VERSION ""

NS_ :

BS_:

BU_: APIM_CISM DSP WCM HUD_ADV ACM GWM _delete APIM IPC GENERIC TSTR

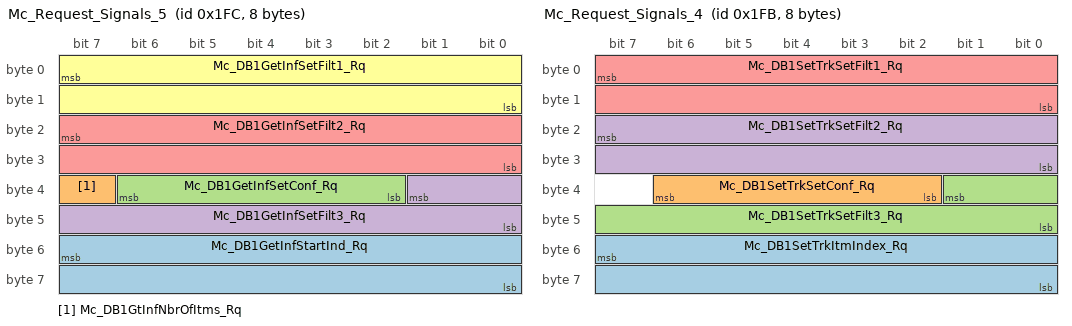
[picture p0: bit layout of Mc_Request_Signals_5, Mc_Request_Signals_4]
BO_ 508 Mc_Request_Signals_5: 8 IPC
 SG_ Mc_DB1GetInfStartInd_Rq : 55|16@0+ (1,0) [0|65535] "unitless"  ACM
 SG_ Mc_DB1GtInfNbrOfItms_Rq : 39|1@0+ (1,0) [0|1] "SED"  ACM
 SG_ Mc_DB1GetInfSetConf_Rq : 38|5@0+ (1,0) [0|31] "SED"  ACM
 SG_ Mc_DB1GetInfSetFilt3_Rq : 33|10@0+ (1,0) [0|1023] "unitless"  ACM
 SG_ Mc_DB1GetInfSetFilt2_Rq : 23|16@0+ (1,0) [0|65535] "unitless"  ACM
 SG_ Mc_DB1GetInfSetFilt1_Rq : 7|16@0+ (1,0) [0|65535] "unitless"  ACM

BO_ 507 Mc_Request_Signals_4: 8 IPC
 SG_ Mc_DB1SetTrkItmIndex_Rq : 55|16@0+ (1,0) [0|65535] "unitless"  ACM
 SG_ Mc_DB1SetTrkSetConf_Rq : 38|5@0+ (1,0) [0|31] "SED"  ACM
 SG_ Mc_DB1SetTrkSetFilt3_Rq : 33|10@0+ (1,0) [0|1023] "unitless"  ACM
 SG_ Mc_DB1SetTrkSetFilt2_Rq : 23|16@0+ (1,0) [0|65535] "unitless"  ACM
 SG_ Mc_DB1SetTrkSetFilt1_Rq : 7|16@0+ (1,0) [0|65535] "unitless"  ACM

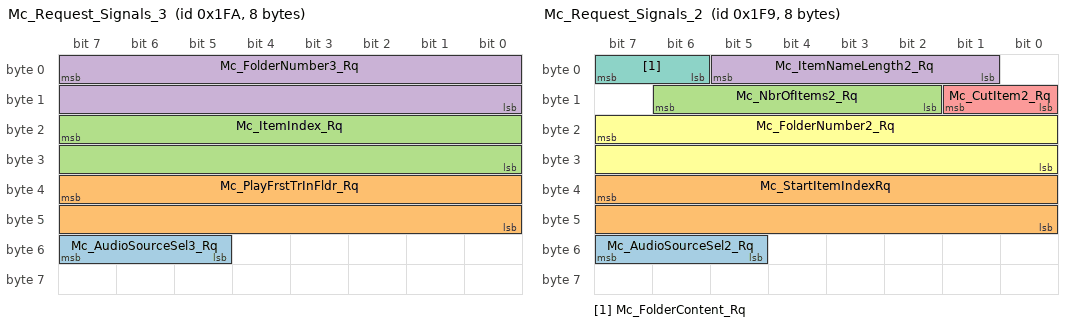
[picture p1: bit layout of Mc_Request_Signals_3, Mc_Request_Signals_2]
BO_ 506 Mc_Request_Signals_3: 8 IPC
 SG_ Mc_AudioSourceSel3_Rq : 55|3@0+ (1,0) [0|7] "SED"  ACM
 SG_ Mc_PlayFrstTrInFldr_Rq : 39|16@0+ (1,0) [0|65535] "unitless"  ACM
 SG_ Mc_ItemIndex_Rq : 23|16@0+ (1,0) [0|65535] "unitless"  ACM
 SG_ Mc_FolderNumber3_Rq : 7|16@0+ (1,0) [0|65535] "unitless"  ACM

BO_ 505 Mc_Request_Signals_2: 8 IPC
 SG_ Mc_AudioSourceSel2_Rq : 55|3@0+ (1,0) [0|7] "SED"  ACM
 SG_ Mc_StartItemIndexRq : 39|16@0+ (1,0) [0|65535] "unitless"  ACM
 SG_ Mc_NbrOfItems2_Rq : 14|5@0+ (1,0) [0|20] "SED"  ACM
 SG_ Mc_ItemNameLength2_Rq : 5|5@0+ (1,0) [0|20] "SED"  ACM
 SG_ Mc_CutItem2_Rq : 9|2@0+ (1,0) [0|3] "SED"  ACM
 SG_ Mc_FolderNumber2_Rq : 23|16@0+ (1,0) [0|65535] "unitless"  ACM
 SG_ Mc_FolderContent_Rq : 7|2@0+ (1,0) [0|3] "SED"  ACM

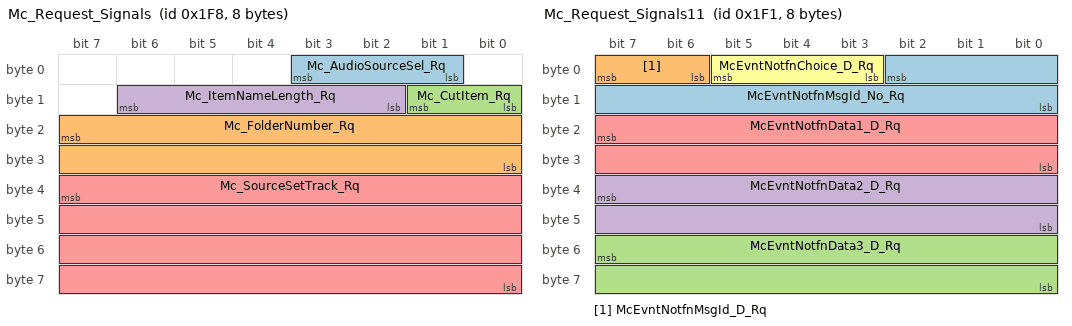
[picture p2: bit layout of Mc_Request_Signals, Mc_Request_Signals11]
BO_ 504 Mc_Request_Signals: 8 IPC
 SG_ Mc_AudioSourceSel_Rq : 3|3@0+ (1,0) [0|7] "SED"  ACM
 SG_ Mc_FolderNumber_Rq : 23|16@0+ (1,0) [0|65535] "unitless"  ACM
 SG_ Mc_CutItem_Rq : 9|2@0+ (1,0) [0|3] "SED"  ACM
 SG_ Mc_ItemNameLength_Rq : 14|5@0+ (1,0) [0|20] "SED"  ACM
 SG_ Mc_SourceSetTrack_Rq : 39|32@0+ (1,0) [0|4294967295] "unitless"  ACM

BO_ 140 CruiseCtrl_StrgData2: 8 IPC
 SG_ DcacPwResetBttn_D_Stat : 36|2@0+ (1,0) [0|3] "SED"  GWM
 SG_ CcAslButtnIndxIncPress2 : 18|1@0+ (1,0) [0|1] "SED"  GWM
 SG_ SteWhlSwtchMde_D_Stat : 23|2@0+ (1,0) [0|3] "SED"  GWM
 SG_ CcAslButtnOffCnclPress2 : 17|1@0+ (1,0) [0|1] "SED"  GWM
 SG_ CcAslButtnIndxDecPress2 : 19|1@0+ (1,0) [0|1] "SED"  GWM
 SG_ CcAslButtnCnclResPress2 : 21|1@0+ (1,0) [0|1] "SED"  GWM
 SG_ CcAslButtnResIncPress3 : 29|1@0+ (1,0) [0|1] "SED"  GWM
 SG_ CcButtnOnPress3 : 37|1@0+ (1,0) [0|1] "SED"  GWM
 SG_ CcButtnOnOffPress3 : 38|1@0+ (1,0) [0|1] "SED"  GWM
 SG_ CcButtnOnOffCnclPress3 : 39|1@0+ (1,0) [0|1] "SED"  GWM
 SG_ CcButtnOffPress3 : 24|1@0+ (1,0) [0|1] "SED"  GWM
 SG_ CcAsllButtnResPress3 : 25|1@0+ (1,0) [0|1] "SED"  GWM
 SG_ CcAslButtnSetPress3 : 26|1@0+ (1,0) [0|1] "SED"  GWM
 SG_ CcAslButtnSetIncPress3 : 27|1@0+ (1,0) [0|1] "SED"  GWM
 SG_ CcAslButtnSetDecPress3 : 28|1@0+ (1,0) [0|1] "SED"  GWM
 SG_ CcAslButtnResDecPress3 : 30|1@0+ (1,0) [0|1] "SED"  GWM
 SG_ CcAslButtnOnPress3 : 31|1@0+ (1,0) [0|1] "SED"  GWM
 SG_ CcAslButtnOnOffCncl3 : 16|1@0+ (1,0) [0|1] "SED"  GWM
 SG_ CcAslButtnDeny_B_Actl3 : 20|1@0+ (1,0) [0|1] "SED"  GWM
 SG_ CcAslButtnCnclPress3 : 8|1@0+ (1,0) [0|1] "SED"  GWM
 SG_ AslButtnOnOffPress3 : 9|1@0+ (1,0) [0|1] "SED"  GWM
 SG_ AslButtnOnOffCnclPress2 : 10|1@0+ (1,0) [0|1] "SED"  GWM

BO_ 813 TimerDisplay_Data2: 8 IPC
 SG_ TimerTripCurnt_T_Dsply : 7|26@0+ (1,0) [0|67108863] "second"  APIM

BO_ 712 NAV_MC_WORD_Rx: 8 IPC
 SG_ NAV_MC_WORD_Rx : 7|64@0+ (1,0) [0|1.84467440737096E+019] "unitless"  APIM_CISM,APIM

BO_ 711 MyKeySrvr_MyKeyClient_Word: 8 IPC
 SG_ MyKeySrvr_MyKeyClient_Word : 7|64@0+ (1,0) [0|1.84467440737096E+019] "unitless" Vector__XXX
 SG_ MyKeySrvr_Clnt_Word_Tx : 7|64@0+ (1,0) [0|1.84467440737096E+019] "unitless"  APIM

BO_ 703 CONMP_MC_WORD_Rx: 8 IPC
 SG_ CONMP_MC_WORD_Rx : 7|64@0+ (1,0) [0|1.84467440737096E+019] "unitless"  APIM_CISM,APIM

BO_ 702 PHONE_MC_WORD_Rx: 8 IPC
 SG_ PHONE_MC_WORD_Rx : 7|64@0+ (1,0) [0|1.84467440737096E+019] "unitless"  APIM_CISM,APIM

BO_ 676 MC_RDISP_WORD_Tx: 8 IPC
 SG_ MC_RDISP_WORD_Tx : 7|64@0+ (1,0) [0|1.84467440737096E+019] "unitless"  APIM_CISM,APIM

BO_ 647 HEC_DispDimm: 8 IPC
 SG_ HEC_BTIncomingCall_Rq : 23|2@0+ (1,0) [0|3] "SED"  APIM_CISM,APIM
 SG_ HEC_BTEndTelService_Rq : 3|2@0+ (1,0) [0|3] "SED"  APIM_CISM,APIM

BO_ 497 Mc_Request_Signals11: 8 IPC
 SG_ McEvntNotfnMsgId_No_Rq : 2|11@0+ (1,0) [0|2047] "unitless"  APIM
 SG_ McEvntNotfnMsgId_D_Rq : 7|2@0+ (1,0) [0|3] "SED"  APIM
 SG_ McEvntNotfnData3_D_Rq : 55|16@0+ (1,0) [0|65535] "unitless"  APIM
 SG_ McEvntNotfnData2_D_Rq : 39|16@0+ (1,0) [0|65535] "unitless"  APIM
 SG_ McEvntNotfnData1_D_Rq : 23|16@0+ (1,0) [0|65535] "unitless"  APIM
 SG_ McEvntNotfnChoice_D_Rq : 5|3@0+ (1,0) [0|7] "SED"  APIM

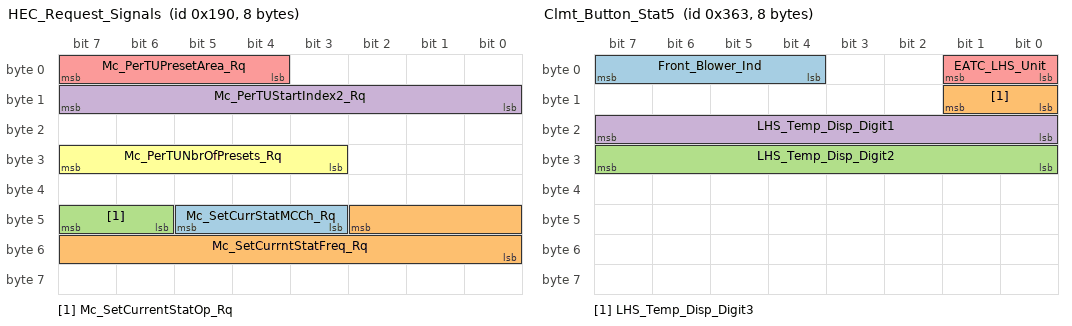
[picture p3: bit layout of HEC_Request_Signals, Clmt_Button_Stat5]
BO_ 400 HEC_Request_Signals: 8 IPC
 SG_ Mc_SetCurrStatMCCh_Rq : 45|3@0+ (1,0) [0|7] "SED"  ACM,GWM
 SG_ Mc_SetCurrntStatFreq_Rq : 42|11@0+ (1,0) [0|1557] "unitless"  ACM,GWM
 SG_ Mc_SetCurrentStatOp_Rq : 47|2@0+ (1,0) [0|3] "SED"  ACM,GWM
 SG_ Mc_PerTUStartIndex2_Rq : 15|8@0+ (1,0) [0|255] "unitless"  ACM,GWM,APIM
 SG_ Mc_PerTUPresetArea_Rq : 7|4@0+ (1,0) [0|15] "SED"  ACM,GWM,APIM
 SG_ Mc_PerTUNbrOfPresets_Rq : 31|5@0+ (1,0) [0|31] "SED"  ACM,GWM,APIM

BO_ 598 CONMP_RSE_WORD_Tx: 8 APIM
 SG_ CONMP_RSE_WORD_Tx : 7|64@0+ (1,0) [0|1.84467440737096E+019] "unitless" Vector__XXX

BO_ 867 Clmt_Button_Stat5: 8 IPC
 SG_ Front_Blower_Ind : 7|4@0+ (1,0) [0|15] "SED"  GWM,HUD_ADV
 SG_ LHS_Temp_Disp_Digit3 : 9|2@0+ (1,0) [0|3] "SED"  GWM,HUD_ADV
 SG_ LHS_Temp_Disp_Digit2 : 31|8@0+ (1,0) [0|255] "ASCII"  GWM,HUD_ADV
 SG_ LHS_Temp_Disp_Digit1 : 23|8@0+ (1,0) [0|255] "ASCII"  GWM,HUD_ADV
 SG_ EATC_LHS_Unit : 1|2@0+ (1,0) [0|3] "SED"  GWM,HUD_ADV

BO_ 831 Pass_Mirror_Sw_StatM: 8 GWM
 SG_ RearDriverWindowPos : 23|3@0+ (1,0) [0|7] "SED"  WCM
 SG_ DriverWindowPosition : 3|3@0+ (1,0) [0|7] "SED"  WCM

BO_ 862 Climate_Control_Data_2: 8 GWM
 SG_ HvacBlwrFront_D_Stat : 55|5@0+ (1,0) [0|31] "SED"  WCM
 SG_ CabnAmb_Te_Actl : 39|8@0+ (0.5,-57) [-57|70] "degreesC"  WCM

BO_ 828 Pass_Window_Stat: 8 GWM
 SG_ RearPassWindowPos : 4|3@0+ (1,0) [0|7] "SED"  WCM
 SG_ PassWindowPosition : 7|3@0+ (1,0) [0|7] "SED"  WCM

BO_ 645 ECG_Data5_HS3: 8 GWM
 SG_ VehImpactCode_No2_Actl : 7|16@0+ (1,0) [0|65535] "unitless"  APIM

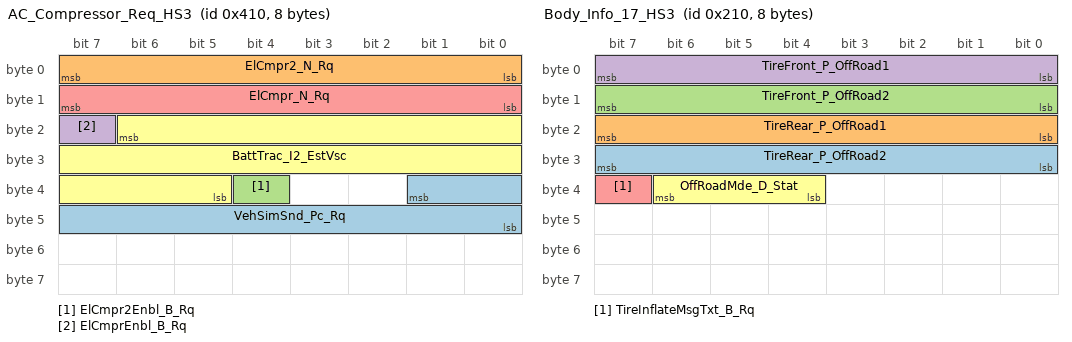
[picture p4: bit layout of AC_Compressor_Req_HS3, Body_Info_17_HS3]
BO_ 1040 AC_Compressor_Req_HS3: 8 GWM
 SG_ VehSimSnd_Pc_Rq : 33|10@0+ (0.2,-102.2) [-102.2|102.4] "percent"  ACM
 SG_ ElCmpr2_N_Rq : 7|8@0+ (50,0) [0|12750] "RPM" Vector__XXX
 SG_ ElCmpr2Enbl_B_Rq : 36|1@0+ (1,0) [0|1] "SED" Vector__XXX
 SG_ ElCmprEnbl_B_Rq : 23|1@0+ (1,0) [0|1] "SED" Vector__XXX
 SG_ ElCmpr_N_Rq : 15|8@0+ (50,0) [0|12750] "RPM" Vector__XXX
 SG_ BattTrac_I2_EstVsc : 22|18@0+ (0.05,-6553.52) [-6553.52|6553.53] "ampere" Vector__XXX

BO_ 528 Body_Info_17_HS3: 8 GWM
 SG_ TireRear_P_OffRoad2 : 31|8@0+ (1,0) [0|255] "pounds/inch^2"  IPC
 SG_ TireRear_P_OffRoad1 : 23|8@0+ (1,0) [0|255] "pounds/inch^2"  IPC
 SG_ TireFront_P_OffRoad2 : 15|8@0+ (1,0) [0|255] "pounds/inch^2"  IPC
 SG_ TireFront_P_OffRoad1 : 7|8@0+ (1,0) [0|255] "pounds/inch^2"  IPC
 SG_ TireInflateMsgTxt_B_Rq : 39|1@0+ (1,0) [0|1] "SED"  IPC
 SG_ OffRoadMde_D_Stat : 38|3@0+ (1,0) [0|7] "SED"  IPC

BO_ 1221 HEV_Data_Monitor_22_HS3: 8 GWM
 SG_ BattTracUMxArry_No_Actl : 52|5@0+ (1,0) [0|30] "unitless"  GENERIC
 SG_ BattTracCellUMx_No_Actl : 63|8@0+ (1,0) [0|253] "Unitless"  GENERIC
 SG_ BattChrgUMx_B_Falt : 53|1@0+ (1,0) [0|1] "SED"  GENERIC
 SG_ BattTracCellUMn_No_Actl : 15|8@0+ (1,0) [0|253] "Unitless"  GENERIC
 SG_ BattTracCellCnt_No_Actl : 7|8@0+ (1,0) [0|253] "Unitless"  GENERIC
 SG_ BattChrgIsltn_B_Falt : 47|1@0+ (1,0) [0|1] "SED"  GENERIC
 SG_ BattTracCellDiff_B_Falt : 43|1@0+ (1,0) [0|1] "SED"  GENERIC
 SG_ BattChrgSocMx_B_Falt : 44|1@0+ (1,0) [0|1] "SED"  APIM
 SG_ BattChrgSocMn_B_Falt : 45|1@0+ (1,0) [0|1] "SED"  APIM
 SG_ BattChrgSocErrtc_B_Falt : 46|1@0+ (1,0) [0|1] "SED"  GENERIC
 SG_ BattTracUMx_B_Falt : 54|1@0+ (1,0) [0|1] "SED"  GENERIC
 SG_ BattTracUMn_B_Falt : 55|1@0+ (1,0) [0|1] "SED"  GENERIC
 SG_ BattTracTeMx_No_Actl : 39|8@0+ (1,0) [0|253] "Unitless"  GENERIC
 SG_ BattTracTeMx_B_Falt : 40|1@0+ (1,0) [0|1] "SED"  GENERIC
 SG_ BattTracTeMn_No_Actl : 31|8@0+ (1,0) [0|253] "Unitless"  GENERIC
 SG_ BattTracTeDelta_B_Falt : 41|1@0+ (1,0) [0|1] "SED"  GENERIC
 SG_ BattTracTeCnt_No_Actl : 23|8@0+ (1,0) [0|253] "Unitless"  GENERIC
 SG_ BattTracSoftware_B_Falt : 42|1@0+ (1,0) [0|1] "SED"  GENERIC

BO_ 595 APIM_Send_Signals_7: 8 APIM
 SG_ DrvIdMde_D_Rq : 7|3@0+ (1,0) [0|7] "SED"  GWM
 SG_ DrvIdDelete_No_Rq : 15|32@0+ (1,0) [0|4294967295] "Unitless"  GWM

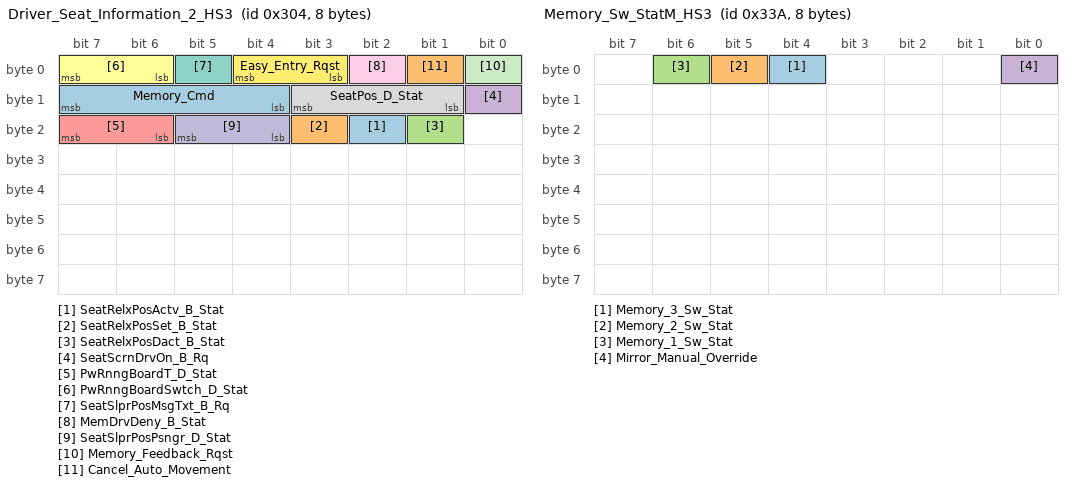
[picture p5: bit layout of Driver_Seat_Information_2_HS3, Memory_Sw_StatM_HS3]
BO_ 772 Driver_Seat_Information_2_HS3: 8 GWM
 SG_ SeatRelxPosActv_B_Stat : 18|1@0+ (1,0) [0|1] "SED"  APIM_CISM
 SG_ SeatRelxPosSet_B_Stat : 19|1@0+ (1,0) [0|1] "SED"  APIM_CISM
 SG_ SeatRelxPosDact_B_Stat : 17|1@0+ (1,0) [0|1] "SED"  APIM_CISM
 SG_ SeatScrnDrvOn_B_Rq : 8|1@0+ (1,0) [0|1] "SED"  GENERIC
 SG_ PwRnngBoardT_D_Stat : 23|2@0+ (1,0) [0|3] "SED"  GENERIC
 SG_ PwRnngBoardSwtch_D_Stat : 7|2@0+ (1,0) [0|3] "SED"  GENERIC
 SG_ SeatSlprPosMsgTxt_B_Rq : 5|1@0+ (1,0) [0|1] "SED"  GENERIC
 SG_ SeatPos_D_Stat : 11|3@0+ (1,0) [0|7] "SED"  GENERIC
 SG_ MemDrvDeny_B_Stat : 2|1@0+ (1,0) [0|1] "SED"  GENERIC
 SG_ SeatSlprPosPsngr_D_Stat : 21|2@0+ (1,0) [0|3] "SED"  GENERIC
 SG_ Memory_Feedback_Rqst : 0|1@0+ (1,0) [0|1] "SED"  GENERIC
 SG_ Easy_Entry_Rqst : 4|2@0+ (1,0) [0|3] "SED"  GENERIC
 SG_ Memory_Cmd : 15|4@0+ (1,0) [0|15] "SED"  HUD_ADV,GENERIC
 SG_ Cancel_Auto_Movement : 1|1@0+ (1,0) [0|1] "SED"  APIM_CISM,GENERIC

BO_ 826 Memory_Sw_StatM_HS3: 8 GWM
 SG_ Memory_3_Sw_Stat : 4|1@0+ (1,0) [0|1] "SED"  GENERIC
 SG_ Memory_2_Sw_Stat : 5|1@0+ (1,0) [0|1] "SED"  GENERIC
 SG_ Memory_1_Sw_Stat : 6|1@0+ (1,0) [0|1] "SED"  GENERIC
 SG_ Mirror_Manual_Override : 0|1@0+ (1,0) [0|1] "SED"  APIM_CISM,GENERIC

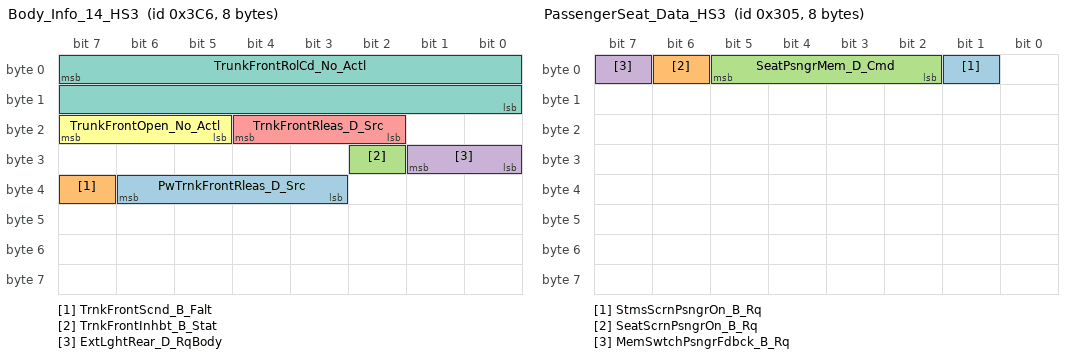
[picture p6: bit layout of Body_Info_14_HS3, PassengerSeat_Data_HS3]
BO_ 966 Body_Info_14_HS3: 8 GWM
 SG_ PwTrnkFrontRleas_D_Src : 38|4@0+ (1,0) [0|15] "SED"  GENERIC
 SG_ TrnkFrontScnd_B_Falt : 39|1@0+ (1,0) [0|1] "SED"  IPC
 SG_ TrnkFrontInhbt_B_Stat : 26|1@0+ (1,0) [0|1] "SED"  GENERIC
 SG_ ExtLghtRear_D_RqBody : 25|2@0- (1,0) [0|3] "SED"  GENERIC
 SG_ TrnkFrontRleas_D_Src : 20|3@0+ (1,0) [0|7] "SED"  GENERIC
 SG_ TrunkFrontOpen_No_Actl : 23|3@0+ (1,0) [0|7] "unitless"  GENERIC
 SG_ TrunkFrontRolCd_No_Actl : 7|16@0+ (1,0) [0|65535] "unitless"  GENERIC

BO_ 773 PassengerSeat_Data_HS3: 8 GWM
 SG_ StmsScrnPsngrOn_B_Rq : 1|1@0+ (1,0) [0|1] "SED"  APIM
 SG_ SeatScrnPsngrOn_B_Rq : 6|1@0+ (1,0) [0|1] "SED"  GENERIC
 SG_ SeatPsngrMem_D_Cmd : 5|4@0+ (1,0) [0|15] "SED"  GENERIC
 SG_ MemSwtchPsngrFdbck_B_Rq : 7|1@0+ (1,0) [0|1] "SED"  GENERIC

BO_ 303 Body_Info_16_HS3: 8 GWM
 SG_ CanMsg12F_No_Crc : 7|8@0+ (1,0) [0|255] "Unitless"  GENERIC
 SG_ CanMsg12F_No_Cnt : 11|4@0+ (1,0) [0|15] "Unitless"  GENERIC
 SG_ DrStatHood_D2_Actl : 23|3@0+ (1,0) [0|7] "SED"  IPC

BO_ 2612009176 PARSEDPushFcGWM_ECGtoHUD: 8 GWM
 SG_ PARSEDPushFcGWM_ECGtoHUD : 7|29@0+ (1,0) [0|536870911] "unitless"  HUD_ADV

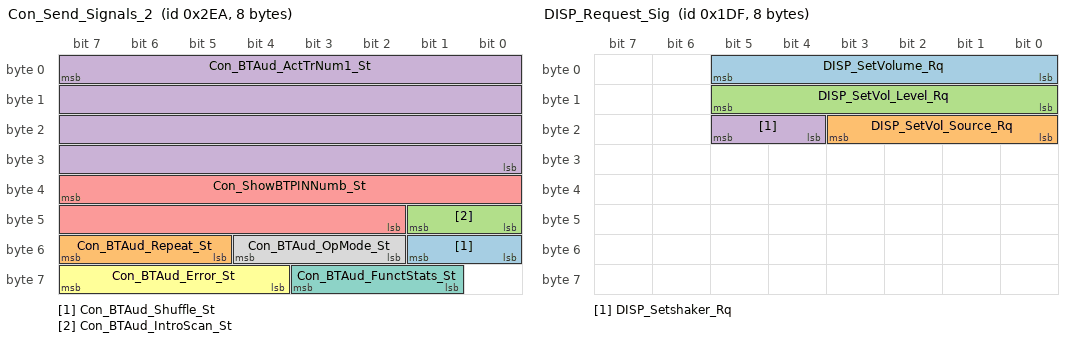
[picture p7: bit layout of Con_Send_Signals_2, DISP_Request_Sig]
BO_ 746 Con_Send_Signals_2: 8 ACM
 SG_ Con_BTAud_Shuffle_St : 49|2@0+ (1,0) [0|3] "SED"  IPC
 SG_ Con_BTAud_Repeat_St : 55|3@0+ (1,0) [0|7] "SED"  IPC
 SG_ Con_BTAud_IntroScan_St : 41|2@0+ (1,0) [0|3] "SED"  IPC
 SG_ Con_BTAud_ActTrNum1_St : 7|32@0+ (1,0) [0|4294967295] ""  IPC
 SG_ Con_ShowBTPINNumb_St : 39|14@0+ (1,0) [0|16383] ""  IPC
 SG_ Con_BTAud_Error_St : 63|4@0+ (1,0) [0|15] "SED" Vector__XXX
 SG_ Con_BTAud_FunctStats_St : 59|3@0+ (1,0) [0|7] "SED"  IPC
 SG_ Con_BTAud_OpMode_St : 52|3@0+ (1,0) [0|7] "SED"  IPC

BO_ 479 DISP_Request_Sig: 8 APIM
 SG_ DISP_SetVolume_Rq : 5|6@0+ (1,-30) [-30|33] "steps"  ACM,DSP,GWM
 SG_ DISP_SetVol_Source_Rq : 19|4@0+ (1,0) [0|15] "SED"  IPC,ACM,DSP
 SG_ DISP_SetVol_Level_Rq : 13|6@0+ (1,0) [0|63] "unitless"  ACM,DSP
 SG_ DISP_Setshaker_Rq : 21|2@0+ (1,0) [0|3] "SED"  ACM,DSP

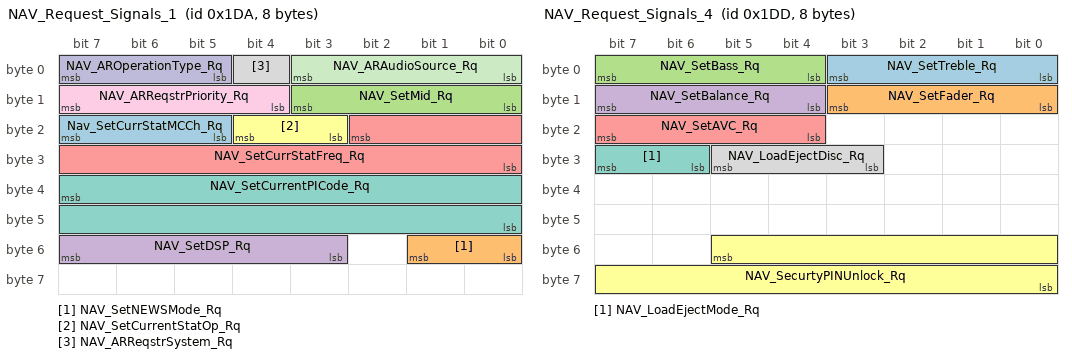
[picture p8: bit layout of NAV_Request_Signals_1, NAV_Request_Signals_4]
BO_ 474 NAV_Request_Signals_1: 8 APIM
 SG_ Nav_SetCurrStatMCCh_Rq : 23|3@0+ (1,0) [0|7] "SED"  ACM
 SG_ NAV_SetNEWSMode_Rq : 49|2@0+ (1,0) [0|3] "SED"  ACM
 SG_ NAV_SetMid_Rq : 11|4@0+ (1,-7) [-7|8] "SED"  DSP,ACM
 SG_ NAV_SetDSP_Rq : 55|5@0+ (1,0) [0|31] "SED"  ACM
 SG_ NAV_SetCurrStatFreq_Rq : 18|11@0+ (1,0) [0|1557] "unitless"  ACM
 SG_ NAV_SetCurrentStatOp_Rq : 20|2@0+ (1,0) [0|3] "SED"  ACM
 SG_ NAV_SetCurrentPICode_Rq : 39|16@0+ (1,0) [0|65535] "unitless"  ACM
 SG_ NAV_ARReqstrSystem_Rq : 4|1@0+ (1,0) [0|1] "SED"  DSP,ACM
 SG_ NAV_ARReqstrPriority_Rq : 15|4@0+ (1,0) [0|15] "SED"  DSP,ACM
 SG_ NAV_AROperationType_Rq : 7|3@0+ (1,0) [0|7] "SED"  DSP,ACM
 SG_ NAV_ARAudioSource_Rq : 3|4@0+ (1,0) [0|15] "SED"  DSP,ACM

BO_ 477 NAV_Request_Signals_4: 8 APIM
 SG_ NAV_SetTreble_Rq : 3|4@0+ (1,-7) [-7|8] "SED"  ACM,DSP
 SG_ NAV_SetFader_Rq : 11|4@0+ (1,-7) [-7|8] "SED"  ACM,DSP
 SG_ NAV_SetBass_Rq : 7|4@0+ (1,-7) [-7|8] "SED"  ACM,DSP
 SG_ NAV_SetBalance_Rq : 15|4@0+ (1,-7) [-7|8] "SED"  ACM,DSP
 SG_ NAV_SetAVC_Rq : 23|4@0+ (1,0) [0|15] "SED"  ACM,DSP
 SG_ NAV_SecurtyPINUnlock_Rq : 53|14@0+ (1,0) [0|16383] "unitless"  ACM
 SG_ NAV_LoadEjectMode_Rq : 31|2@0+ (1,0) [0|3] "SED"  ACM
 SG_ NAV_LoadEjectDisc_Rq : 29|3@0+ (1,0) [0|7] "SED"  ACM

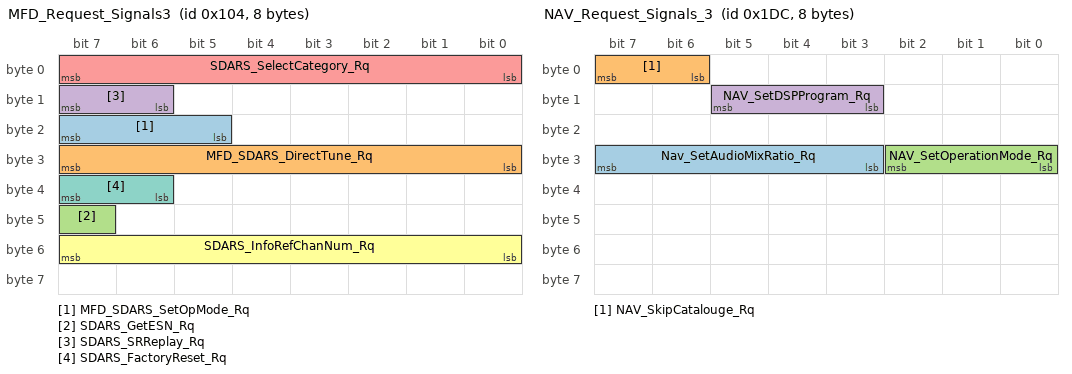
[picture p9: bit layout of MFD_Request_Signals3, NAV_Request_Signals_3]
BO_ 260 MFD_Request_Signals3: 8 APIM
 SG_ MFD_SDARS_SetOpMode_Rq : 23|3@0+ (1,0) [0|7] "SED"  ACM
 SG_ MFD_SDARS_DirectTune_Rq : 31|8@0+ (1,0) [0|255] "unitless"  ACM
 SG_ SDARS_GetESN_Rq : 47|1@0+ (1,0) [0|1] "SED"  ACM
 SG_ SDARS_SRReplay_Rq : 15|2@0+ (1,0) [0|3] "SED"  ACM
 SG_ SDARS_SelectCategory_Rq : 7|8@0+ (1,0) [0|255] "unitless"  ACM
 SG_ SDARS_InfoRefChanNum_Rq : 55|8@0+ (1,0) [0|255] "unitless"  ACM
 SG_ SDARS_FactoryReset_Rq : 39|2@0+ (1,0) [0|3] "SED"  DSP,ACM

BO_ 476 NAV_Request_Signals_3: 8 APIM
 SG_ Nav_SetAudioMixRatio_Rq : 31|5@0+ (1,0) [0|20] "decibel"  ACM
 SG_ NAV_SkipCatalouge_Rq : 7|2@0+ (1,0) [0|3] "SED"  ACM
 SG_ NAV_SetOperationMode_Rq : 26|3@0+ (1,0) [0|7] "SED"  ACM
 SG_ NAV_SetDSPProgram_Rq : 13|3@0+ (1,0) [0|7] "SED"  ACM

BO_ 490 HMI_Request_Signals_2: 8 APIM
 SG_ HMI_SetCompression_Rq : 9|2@0+ (1,0) [0|3] "SED"  ACM
 SG_ HMI_SkipTrack_Rq : 35|2@0+ (1,0) [0|3] "SED"  ACM

BO_ 1923 TesterPhysicalReqDSP: 8 TSTR
 SG_ TesterPhysicalReqDSP : 7|64@0+ (1,0) [0|1.84467E+019] "unitless"  DSP

BO_ 1931 TesterPhysicalResDSP: 8 DSP
 SG_ TesterPhysicalResDSP : 7|64@0+ (1,0) [0|1.84467E+019] "unitless"  TSTR

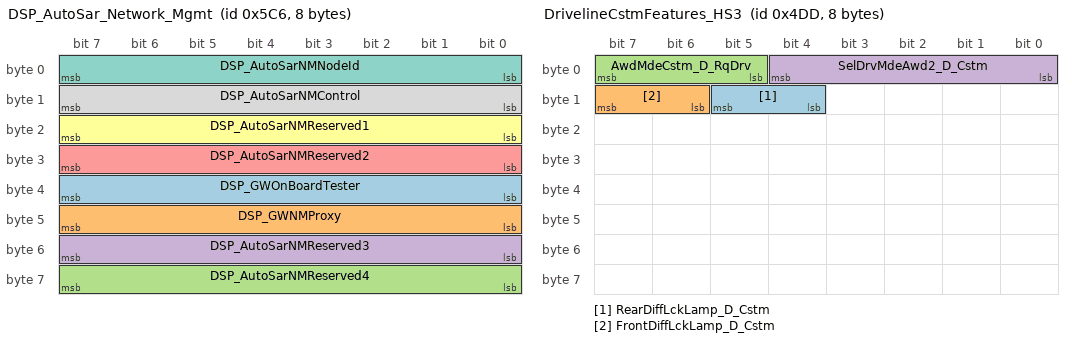
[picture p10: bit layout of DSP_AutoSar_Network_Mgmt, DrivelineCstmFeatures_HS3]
BO_ 1478 DSP_AutoSar_Network_Mgmt: 8 DSP
 SG_ DSP_GWOnBoardTester : 39|8@0+ (1,0) [0|255] "unitless"  IPC,HUD_ADV
 SG_ DSP_GWNMProxy : 47|8@0+ (1,0) [0|255] "unitless"  IPC,HUD_ADV
 SG_ DSP_AutoSarNMReserved4 : 63|8@0+ (1,0) [0|255] "unitless"  IPC,HUD_ADV
 SG_ DSP_AutoSarNMReserved3 : 55|8@0+ (1,0) [0|255] "unitless"  IPC,HUD_ADV
 SG_ DSP_AutoSarNMReserved2 : 31|8@0+ (1,0) [0|255] "unitless"  IPC,HUD_ADV
 SG_ DSP_AutoSarNMReserved1 : 23|8@0+ (1,0) [0|255] "unitless"  IPC,HUD_ADV
 SG_ DSP_AutoSarNMNodeId : 7|8@0+ (1,0) [0|255] "unitless"  IPC,HUD_ADV
 SG_ DSP_AutoSarNMControl : 15|8@0+ (1,0) [0|255] "unitless"  IPC,HUD_ADV

BO_ 1245 DrivelineCstmFeatures_HS3: 8 GWM
 SG_ RearDiffLckLamp_D_Cstm : 13|2@0+ (1,0) [0|3] "SED"  IPC
 SG_ FrontDiffLckLamp_D_Cstm : 15|2@0+ (1,0) [0|3] "SED"  IPC
 SG_ AwdMdeCstm_D_RqDrv : 7|3@0+ (1,0) [0|7] "SED"  IPC
 SG_ SelDrvMdeAwd2_D_Cstm : 4|5@0+ (1,0) [0|31] "SED"  GENERIC

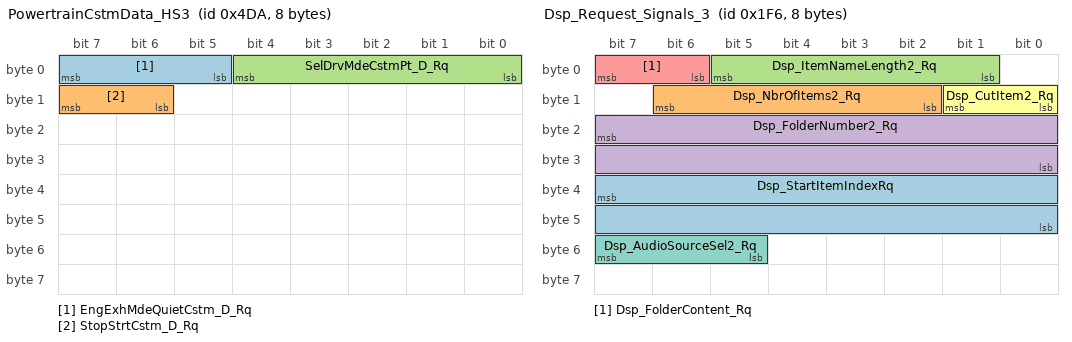
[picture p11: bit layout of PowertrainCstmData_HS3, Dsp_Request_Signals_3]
BO_ 1242 PowertrainCstmData_HS3: 8 GWM
 SG_ EngExhMdeQuietCstm_D_Rq : 7|3@0+ (1,0) [0|7] "SED"  IPC
 SG_ StopStrtCstm_D_Rq : 15|2@0+ (1,0) [0|3] "SED"  IPC
 SG_ SelDrvMdeCstmPt_D_Rq : 4|5@0+ (1,0) [0|31] "SED"  GENERIC

BO_ 502 Dsp_Request_Signals_3: 8 APIM
 SG_ Dsp_StartItemIndexRq : 39|16@0+ (1,0) [0|65535] "unitless"  ACM
 SG_ Dsp_NbrOfItems2_Rq : 14|5@0+ (1,0) [0|20] "SED"  ACM
 SG_ Dsp_ItemNameLength2_Rq : 5|5@0+ (1,0) [0|20] "SED"  ACM
 SG_ Dsp_FolderNumber2_Rq : 23|16@0+ (1,0) [0|65535] "unitless"  ACM
 SG_ Dsp_FolderContent_Rq : 7|2@0+ (1,0) [0|3] "SED"  ACM
 SG_ Dsp_CutItem2_Rq : 9|2@0+ (1,0) [0|3] "SED"  ACM
 SG_ Dsp_AudioSourceSel2_Rq : 55|3@0+ (1,0) [0|7] "SED"  ACM

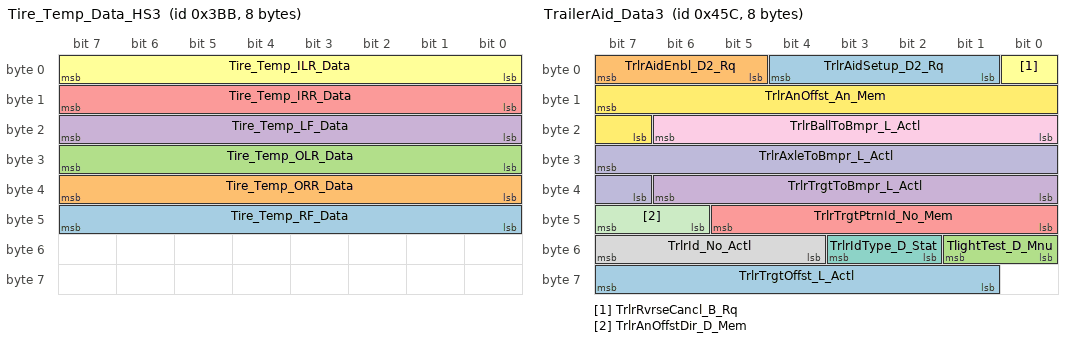
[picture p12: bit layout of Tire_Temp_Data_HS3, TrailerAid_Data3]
BO_ 955 Tire_Temp_Data_HS3: 8 GWM
 SG_ Tire_Temp_RF_Data : 47|8@0+ (1,-60) [-60|193] "degC"  IPC,APIM
 SG_ Tire_Temp_ORR_Data : 39|8@0+ (1,-60) [-60|193] "degC"  IPC,APIM
 SG_ Tire_Temp_OLR_Data : 31|8@0+ (1,-60) [-60|193] "degC"  IPC,APIM
 SG_ Tire_Temp_LF_Data : 23|8@0+ (1,-60) [-60|193] "degC"  IPC,APIM
 SG_ Tire_Temp_IRR_Data : 15|8@0+ (1,-60) [-60|193] "degC"  IPC,APIM
 SG_ Tire_Temp_ILR_Data : 7|8@0+ (1,-60) [-60|193] "degC"  IPC,APIM

BO_ 1116 TrailerAid_Data3: 8 APIM
 SG_ TrlrAidSetup_D2_Rq : 4|4@0+ (1,0) [0|15] "SED"  GWM
 SG_ TrlrAidEnbl_D2_Rq : 7|3@0+ (1,0) [0|7] "SED"  GWM
 SG_ TlightTest_D_Mnu : 49|2@0+ (1,0) [0|3] "SED"  GWM
 SG_ TrlrTrgtToBmpr_L_Actl : 38|7@0+ (0.0127,0) [0|1.6129] "meter"  GWM
 SG_ TrlrTrgtPtrnId_No_Mem : 45|6@0+ (1,0) [0|63] "unitless"  GWM
 SG_ TrlrRvrseCancl_B_Rq : 0|1@0+ (1,0) [0|1] "SED"  GWM
 SG_ TrlrIdType_D_Stat : 51|2@0+ (1,0) [0|3] "SED"  GWM
 SG_ TrlrId_No_Actl : 55|4@0+ (1,0) [0|15] "unitless"  GWM
 SG_ TrlrBallToBmpr_L_Actl : 22|7@0+ (0.0127,0) [0|1.6129] "meter"  GWM
 SG_ TrlrAxleToBmpr_L_Actl : 31|9@0+ (0.0254,0) [0|12.9794] "meter"  GWM
 SG_ TrlrAnOffstDir_D_Mem : 47|2@0+ (1,0) [0|3] "SED"  GWM
 SG_ TrlrAnOffst_An_Mem : 15|9@0+ (0.1,0) [0|51.1] "degrees"  GWM
 SG_ TrlrTrgtOffst_L_Actl : 63|7@0+ (0.0127,0) [0|1.6129] "meter"  GWM

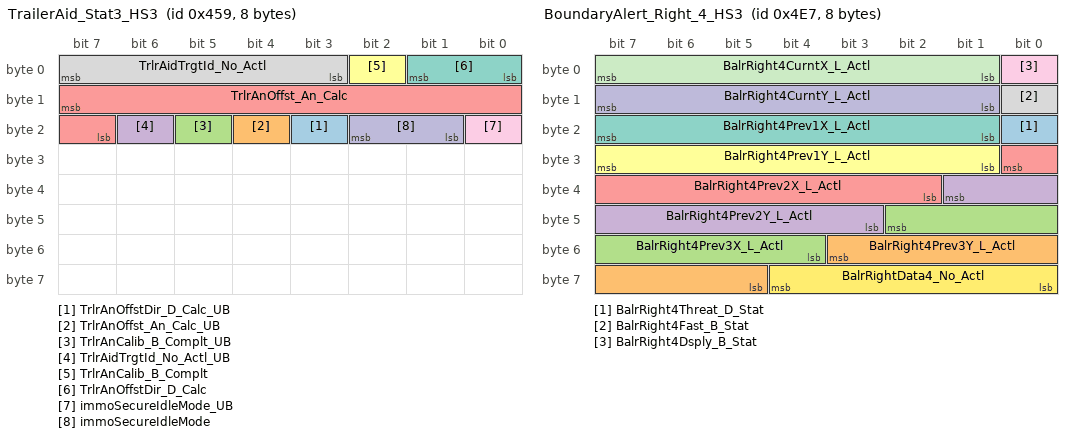
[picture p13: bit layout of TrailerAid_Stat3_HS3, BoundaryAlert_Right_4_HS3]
BO_ 1113 TrailerAid_Stat3_HS3: 8 GWM
 SG_ TrlrAnOffstDir_D_Calc_UB : 19|1@0+ (1,0) [0|1] "SED"  IPC,APIM
 SG_ TrlrAnOffst_An_Calc_UB : 20|1@0+ (1,0) [0|1] "SED"  IPC,APIM
 SG_ TrlrAnCalib_B_Complt_UB : 21|1@0+ (1,0) [0|1] "SED"  IPC,APIM
 SG_ TrlrAidTrgtId_No_Actl_UB : 22|1@0+ (1,0) [0|1] "SED"  IPC,APIM
 SG_ TrlrAnOffst_An_Calc : 15|9@0+ (0.1,0) [0|51.1] "degrees"  IPC,APIM
 SG_ TrlrAnCalib_B_Complt : 2|1@0+ (1,0) [0|1] "SED"  IPC,APIM
 SG_ TrlrAnOffstDir_D_Calc : 1|2@0+ (1,0) [0|3] "SED"  IPC,APIM
 SG_ TrlrAidTrgtId_No_Actl : 7|5@0+ (1,0) [0|31] "unitless"  IPC,APIM
 SG_ immoSecureIdleMode_UB : 16|1@0+ (1,0) [0|1] "SED"  APIM_CISM,IPC,APIM
 SG_ immoSecureIdleMode : 18|2@0+ (1,0) [0|3] "SED"  APIM_CISM,IPC,APIM

BO_ 1255 BoundaryAlert_Right_4_HS3: 8 GWM
 SG_ BalrRight4Threat_D_Stat : 16|1@0+ (1,0) [0|1] "SED"  IPC
 SG_ BalrRight4Prev3Y_L_Actl : 51|7@0+ (0.5,-32) [-32|31.5] "meter"  IPC
 SG_ BalrRight4Prev3X_L_Actl : 42|7@0+ (0.5,-32) [-32|31.5] "meter"  IPC
 SG_ BalrRight4Prev2Y_L_Actl : 33|7@0+ (0.5,-32) [-32|31.5] "meter"  IPC
 SG_ BalrRight4Prev2X_L_Actl : 24|7@0+ (0.5,-32) [-32|31.5] "meter"  IPC
 SG_ BalrRight4Prev1Y_L_Actl : 31|7@0+ (0.5,-32) [-32|31.5] "meter"  IPC
 SG_ BalrRight4Prev1X_L_Actl : 23|7@0+ (0.5,-32) [-32|31.5] "meter"  IPC
 SG_ BalrRight4Fast_B_Stat : 8|1@0+ (1,0) [0|1] "SED"  IPC
 SG_ BalrRight4Dsply_B_Stat : 0|1@0+ (1,0) [0|1] "SED"  IPC
 SG_ BalrRight4CurntY_L_Actl : 15|7@0+ (0.5,-32) [-32|31.5] "meter"  IPC
 SG_ BalrRight4CurntX_L_Actl : 7|7@0+ (0.5,-32) [-32|31.5] "meter"  IPC
 SG_ BalrRightData4_No_Actl : 60|5@0+ (1,0) [0|31] "unitless"  IPC

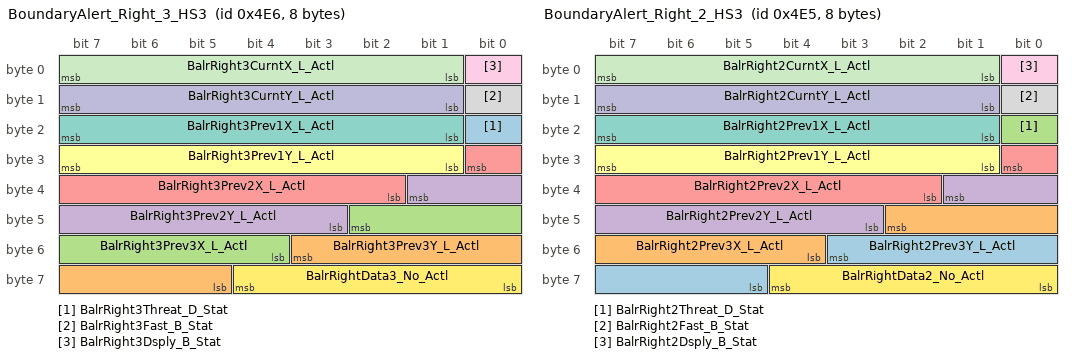
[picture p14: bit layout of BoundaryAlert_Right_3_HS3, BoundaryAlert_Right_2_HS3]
BO_ 1254 BoundaryAlert_Right_3_HS3: 8 GWM
 SG_ BalrRight3Threat_D_Stat : 16|1@0+ (1,0) [0|1] "SED"  IPC
 SG_ BalrRight3Prev3Y_L_Actl : 51|7@0+ (0.5,-32) [-32|31.5] "meter"  IPC
 SG_ BalrRight3Prev3X_L_Actl : 42|7@0+ (0.5,-32) [-32|31.5] "meter"  IPC
 SG_ BalrRight3Prev2Y_L_Actl : 33|7@0+ (0.5,-32) [-32|31.5] "meter"  IPC
 SG_ BalrRight3Prev2X_L_Actl : 24|7@0+ (0.5,-32) [-32|31.5] "meter"  IPC
 SG_ BalrRight3Prev1Y_L_Actl : 31|7@0+ (0.5,-32) [-32|31.5] "meter"  IPC
 SG_ BalrRight3Prev1X_L_Actl : 23|7@0+ (0.5,-32) [-32|31.5] "meter"  IPC
 SG_ BalrRight3Fast_B_Stat : 8|1@0+ (1,0) [0|1] "SED"  IPC
 SG_ BalrRight3Dsply_B_Stat : 0|1@0+ (1,0) [0|1] "SED"  IPC
 SG_ BalrRight3CurntY_L_Actl : 15|7@0+ (0.5,-32) [-32|31.5] "meter"  IPC
 SG_ BalrRight3CurntX_L_Actl : 7|7@0+ (0.5,-32) [-32|31.5] "meter"  IPC
 SG_ BalrRightData3_No_Actl : 60|5@0+ (1,0) [0|31] "unitless"  IPC

BO_ 1253 BoundaryAlert_Right_2_HS3: 8 GWM
 SG_ BalrRight2Prev3Y_L_Actl : 51|7@0+ (0.5,-32) [-32|31.5] "meter"  IPC
 SG_ BalrRight2Prev3X_L_Actl : 42|7@0+ (0.5,-32) [-32|31.5] "meter"  IPC
 SG_ BalrRight2Threat_D_Stat : 16|1@0+ (1,0) [0|1] "SED"  IPC
 SG_ BalrRight2Prev2Y_L_Actl : 33|7@0+ (0.5,-32) [-32|31.5] "meter"  IPC
 SG_ BalrRight2Prev2X_L_Actl : 24|7@0+ (0.5,-32) [-32|31.5] "meter"  IPC
 SG_ BalrRight2Prev1Y_L_Actl : 31|7@0+ (0.5,-32) [-32|31.5] "meter"  IPC
 SG_ BalrRight2Prev1X_L_Actl : 23|7@0+ (0.5,-32) [-32|31.5] "meter"  IPC
 SG_ BalrRight2Fast_B_Stat : 8|1@0+ (1,0) [0|1] "SED"  IPC
 SG_ BalrRight2Dsply_B_Stat : 0|1@0+ (1,0) [0|1] "SED"  IPC
 SG_ BalrRight2CurntY_L_Actl : 15|7@0+ (0.5,-32) [-32|31.5] "meter"  IPC
 SG_ BalrRight2CurntX_L_Actl : 7|7@0+ (0.5,-32) [-32|31.5] "meter"  IPC
 SG_ BalrRightData2_No_Actl : 60|5@0+ (1,0) [0|31] "unitless"  IPC

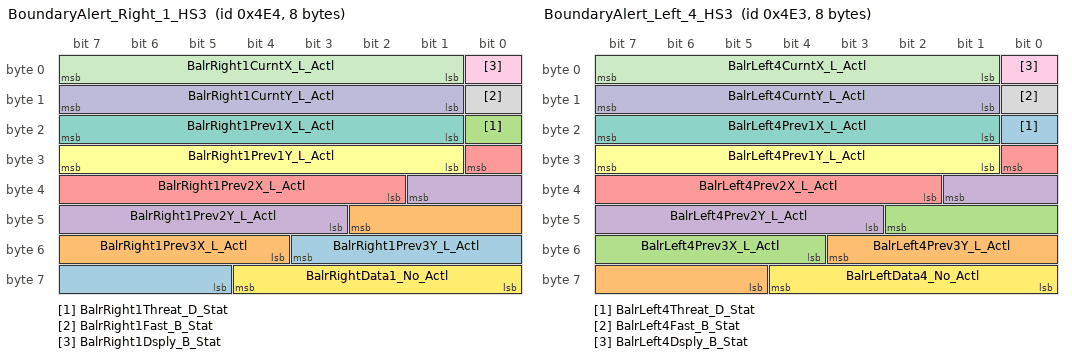
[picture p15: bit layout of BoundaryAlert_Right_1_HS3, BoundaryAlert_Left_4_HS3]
BO_ 1252 BoundaryAlert_Right_1_HS3: 8 GWM
 SG_ BalrRight1Prev3Y_L_Actl : 51|7@0+ (0.5,-32) [-32|31.5] "meter"  IPC
 SG_ BalrRight1Prev3X_L_Actl : 42|7@0+ (0.5,-32) [-32|31.5] "meter"  IPC
 SG_ BalrRight1Threat_D_Stat : 16|1@0+ (1,0) [0|1] "SED"  IPC
 SG_ BalrRight1Prev2Y_L_Actl : 33|7@0+ (0.5,-32) [-32|31.5] "meter"  IPC
 SG_ BalrRight1Prev2X_L_Actl : 24|7@0+ (0.5,-32) [-32|31.5] "meter"  IPC
 SG_ BalrRight1Prev1Y_L_Actl : 31|7@0+ (0.5,-32) [-32|31.5] "meter"  IPC
 SG_ BalrRight1Prev1X_L_Actl : 23|7@0+ (0.5,-32) [-32|31.5] "meter"  IPC
 SG_ BalrRight1Fast_B_Stat : 8|1@0+ (1,0) [0|1] "SED"  IPC
 SG_ BalrRight1Dsply_B_Stat : 0|1@0+ (1,0) [0|1] "SED"  IPC
 SG_ BalrRight1CurntY_L_Actl : 15|7@0+ (0.5,-32) [-32|31.5] "meter"  IPC
 SG_ BalrRight1CurntX_L_Actl : 7|7@0+ (0.5,-32) [-32|31.5] "meter"  IPC
 SG_ BalrRightData1_No_Actl : 60|5@0+ (1,0) [0|31] "unitless"  IPC

BO_ 1251 BoundaryAlert_Left_4_HS3: 8 GWM
 SG_ BalrLeft4Threat_D_Stat : 16|1@0+ (1,0) [0|1] "SED"  IPC
 SG_ BalrLeft4Prev3Y_L_Actl : 51|7@0+ (0.5,-32) [-32|31.5] "meter"  IPC
 SG_ BalrLeft4Prev3X_L_Actl : 42|7@0+ (0.5,-32) [-32|31.5] "meter"  IPC
 SG_ BalrLeft4Prev2Y_L_Actl : 33|7@0+ (0.5,-32) [-32|31.5] "meter"  IPC
 SG_ BalrLeft4Prev2X_L_Actl : 24|7@0+ (0.5,-32) [-32|31.5] "meter"  IPC
 SG_ BalrLeft4Prev1Y_L_Actl : 31|7@0+ (0.5,-32) [-32|31.5] "meter"  IPC
 SG_ BalrLeft4Prev1X_L_Actl : 23|7@0+ (0.5,-32) [-32|31.5] "meter"  IPC
 SG_ BalrLeft4Fast_B_Stat : 8|1@0+ (1,0) [0|1] "SED"  IPC
 SG_ BalrLeft4Dsply_B_Stat : 0|1@0+ (1,0) [0|1] "SED"  IPC
 SG_ BalrLeft4CurntY_L_Actl : 15|7@0+ (0.5,-32) [-32|31.5] "meter"  IPC
 SG_ BalrLeft4CurntX_L_Actl : 7|7@0+ (0.5,-32) [-32|31.5] "meter"  IPC
 SG_ BalrLeftData4_No_Actl : 60|5@0+ (1,0) [0|31] "unitless"  IPC

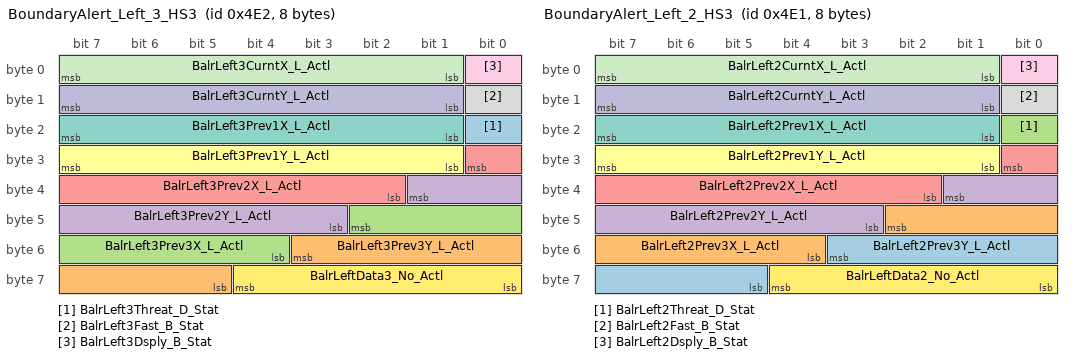
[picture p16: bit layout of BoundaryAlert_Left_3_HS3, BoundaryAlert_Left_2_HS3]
BO_ 1250 BoundaryAlert_Left_3_HS3: 8 GWM
 SG_ BalrLeft3Threat_D_Stat : 16|1@0+ (1,0) [0|1] "SED"  IPC
 SG_ BalrLeft3Prev3Y_L_Actl : 51|7@0+ (0.5,-32) [-32|31.5] "meter"  IPC
 SG_ BalrLeft3Prev3X_L_Actl : 42|7@0+ (0.5,-32) [-32|31.5] "meter"  IPC
 SG_ BalrLeft3Prev2Y_L_Actl : 33|7@0+ (0.5,-32) [-32|31.5] "meter"  IPC
 SG_ BalrLeft3Prev2X_L_Actl : 24|7@0+ (0.5,-32) [-32|31.5] "meter"  IPC
 SG_ BalrLeft3Prev1Y_L_Actl : 31|7@0+ (0.5,-32) [-32|31.5] "meter"  IPC
 SG_ BalrLeft3Prev1X_L_Actl : 23|7@0+ (0.5,-32) [-32|31.5] "meter"  IPC
 SG_ BalrLeft3Fast_B_Stat : 8|1@0+ (1,0) [0|1] "SED"  IPC
 SG_ BalrLeft3Dsply_B_Stat : 0|1@0+ (1,0) [0|1] "SED"  IPC
 SG_ BalrLeft3CurntY_L_Actl : 15|7@0+ (0.5,-32) [-32|31.5] "meter"  IPC
 SG_ BalrLeft3CurntX_L_Actl : 7|7@0+ (0.5,-32) [-32|31.5] "meter"  IPC
 SG_ BalrLeftData3_No_Actl : 60|5@0+ (1,0) [0|31] "unitless"  IPC

BO_ 1249 BoundaryAlert_Left_2_HS3: 8 GWM
 SG_ BalrLeft2Prev3Y_L_Actl : 51|7@0+ (0.5,-32) [-32|31.5] "meter"  IPC
 SG_ BalrLeft2Prev3X_L_Actl : 42|7@0+ (0.5,-32) [-32|31.5] "meter"  IPC
 SG_ BalrLeft2Threat_D_Stat : 16|1@0+ (1,0) [0|1] "SED"  IPC
 SG_ BalrLeft2Prev2Y_L_Actl : 33|7@0+ (0.5,-32) [-32|31.5] "meter"  IPC
 SG_ BalrLeft2Prev2X_L_Actl : 24|7@0+ (0.5,-32) [-32|31.5] "meter"  IPC
 SG_ BalrLeft2Prev1Y_L_Actl : 31|7@0+ (0.5,-32) [-32|31.5] "meter"  IPC
 SG_ BalrLeft2Prev1X_L_Actl : 23|7@0+ (0.5,-32) [-32|31.5] "meter"  IPC
 SG_ BalrLeft2Fast_B_Stat : 8|1@0+ (1,0) [0|1] "SED"  IPC
 SG_ BalrLeft2Dsply_B_Stat : 0|1@0+ (1,0) [0|1] "SED"  IPC
 SG_ BalrLeft2CurntY_L_Actl : 15|7@0+ (0.5,-32) [-32|31.5] "meter"  IPC
 SG_ BalrLeft2CurntX_L_Actl : 7|7@0+ (0.5,-32) [-32|31.5] "meter"  IPC
 SG_ BalrLeftData2_No_Actl : 60|5@0+ (1,0) [0|31] "unitless"  IPC

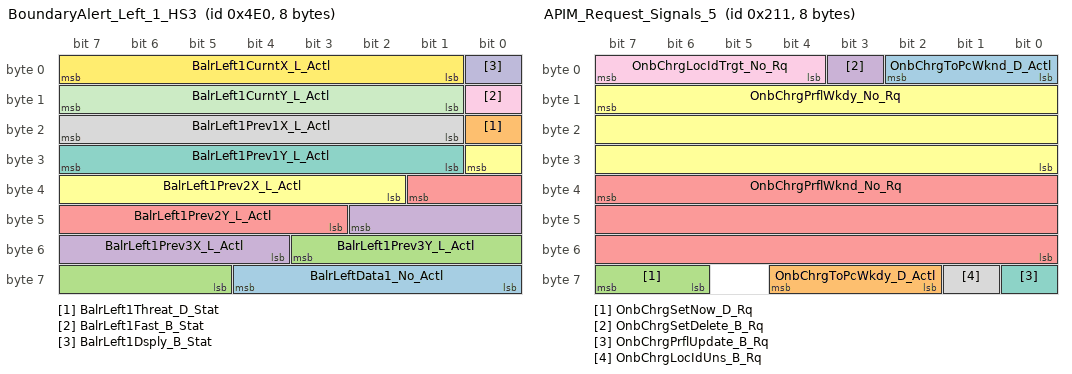
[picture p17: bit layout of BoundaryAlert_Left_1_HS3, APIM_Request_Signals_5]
BO_ 1248 BoundaryAlert_Left_1_HS3: 8 GWM
 SG_ BalrLeftData1_No_Actl : 60|5@0+ (1,0) [0|31] "unitless"  IPC
 SG_ BalrLeft1Threat_D_Stat : 16|1@0+ (1,0) [0|1] "SED"  IPC
 SG_ BalrLeft1Prev3Y_L_Actl : 51|7@0+ (0.5,-32) [-32|31.5] "meter"  IPC
 SG_ BalrLeft1Prev3X_L_Actl : 42|7@0+ (0.5,-32) [-32|31.5] "meter"  IPC
 SG_ BalrLeft1Prev2Y_L_Actl : 33|7@0+ (0.5,-32) [-32|31.5] "meter"  IPC
 SG_ BalrLeft1Prev2X_L_Actl : 24|7@0+ (0.5,-32) [-32|31.5] "meter"  IPC
 SG_ BalrLeft1Prev1Y_L_Actl : 31|7@0+ (0.5,-32) [-32|31.5] "meter"  IPC
 SG_ BalrLeft1Prev1X_L_Actl : 23|7@0+ (0.5,-32) [-32|31.5] "meter"  IPC
 SG_ BalrLeft1Fast_B_Stat : 8|1@0+ (1,0) [0|1] "SED"  IPC
 SG_ BalrLeft1Dsply_B_Stat : 0|1@0+ (1,0) [0|1] "SED"  IPC
 SG_ BalrLeft1CurntY_L_Actl : 15|7@0+ (0.5,-32) [-32|31.5] "meter"  IPC
 SG_ BalrLeft1CurntX_L_Actl : 7|7@0+ (0.5,-32) [-32|31.5] "meter"  IPC

BO_ 1256 GWM_Send_Signals_15_HS3: 8 GWM
 SG_ BalrMdeRight_D_Stat_UB : 21|1@0+ (1,0) [0|1] "SED"  IPC
 SG_ BalrMdeSelRight_B_Stat_UB : 17|1@0+ (1,0) [0|1] "SED"  IPC
 SG_ BalrRight_D_Stat_UB : 16|1@0+ (1,0) [0|1] "SED"  IPC
 SG_ BalrLckRight_B_Stat_UB : 14|1@0+ (1,0) [0|1] "SED"  IPC
 SG_ BalrChimeRight_D_Rq_UB : 2|1@0+ (1,0) [0|1] "SED"  IPC
 SG_ BalrSnsRight_D_Falt_UB : 24|1@0+ (1,0) [0|1] "SED"  IPC
 SG_ BalrWndwRight_B_Stat_UB : 36|1@0+ (1,0) [0|1] "SED"  IPC
 SG_ BalrLckRight_B_Stat : 15|1@0+ (1,0) [0|1] "SED"  IPC
 SG_ BalrWndwRight_B_Stat : 37|1@0+ (1,0) [0|1] "SED"  IPC
 SG_ BalrMdeSelRight_B_Stat : 18|1@0+ (1,0) [0|1] "SED"  IPC
 SG_ BalrSnsRight_D_Falt : 26|2@0+ (1,0) [0|3] "SED"  IPC
 SG_ BalrChimeRight_D_Rq : 4|2@0+ (1,0) [0|3] "SED"  IPC
 SG_ BalrMdeRight_D_Stat : 23|2@0+ (1,0) [0|3] "SED"  IPC
 SG_ BalrRight_D_Stat : 31|2@0+ (1,0) [0|3] "SED"  IPC
 SG_ BalrWndwLeft_B_Stat_UB : 38|1@0+ (1,0) [0|1] "SED"  IPC
 SG_ BalrSnsLeft_D_Falt_UB : 27|1@0+ (1,0) [0|1] "SED"  IPC
 SG_ BalrMdeSelLeft_B_Stat_UB : 19|1@0+ (1,0) [0|1] "SED"  IPC
 SG_ BalrMdeLeft_D_Stat_UB : 8|1@0+ (1,0) [0|1] "SED"  IPC
 SG_ BalrLeft_D_Stat_UB : 11|1@0+ (1,0) [0|1] "SED"  IPC
 SG_ BalrLckLeft_B_Stat_UB : 0|1@0+ (1,0) [0|1] "SED"  IPC
 SG_ BalrChimeLeft_D_Rq_UB : 5|1@0+ (1,0) [0|1] "SED"  IPC
 SG_ BalrLeft_D_Stat : 13|2@0+ (1,0) [0|3] "SED"  IPC
 SG_ BalrMdeSelLeft_B_Stat : 20|1@0+ (1,0) [0|1] "SED"  IPC
 SG_ BalrLckLeft_B_Stat : 1|1@0+ (1,0) [0|1] "SED"  IPC
 SG_ BalrWndwLeft_B_Stat : 39|1@0+ (1,0) [0|1] "SED"  IPC
 SG_ BalrMdeLeft_D_Stat : 10|2@0+ (1,0) [0|3] "SED"  IPC
 SG_ BalrSnsLeft_D_Falt : 29|2@0+ (1,0) [0|3] "SED"  IPC
 SG_ BalrChimeLeft_D_Rq : 7|2@0+ (1,0) [0|3] "SED"  IPC
 SG_ WakeAlarm2_D_Stat_UB : 33|1@0+ (1,0) [0|1] "SED"  IPC
 SG_ WakeAlarm2_D_Stat : 35|2@0+ (1,0) [0|3] "SED"  IPC

BO_ 529 APIM_Request_Signals_5: 8 APIM
 SG_ OnbChrgToPcWknd_D_Actl : 2|3@0+ (1,0) [0|7] "percent"  GWM
 SG_ OnbChrgToPcWkdy_D_Actl : 60|3@0+ (1,0) [0|7] "percent"  GWM
 SG_ OnbChrgSetNow_D_Rq : 63|2@0+ (1,0) [0|3] "SED"  GWM
 SG_ OnbChrgSetDelete_B_Rq : 3|1@0+ (1,0) [0|1] "SED"  GWM
 SG_ OnbChrgPrflWknd_No_Rq : 39|24@0+ (1,0) [0|16777215] "unitless"  GWM
 SG_ OnbChrgPrflWkdy_No_Rq : 15|24@0+ (1,0) [0|16777215] "unitless"  GWM
 SG_ OnbChrgPrflUpdate_B_Rq : 56|1@0+ (1,0) [0|1] "SED"  GWM
 SG_ OnbChrgLocIdUns_B_Rq : 57|1@0+ (1,0) [0|1] "SED"  GWM
 SG_ OnbChrgLocIdTrgt_No_Rq : 7|4@0+ (1,0) [0|15] "Unitless"  GWM

BO_ 642 GWM_Send_Signals_14_HS3: 8 GWM
 SG_ SldrrMsgTxt_D2_Rq_UB : 8|1@0+ (1,0) [0|1] "SED"  IPC
 SG_ SldrrMsgTxt_D2_Rq : 11|3@0+ (1,0) [0|7] "SED"  IPC
 SG_ SldrrChime_D_Rq_UB : 12|1@0+ (1,0) [0|1] "SED"  IPC
 SG_ SldrrChime_D_Rq : 15|3@0+ (1,0) [0|7] "SED"  IPC
 SG_ SldrlMsgTxt_D2_Rq_UB : 0|1@0+ (1,0) [0|1] "SED"  IPC
 SG_ SldrlMsgTxt_D2_Rq : 3|3@0+ (1,0) [0|7] "SED"  IPC
 SG_ SldrlChime_D_Rq_UB : 4|1@0+ (1,0) [0|1] "SED"  IPC
 SG_ SldrlChime_D_Rq : 7|3@0+ (1,0) [0|7] "SED"  IPC
 SG_ PaakMyKeySearch_D_Stat_UB : 27|1@0+ (1,0) [0|1] "SED"  APIM
 SG_ UreaLvlQlty_D_RqDsply_UB : 48|1@0+ (1,0) [0|1] "SED"  IPC
 SG_ DieslPrtcWarn_D_Rq_UB : 24|1@0+ (1,0) [0|1] "SED"  IPC
 SG_ UreaQltySysWarn_D_Rq_UB : 25|1@0+ (1,0) [0|1] "SED"  IPC
 SG_ UreaLvlTxtWarn_D_Rq_UB : 26|1@0+ (1,0) [0|1] "SED"  IPC
 SG_ UreaLvlQlty_D_RqDsply : 59|3@0+ (1,0) [0|7] "SED"  IPC
 SG_ UreaLvlTxtWarn_D_Rq : 63|4@0+ (1,0) [0|15] "SED"  IPC
 SG_ UreaQltySysWarn_D_Rq : 51|3@0+ (1,0) [0|7] "SED"  IPC
 SG_ DieslPrtcWarn_D_Rq : 55|4@0+ (1,0) [0|15] "SED"  IPC
 SG_ KeyMyKeyTot_No2_Cnt_UB : 40|1@0+ (1,0) [0|1] "SED"  APIM
 SG_ KeyAdmnTot_No2_Cnt_UB : 32|1@0+ (1,0) [0|1] "SED"  APIM
 SG_ KeyMyKeyTot_No2_Cnt : 47|7@0+ (1,0) [0|127] "unitless"  APIM
 SG_ KeyAdmnTot_No2_Cnt : 39|7@0+ (1,0) [0|127] "unitless"  APIM
 SG_ DcChrgSrvcRqd_B_Rq_UB : 31|1@0+ (1,0) [0|1] "SED"  IPC
 SG_ DcChrgSrvcRqd_B_Rq : 16|1@0+ (1,0) [0|1] "SED"  IPC
 SG_ PaakMyKeySearch_D_Stat : 30|3@0+ (1,0) [0|7] "SED"  APIM
 SG_ GrdAsstActv_B_Stat_UB : 17|1@0+ (1,0) [0|1] "SED"  IPC
 SG_ GrdAsstActv_B_Stat : 18|1@0+ (1,0) [0|1] "SED"  IPC
 SG_ TrlrAidTrlrId_No_Rq_UB : 19|1@0+ (1,0) [0|1] "SED"  IPC,APIM
 SG_ TrlrAidTrlrId_No_Rq : 23|4@0+ (1,0) [0|15] "unitless"  IPC,APIM

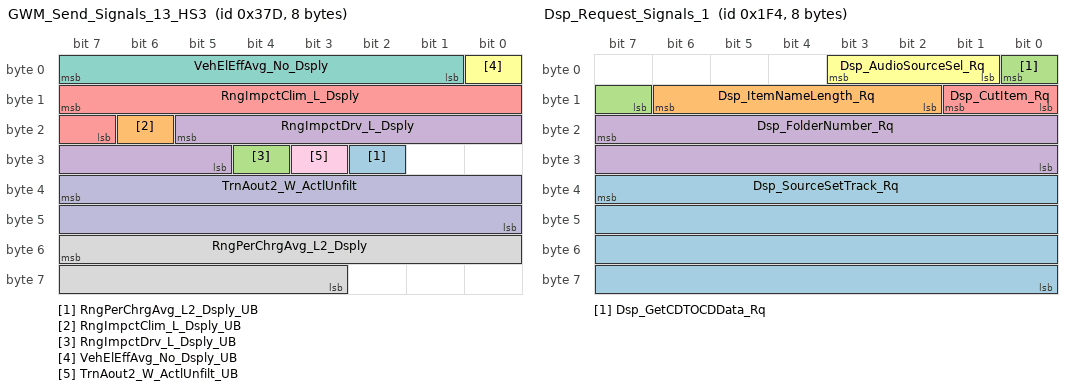
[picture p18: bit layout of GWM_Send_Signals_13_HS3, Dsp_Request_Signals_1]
BO_ 893 GWM_Send_Signals_13_HS3: 8 GWM
 SG_ RngPerChrgAvg_L2_Dsply_UB : 26|1@0+ (1,0) [0|1] "SED"  IPC,APIM
 SG_ RngImpctClim_L_Dsply_UB : 22|1@0+ (1,0) [0|1] "SED"  IPC
 SG_ RngImpctDrv_L_Dsply_UB : 28|1@0+ (1,0) [0|1] "SED"  IPC
 SG_ RngImpctDrv_L_Dsply : 21|9@0+ (1,-255) [-255|256] "km"  IPC
 SG_ RngImpctClim_L_Dsply : 15|9@0+ (1,-255) [-255|256] "km"  IPC
 SG_ VehElEffAvg_No_Dsply_UB : 0|1@0+ (1,0) [0|1] "SED"  IPC,APIM
 SG_ VehElEffAvg_No_Dsply : 7|7@0+ (10,-100) [-100|1150] "wattHr/km"  IPC,APIM
 SG_ RngPerChrgAvg_L2_Dsply : 55|13@0+ (0.1,0) [0|818.9] "km"  IPC,APIM
 SG_ TrnAout2_W_ActlUnfilt_UB : 27|1@0+ (1,0) [0|1] "SED"  ACM
 SG_ TrnAout2_W_ActlUnfilt : 39|16@0+ (0.1,-3276.5) [-3276.5|3276.8] "rad/s"  ACM

BO_ 500 Dsp_Request_Signals_1: 8 APIM
 SG_ Dsp_SourceSetTrack_Rq : 39|32@0+ (1,0) [0|4294967295] "unitless"  ACM
 SG_ Dsp_ItemNameLength_Rq : 14|5@0+ (1,0) [0|20] "SED"  ACM
 SG_ Dsp_GetCDTOCDData_Rq : 0|2@0+ (1,0) [0|3] "SED"  ACM
 SG_ Dsp_FolderNumber_Rq : 23|16@0+ (1,0) [0|65535] "unitless"  ACM
 SG_ Dsp_CutItem_Rq : 9|2@0+ (1,0) [0|3] "SED"  ACM
 SG_ Dsp_AudioSourceSel_Rq : 3|3@0+ (1,0) [0|7] "SED"  ACM

BO_ 503 Dsp_Request_Signals_4: 8 APIM
 SG_ Dsp_PlayFrstTrInFldr_Rq : 39|16@0+ (1,0) [0|65535] "unitless"  ACM
 SG_ Dsp_ItemIndex_Rq : 23|16@0+ (1,0) [0|65535] "unitless"  ACM
 SG_ Dsp_FolderNumber3_Rq : 7|16@0+ (1,0) [0|65535] "unitless"  ACM
 SG_ Dsp_AudioSourceSel3_Rq : 55|3@0+ (1,0) [0|7] "SED"  ACM

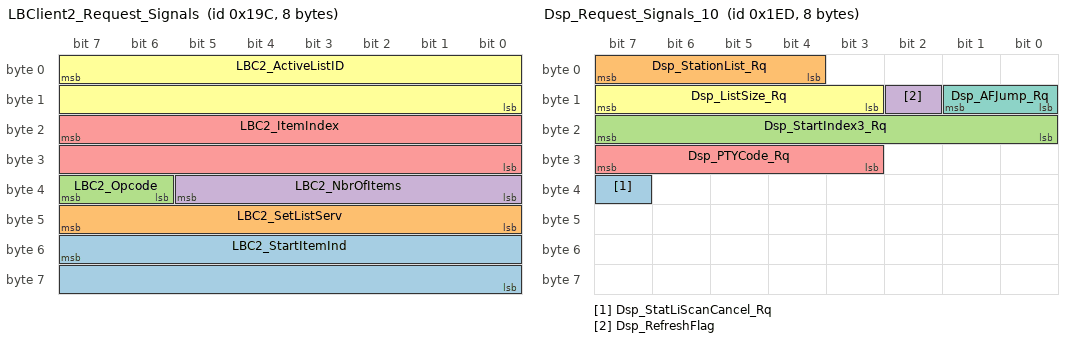
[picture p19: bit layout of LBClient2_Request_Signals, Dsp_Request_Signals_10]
BO_ 412 LBClient2_Request_Signals: 8 APIM
 SG_ LBC2_StartItemInd : 55|16@0+ (1,0) [0|65535] "unitless"  ACM
 SG_ LBC2_SetListServ : 47|8@0+ (1,0) [0|255] "unitless"  ACM
 SG_ LBC2_Opcode : 39|2@0+ (1,0) [0|3] "SED"  ACM
 SG_ LBC2_NbrOfItems : 37|6@0+ (1,0) [0|63] "unitless"  ACM
 SG_ LBC2_ItemIndex : 23|16@0+ (1,0) [0|65535] "unitless"  ACM
 SG_ LBC2_ActiveListID : 7|16@0+ (1,0) [0|65535] "unitless"  ACM

BO_ 493 Dsp_Request_Signals_10: 8 APIM
 SG_ Dsp_StatLiScanCancel_Rq : 39|1@0+ (1,0) [0|1] "SED"  ACM
 SG_ Dsp_StationList_Rq : 7|4@0+ (1,0) [0|15] "SED"  ACM
 SG_ Dsp_StartIndex3_Rq : 23|8@0+ (1,0) [0|255] "unitless"  ACM
 SG_ Dsp_RefreshFlag : 10|1@0+ (1,0) [0|1] "SED"  ACM
 SG_ Dsp_PTYCode_Rq : 31|5@0+ (1,0) [0|31] "SED"  ACM
 SG_ Dsp_ListSize_Rq : 15|5@0+ (1,0) [0|31] "SED"  ACM
 SG_ Dsp_AFJump_Rq : 9|2@0+ (1,0) [0|3] "SED"  ACM

BO_TX_BU_ 598 : APIM_CISM,APIM;
BO_TX_BU_ 595 : APIM_CISM,APIM;
BO_TX_BU_ 479 : APIM_CISM,APIM;
BO_TX_BU_ 474 : APIM_CISM,APIM;
BO_TX_BU_ 477 : APIM_CISM,APIM;
BO_TX_BU_ 260 : APIM_CISM,APIM;
CM_ SG_ 508 Mc_DB1GetInfStartInd_Rq "Object Media Player iPod.GetMDBInfo.MDBStartItemInd
";
CM_ SG_ 508 Mc_DB1GtInfNbrOfItms_Rq "Object Media Player iPod.GetMDBInfo.MDBNbrOfItems
";
CM_ SG_ 508 Mc_DB1GetInfSetConf_Rq "Object Media Player iPod.GetMDBInfo.MDBSetFilterConf
";
CM_ SG_ 508 Mc_DB1GetInfSetFilt3_Rq "Object Media Player iPod.GetMDBInfo.MDBSetFilter3
";
CM_ SG_ 508 Mc_DB1GetInfSetFilt2_Rq "Object Media Player iPod.GetMDBInfo.MDBSetFilter2
";
CM_ SG_ 508 Mc_DB1GetInfSetFilt1_Rq "Object Media Player iPod.GetMDBInfo.MDBSetFilter1 ";
CM_ SG_ 507 Mc_DB1SetTrkItmIndex_Rq "Object Media Player iPod.MDBSetTrack.MDBItemIndex
";
CM_ SG_ 507 Mc_DB1SetTrkSetConf_Rq "Object Media Player iPod.MDBSetTrack.MDBSetFilterConf";
CM_ SG_ 507 Mc_DB1SetTrkSetFilt3_Rq "Object Media Player iPod.MDBSetTrack.MDBSetFilter3";
CM_ SG_ 507 Mc_DB1SetTrkSetFilt2_Rq "Object Media Player iPod.MDBSetTrack.MDBSetFilter2";
CM_ SG_ 507 Mc_DB1SetTrkSetFilt1_Rq "Object Media Player iPod.MDBSetTrack.MDBSetFilter1";
CM_ SG_ 506 Mc_AudioSourceSel3_Rq "Object Media Player BTAudio.GetDetailedMPInfo.AudioSource
Object Media Player BTAudio.PlayFirstTrackInFolder.AudioSource
Object Media Player USB.GetDetailedMPInfo.AudioSource
Object Media Player USB.PlayFirstTrackInFolder.AudioSource";
CM_ SG_ 506 Mc_PlayFrstTrInFldr_Rq "Object Media Player BTAudio.PlayFirstTrackInFolder.FolderNumber
Object Media Player USB.PlayFirstTrackinFolder.FolderNumber

$FFFF: Inactive";
CM_ SG_ 506 Mc_ItemIndex_Rq "Object Media Player BTAudio.GetDetailedMPInfo.ItemIndex
Object Media Player USB.GetDetailedMPInfo.ItemIndex";
CM_ SG_ 506 Mc_FolderNumber3_Rq "Object Media Player BTAudio.GetDetailedMPInfo.FolderNumber
Object Media Player USB.GetDetailedMPInfo.FolderNumber";
CM_ SG_ 505 Mc_AudioSourceSel2_Rq "Object Media Player BTAudio.GetMPInfo.AudioSouce
Object Media Player USB.GetMPInfo.AudioSouce
Object Media Player SDCard.GetMPInfo.AudioSouce";
CM_ SG_ 505 Mc_StartItemIndexRq "Object Media Player BTAudio.GetMPInfo.StartingItemIndex
Object Media Player USB.GetMPInfo.StartingItemIndex
Object Media Player SDCard.GetMPInfo.StartingItemIndex

$FFFF: Inactive";
CM_ SG_ 505 Mc_NbrOfItems2_Rq "Object Media Player BTAudio.GetMPInfo.NbrOfItems
Object Media Player USB.GetMPInfo.NbrOfItems
Object Media Player SDCard.GetMPInfo.NbrOfItems";
CM_ SG_ 505 Mc_ItemNameLength2_Rq "Object Media Player BTAudio.GetMPInfo.ItemNameLength
Object Media Player USB.GetMPInfo.ItemNameLength
Object Media Player SDCard.GetMPInfo.ItemNameLength";
CM_ SG_ 505 Mc_CutItem2_Rq "Object Media Player BTAudio.GetMPInfo.CutItemName
Object Media Player USB.GetMPInfo.CutItemName
Object Media Player SDCard.GetMPInfo.CutItemName";
CM_ SG_ 505 Mc_FolderNumber2_Rq "Object Media Player BTAudio.GetMPInfo.FolderNumber 
Object Media Player USB.GetMPInfo.FolderNumber
Object Media Player SDCard.GetMPInfo.FolderNumber

$FFFF: Inactive";
CM_ SG_ 505 Mc_FolderContent_Rq "Object Media Player USB.GetMPInfo.FolderContent
Object Media Player SDCard.GetMPInfo.FolderContent

Note: Value table entries were truncated from:
$0: RequestContentFromParameterFolderNumber
$1: RequestContentFromParentFolderOfParameterFolderNumber";
CM_ SG_ 504 Mc_AudioSourceSel_Rq "Object Single CD.GetFolderName.AudioSource
Object Media Player
BTAudio.GetFolderName.AudioSource
BTAudio.SetTrack.AudioSource
USB.GetFolderName.AudioSource
USB.SetTrack.AudioSource
SDCard.GetFolderName.AudioSource
SDCard.SetTrack.AudioSource";
CM_ SG_ 504 Mc_FolderNumber_Rq "Object Media Player BTAudio.GetFolderName.FolderName
Object Media Player USB.GetFolderName.FolderName
Object Single CD.GetFolderName.FolderNumber
Object Media Player SDCard.FolderNumber

$FFFF: Inactive";
CM_ SG_ 504 Mc_CutItem_Rq "Object Media Player BTAudio.GetFolderName.CutItemName
Object Media Player USB.GetFolderName.CutItemName
Object Single CD.GetFolderName.CutItem
Object Media Player SDCard.CutItem";
CM_ SG_ 504 Mc_ItemNameLength_Rq "Object Media Player BTAudio.GetFolderName.ItemNameLength
Object Media Player USB.GetFolderName.ItemNameLength
Object Media Player SDCard.GetFolderName.ItemNameLength
Object Single CD.GetFolderName.ItemNameLength";
CM_ SG_ 504 Mc_SourceSetTrack_Rq "Object Media Player BTAudio.SetTrack
Object Media Player USB.SetTrack
Object Media Player SDCard.SetTrack

$0000: Inactive";
CM_ SG_ 712 NAV_MC_WORD_Rx "MM ISO 15765-2 Message Catalogue
Section MC - NAV
Section NavRepClient - NavRepServer";
CM_ SG_ 711 MyKeySrvr_Clnt_Word_Tx "TP-LOG-GTPC-201379-SID-7C";
CM_ SG_ 703 CONMP_MC_WORD_Rx "MM ISO 15765-2 Message Catalogue
Section CONMP - MC
Section MediaPlayerServer - MediaPlayerClient";
CM_ SG_ 702 PHONE_MC_WORD_Rx "MM ISO 15765-2 Message Catalogue
Section MC - PHONE";
CM_ SG_ 676 MC_RDISP_WORD_Tx "Communicates ConsHistGraph_St, which includes data to populate the consumption history display.";
CM_ SG_ 647 HEC_BTIncomingCall_Rq "Object Bluetooth Phone.BTIncomingCall";
CM_ SG_ 647 HEC_BTEndTelService_Rq "Object Bluetooth Phone.BTEndTelService";
CM_ SG_ 400 Mc_SetCurrStatMCCh_Rq "Object Tuner.SetCurrentStation.MCChannel";
CM_ SG_ 400 Mc_SetCurrntStatFreq_Rq "Object Tuner.SetCurrentStat.Request.Frequency

AM: Freq = 153+ Offset kHz.
Offset 0..1557

FM: Freq = 76+ Offset*0.05 MHz. Offset 0..640
Selected tuned band determine frequency (kHz or MHz).";
CM_ SG_ 400 Mc_SetCurrentStatOp_Rq "Object Tuner.SetCurrentStat.Request.Operation";
CM_ SG_ 400 Mc_PerTUStartIndex2_Rq "Object Personalization. DAB.GetTUPresetInfo.StartIndex2

$1-$FF: Preset 1 to 255";
CM_ SG_ 400 Mc_PerTUPresetArea_Rq "Object Personalization.DAB.GetTUPresetInfo.PresetArea

$5: Get AMAST (MW) Preset Data
$6: Get AM (LW) Preset Data";
CM_ SG_ 400 Mc_PerTUNbrOfPresets_Rq "Object Personalization. DAB.GetTUPresetInfo.NumberOfPresets

$1-$1E: Preset 1 to 30";
CM_ SG_ 598 CONMP_RSE_WORD_Tx "MM ISO 15765-2 Message Catalogue MediaPlayerServer – MediaPlayerClient3";
CM_ SG_ 867 LHS_Temp_Disp_Digit3 "Added for MY 08";
CM_ SG_ 867 LHS_Temp_Disp_Digit2 "Added for MY 08";
CM_ SG_ 867 LHS_Temp_Disp_Digit1 "Added for MY 08";
CM_ SG_ 867 EATC_LHS_Unit "Added for MY 08";
CM_ BO_ 828 "Set GenSigSendType = NoSigSendType (Cyclic) for the following signals, D.Card 3/31/08
Driver_Lock_Sw_Stat
";
CM_ SG_ 772 Memory_Feedback_Rqst "Updated to 1 bit for CGEA, Not backwards compatible";
CM_ SG_ 773 MemSwtchPsngrFdbck_B_Rq "Updated to 1 bit for CGEA, Not backwards compatible";
CM_ SG_ 746 Con_BTAud_Shuffle_St "Object MediaPlayer BTAudio.Shuffle";
CM_ SG_ 746 Con_BTAud_Repeat_St "Object Media Player BTAudio.Repeat";
CM_ SG_ 746 Con_BTAud_IntroScan_St "Object Media Player BTAudio.IntroScan";
CM_ SG_ 746 Con_BTAud_ActTrNum1_St "Object Media Player BTAudio.ActiveTrackNum1
";
CM_ SG_ 746 Con_ShowBTPINNumb_St "Object BT Device.ShowBTPINNumb

PIN value range (dec): 0000 - 9999

Inactive: $3FFD
Invalid: $3FFE";
CM_ SG_ 746 Con_BTAud_Error_St "Object Media Player BTAudio.BTAudioError";
CM_ SG_ 746 Con_BTAud_FunctStats_St "Object Media Player BTAudio.FunctionStatus";
CM_ SG_ 746 Con_BTAud_OpMode_St "Object Media Player BTAudio.OperationMode";
CM_ SG_ 479 DISP_SetVol_Source_Rq "Object.VolumeControl.MFD_SetVol_Source.Rq

SetVol_Source.Rq";
CM_ SG_ 479 DISP_SetVol_Level_Rq "Object.VolumeControl.MFD_SetVol_Level.Rq 

0x0 Inactive/NoChange
0x1 No Volume
0x2 Vol_Step1
0x3 Vol_Step2
0x4 Vol_Step3
Cont.
0x1F Vol_Step30

Object.VolumeControl.SetPointVolume

Object.VolumeControl.SetVol_Level.Rq";
CM_ SG_ 479 DISP_Setshaker_Rq "Object.AudioSettings.SetShaker.Rq
";
CM_ SG_ 474 Nav_SetCurrStatMCCh_Rq "Object Audio.SetDSPProgram
";
CM_ SG_ 474 NAV_SetNEWSMode_Rq "Object Tuner.SetNEWSMode";
CM_ SG_ 474 NAV_SetMid_Rq "Object Audio Settings.SetMid

Level -7..0..7
$F: Inactive

Method: SetMidRange.Rq";
CM_ SG_ 474 NAV_SetDSP_Rq "Object Audio.SetDSP

Object.AudioSettings.SetOccupancy_Mode.Rq";
CM_ SG_ 474 NAV_SetCurrStatFreq_Rq "Object Tuner.SetCurrentStat.Request.Frequency

AM: Freq = 153+ Offset kHz.
Offset 0..1557

FM: Freq = 76+ Offset*0.05 MHz. Offset 0..640
Selected tuned band determine frequency (kHz or MHz).";
CM_ SG_ 474 NAV_SetCurrentStatOp_Rq "Object Tuner.SetCurrentStat.Request.Operation";
CM_ SG_ 474 NAV_SetCurrentPICode_Rq "Object Tuner.SetCurrentStat.Request.PI Code

16 bit hex coded PI Code

";
CM_ SG_ 474 NAV_ARReqstrSystem_Rq "Object Audio Management AudioClient.AudioRequest.Requester System

AudioRequest.Rq : RequesterSystem";
CM_ SG_ 474 NAV_ARReqstrPriority_Rq "Object Audio Management AudioClient.AudioRequest.Requester Priority

AudioRequest.Rq : RequesterPriority";
CM_ SG_ 474 NAV_AROperationType_Rq "Object Audio Management Audio Client.AudioRequest.Operation Type

AudioRequest.Rq : OperationType";
CM_ SG_ 474 NAV_ARAudioSource_Rq "Object Audio Management Audio Client.AudioRequest.Requested Audio Source

$8 interpreted as APIM or Navigation

AudioRequest.Rq : RequestedAudioSource";
CM_ SG_ 477 NAV_SetTreble_Rq "Object Audio.SetTreble.Rq



Level -7..0..7
$F: Inactive";
CM_ SG_ 477 NAV_SetFader_Rq "Object Audio.SetFader

.Rq

Level -7..0..7

$F: Inactive";
CM_ SG_ 477 NAV_SetBass_Rq "Object Audio.SetBass.Rq



Level -7..0..7
$F: Inactive";
CM_ SG_ 477 NAV_SetBalance_Rq "Object Audio.SetBalance.Rq



Level -7..0..7
$F: Inactive";
CM_ SG_ 477 NAV_SetAVC_Rq "Object Audio.SetAVC
Object. Audio.SetSpeed_Comp_Vol.Rq

$F: Inactive";
CM_ SG_ 477 NAV_SecurtyPINUnlock_Rq "Object ACU System Master.SecurityPINUnlock
PIN: from 0000 - 9999
$3FFF: Inactive";
CM_ SG_ 477 NAV_LoadEjectMode_Rq "Object Single CD.LoadEject.Mode";
CM_ SG_ 477 NAV_LoadEjectDisc_Rq "Object Indash CD Changer.LoadEject(Disc Number)
Object Single CD.LoadEject(Action)
";
CM_ SG_ 260 SDARS_GetESN_Rq "Object Tuner.SDARS Tuner.GetESN";
CM_ SG_ 260 SDARS_SRReplay_Rq "Object Tuner.SDARS Tuner.SR-ReplayStatus";
CM_ SG_ 260 SDARS_SelectCategory_Rq "Object Tuner.SDARS Tuner.SetCategory
0x00: All
0x01: Category1
0x02: Category2
....
0xF9: Category249
0xFA: Reserved
....
0xFE: Reserved
0xFF: Invalid
";
CM_ SG_ 260 SDARS_InfoRefChanNum_Rq "Object Tuner.SDARS Tuner.InfoRefresh.Rq
$0: Channel_0
$1: Channel_1
$2: Channel_2
$FE: Channel_254
$FF: Inactive";
CM_ SG_ 260 SDARS_FactoryReset_Rq "Object Tuner.SDARS Tuner.FactoryReset

Object VehicleSettings.FactoryReset.Rq

Object StationManagement.FactoryReset.Rq

Enhanced Memory: FactoryReset_Rq";
CM_ SG_ 476 NAV_SkipCatalouge_Rq "Object Single CD.SkipFolder";
CM_ SG_ 476 NAV_SetOperationMode_Rq "Object Rear CD Changer.SetOperationMode
Object Indash CD Changer.SetOperationMode
Object Single CD.SetOperationMode";
CM_ SG_ 476 NAV_SetDSPProgram_Rq "Object Audio.SetDSPProgram
";
CM_ SG_ 502 Dsp_StartItemIndexRq "Object Media Player BT SDCard.GetMPInfo.StartItemIndex
USB.GetMPInfo.StartItemIndex
SingleCD.GetMPInfo.StartItemIndex

$FFFF: Inactive";
CM_ SG_ 502 Dsp_NbrOfItems2_Rq "Object Media Player 
BT Audio.GetMPInfo.NbrOfItems
SDCard.GetMPInfo.NbrOfItems
USB.GetMPInfo.NbrOfItems
SingleCD.GetMPInfo.NbrOfItems";
CM_ SG_ 502 Dsp_ItemNameLength2_Rq "Object Media Player 
BT Audio.GetMPInfo.ItemNameLength
SDCard.GetMPInfo.ItemNameLength
USB.GetMPInfo.ItemNameLength
SingleCD.GetMPInfo.ItemNameLength";
CM_ SG_ 502 Dsp_FolderNumber2_Rq "Object Media Player 
BT Audio.GetMPInfo.FolderNumber
USB.GetMPInfo.FolderNumber
SDCard.GetMPInfo.FolderNumber
SingleCD.GetMPInfo.FolderNumber

$FFFF: Inactive";
CM_ SG_ 502 Dsp_FolderContent_Rq "Object Media Player 
BT Audio.GetMPInfo.FolderContent
SDCard.GetMPInfo.FolderContent
USB.GetMPInfo.FolderContent
SingleCD.GetMPinfo.Foldercontent

Note: Value table entries were truncated from:
$0: ..FolderNumber
$1: ..OfParameterFolderNumber";
CM_ SG_ 502 Dsp_CutItem2_Rq "Object Media Player 
BT Audio.GetMPInfo.CutItemName
SDCard.GetMPInfo.CutItemName
USB.GetMPInfo.CutItemName
SingleCD.GetMPInfo.CutItemName

Note: value table entry for value $2 was truncated from:
OneQuarterFromTheBeginningThreeQuarterFromTheEnd";
CM_ SG_ 502 Dsp_AudioSourceSel2_Rq "Object Media Player 
BT Audio.GetMPInfo.AudioSource
SDCard.GetMPInfo.AudioSource
USB.GetMPInfo.AudioSource
SingleCD.GetMPInfo.AudioSource";
CM_ SG_ 500 Dsp_SourceSetTrack_Rq "Object Media Player BTAudio.SetTrack
Object Media Player USB.SetTrack
Object Single CD.SetTrack.AudioSource
";
CM_ SG_ 500 Dsp_ItemNameLength_Rq "Object Media Player BTAudio.GetFolderName.ItemNameLength
Object Media Player USB.GetFolderName.ItemNameLength
Object Single CD.GetFolderName.ItemNameLength";
CM_ SG_ 500 Dsp_GetCDTOCDData_Rq "GetCDTOCData";
CM_ SG_ 500 Dsp_FolderNumber_Rq "Object Media Player BTAudio.GetFolderName.FolderNumber
Object Media Player USB.GetFolderName.FolderNumber
Object Single CD.GetFolderName.FolderNumber";
CM_ SG_ 500 Dsp_CutItem_Rq "Object Media Player BTAudio.GetFolderName.CutItemName
Object Media Player USB.GetFolderName.CutItemName
Object Single CD.GetFolderName.CutItemName

Note: value table entry for value $2 was truncated from:
OneQuarterFromTheBeginningThreeQuarterFromTheEnd";
CM_ SG_ 500 Dsp_AudioSourceSel_Rq "Object Media Player 
{ BTAudio.GetFolderName, 
SDCard.GetFolderName,
USB.GetFolderName,
BTAudio.SetTrack,
SD Card.SetTrack}.AudioSource
USB.SetTrack.AudioSource
Object Single CD.GetFolderName.AudioSource
Object Single CD.SetTrack.AudioSource";
CM_ SG_ 503 Dsp_PlayFrstTrInFldr_Rq "Object Single CD.PlayFirstTrackInFolder
Object Media Player BTAudio.PlayFirstTrackInFolder.FolderNumber
Object Media Player USB.PlayFirstTrackInFolder.FolderNumber

$FFFF: Inactive";
CM_ SG_ 503 Dsp_ItemIndex_Rq "Object Media Player BTAudio.GetDetailedMPInfo.ItemIndex
Object Media Player USB.GetDetailedMPInfo.ItemIndex

$FFFF: Inactive";
CM_ SG_ 503 Dsp_FolderNumber3_Rq "Object Media Player BTAudio.GetDetailedMPInfo.FolderNumber
Object Media Player USB.GetDetailedMPInfo.FolderNumber

$FFFF: Inactive";
CM_ SG_ 503 Dsp_AudioSourceSel3_Rq "Objects Media Player  {BTAudio, USB}.GetDetailedMPInfo.AudioSource

Objects Media Player {Single CD, BTAudio, USB}.PlayFirstTrackInFolder.AudioSource";
CM_ SG_ 412 LBC2_StartItemInd "Object. ListBrowser.ItemInf.Rq.StartItemInd
0x0000:Inactive
0x0001:1
0xFFFE:65634
0xFFFF:Reserved";
CM_ SG_ 412 LBC2_SetListServ "Object. ListBrowser.ItemInf.Rq.SetListServ
0x00:Inactive
0x01:ServerID_1
0xFF:ALL";
CM_ SG_ 412 LBC2_Opcode "Object. ListBrowser.ItemInf.Rq.Opcode";
CM_ SG_ 412 LBC2_NbrOfItems "Object. ListBrowser.ItemInf.Rq.NbrOfItems
0x00:Inactive
0x01:1Item
0x3F:63Items";
CM_ SG_ 412 LBC2_ItemIndex "Object. ListBrowser.ItemInf.Rq.ItemIndex
0x0000:BrowseActiveListID
0x0001:EntryIndex_1
0xFFFF:ParentOfActiveListID";
CM_ SG_ 412 LBC2_ActiveListID "Object. ListBrowser.ItemInf.Rq.ActiveListID
0x0000:Root
0xFFFF:Reserved";
CM_ SG_ 493 Dsp_StatLiScanCancel_Rq "Object Tuner.StationListScan";
CM_ SG_ 493 Dsp_StationList_Rq "Object Tuner.GetStationList(StationList)
(Parameter1)";
CM_ SG_ 493 Dsp_StartIndex3_Rq "Object TunerGetStationList(StartingIndex)
(Parameter3)";
CM_ SG_ 493 Dsp_RefreshFlag "Object Tuner.GetStationList(StationList)
(Parameter5)";
CM_ SG_ 493 Dsp_PTYCode_Rq "Object Tuner.GetStationList(PTYCode)
(Parramater4)

$0: Invalid
$1: PTY 1 (News)
..
$1F: PTY 31 (Alarm)";
CM_ SG_ 493 Dsp_ListSize_Rq "Object Tuner.GetStationList(ListSize)
(Parameter2)";
CM_ SG_ 493 Dsp_AFJump_Rq "Object Tuner.AFJump.Rq";
BA_DEF_ BO_  "FrameRouting" STRING ;
BA_DEF_ BO_  "FrameGatewayNetwork" STRING ;
BA_DEF_ BO_  "NetworkInitialization" ENUM  "No","Yes";
BA_DEF_ BO_  "FrameGatewayId" HEX 0 1407;
BA_DEF_ BO_  "EventRateOfChange" INT 10 10000;
BA_DEF_ BO_  "GenMsgStartDelayTime" INT 0 10000;
BA_DEF_ BO_  "GenMsgNrOfRepetition" INT 0 100;
BA_DEF_ BO_  "GenMsgDelayTime" INT 0 1000;
BA_DEF_ BO_  "GenMsgCycleTime" INT 0 100000;
BA_DEF_ BO_  "GenMsgSendType" ENUM  "FixedPeriodic","Event","EnabledPeriodic","NotUsed","NotUsed","EventPeriodic","NotUsed","NotUsed","NoMsgSendType";
BA_DEF_ SG_  "U_CD764_MY2022_Tx" ENUM  "No","Yes";
BA_DEF_ SG_  "U_U55X_MY2022_Tx" ENUM  "No","Yes";
BA_DEF_ SG_  "U_CD542_MY2021_Tx" ENUM  "No","Yes";
BA_DEF_ SG_  "ECGUsedTxSignal" ENUM  "No","Yes";
BA_DEF_ SG_  "U_T6_MCA_MY2020_Tx" ENUM  "No","Yes";
BA_DEF_ SG_  "U_P702_MY2021_Tx" ENUM  "No","Yes";
BA_DEF_ SG_  "U_CX727_MY2021_Tx" ENUM  "No","Yes";
BA_DEF_ SG_  "U_CD764_MY2022_Rx" ENUM  "No","Yes";
BA_DEF_ SG_  "U_FNV2_IVI_Rx" ENUM  "No","Yes";
BA_DEF_ SG_  "U_U55X_MY2022_Rx" ENUM  "No","Yes";
BA_DEF_ SG_  "U_CD542_MY2021_Rx" ENUM  "No","Yes";
BA_DEF_ SG_  "ECGUsedRxSignal" ENUM  "No","Yes";
BA_DEF_ SG_  "U_T6_MCA_MY2020_Rx" ENUM  "No","Yes";
BA_DEF_ SG_  "U_P702_MY2021_Rx" ENUM  "No","Yes";
BA_DEF_ SG_  "U_CX727_MY2021_Rx" ENUM  "No","Yes";
BA_DEF_ SG_  "GenSigStartValue" HEX 0 268435455;
BA_DEF_ SG_  "MetaData" ENUM  "No","Yes";
BA_DEF_ SG_  "ContentDependant" ENUM  "No","Yes";
BA_DEF_ SG_  "GenSigStartValueInteger" INT 0 1000000000;
BA_DEF_ SG_  "UsedOnPgmDBC" ENUM  "No","Yes";
BA_DEF_ SG_  "WakeupSignal" ENUM  "No","Yes";
BA_DEF_ SG_  "GenSigInactiveValue" INT 0 100000;
BA_DEF_ SG_  "GenSigSendType" ENUM  "Cyclic","OnWrite","vector_leerstring","OnChange","vector_leerstring","IfActive","vector_leerstring","NoSigSendType";
BA_DEF_ BO_  "OvtpPushApplication" ENUM  "FALSE","TRUE";
BA_DEF_ BO_  "SCP_FreshnessValueLength" INT 0 512;
BA_DEF_ BO_  "SCP_FreshnessValueTxLength" INT 0 512;
BA_DEF_ BO_  "SCP_AuthInfoTxLength" INT 0 512;
BA_DEF_ BO_  "GenMsgRoutingTimeoutTime" INT 0 5000;
BA_DEF_ BO_  "MessageGateway" ENUM  "No","Yes";
BA_DEF_ BO_  "NmAsrMessage" ENUM  "No","Yes";
BA_DEF_ BO_  "DiagState" ENUM  "No","Yes";
BA_DEF_ BO_  "TpTxIndex" INT 0 536870911;
BA_DEF_ BO_  "DiagRequest" ENUM  "No","Yes";
BA_DEF_ BO_  "DiagResponse" ENUM  "No","Yes";
BA_DEF_ BO_  "GenMsgILSupport" ENUM  "No","Yes";
BA_DEF_DEF_  "FrameRouting" "";
BA_DEF_DEF_  "FrameGatewayNetwork" "NONE";
BA_DEF_DEF_  "NetworkInitialization" "Yes";
BA_DEF_DEF_  "FrameGatewayId" 0;
BA_DEF_DEF_  "EventRateOfChange" 10000;
BA_DEF_DEF_  "GenMsgStartDelayTime" 0;
BA_DEF_DEF_  "GenMsgNrOfRepetition" 1;
BA_DEF_DEF_  "GenMsgDelayTime" 20;
BA_DEF_DEF_  "GenMsgCycleTime" 0;
BA_DEF_DEF_  "GenMsgSendType" "NoMsgSendType";
BA_DEF_DEF_  "U_CD764_MY2022_Tx" "No";
BA_DEF_DEF_  "U_U55X_MY2022_Tx" "No";
BA_DEF_DEF_  "U_CD542_MY2021_Tx" "No";
BA_DEF_DEF_  "ECGUsedTxSignal" "No";
BA_DEF_DEF_  "U_T6_MCA_MY2020_Tx" "No";
BA_DEF_DEF_  "U_P702_MY2021_Tx" "No";
BA_DEF_DEF_  "U_CX727_MY2021_Tx" "No";
BA_DEF_DEF_  "U_CD764_MY2022_Rx" "No";
BA_DEF_DEF_  "U_FNV2_IVI_Rx" "No";
BA_DEF_DEF_  "U_U55X_MY2022_Rx" "No";
BA_DEF_DEF_  "U_CD542_MY2021_Rx" "No";
BA_DEF_DEF_  "ECGUsedRxSignal" "No";
BA_DEF_DEF_  "U_T6_MCA_MY2020_Rx" "No";
BA_DEF_DEF_  "U_P702_MY2021_Rx" "No";
BA_DEF_DEF_  "U_CX727_MY2021_Rx" "No";
BA_DEF_DEF_  "GenSigStartValue" 0;
BA_DEF_DEF_  "MetaData" "No";
BA_DEF_DEF_  "ContentDependant" "No";
BA_DEF_DEF_  "GenSigStartValueInteger" 0;
BA_DEF_DEF_  "UsedOnPgmDBC" "Yes";
BA_DEF_DEF_  "WakeupSignal" "No";
BA_DEF_DEF_  "GenSigInactiveValue" 0;
BA_DEF_DEF_  "GenSigSendType" "NoSigSendType";
BA_DEF_DEF_  "OvtpPushApplication" "FALSE";
BA_DEF_DEF_  "SCP_FreshnessValueLength" 64;
BA_DEF_DEF_  "SCP_FreshnessValueTxLength" 11;
BA_DEF_DEF_  "SCP_AuthInfoTxLength" 53;
BA_DEF_DEF_  "GenMsgRoutingTimeoutTime" 0;
BA_DEF_DEF_  "MessageGateway" "No";
BA_DEF_DEF_  "NmAsrMessage" "No";
BA_DEF_DEF_  "DiagState" "No";
BA_DEF_DEF_  "TpTxIndex" 0;
BA_DEF_DEF_  "DiagRequest" "No";
BA_DEF_DEF_  "DiagResponse" "No";
BA_DEF_DEF_  "GenMsgILSupport" "Yes";
BA_ "NetworkInitialization" BO_ 508 0;
BA_ "GenMsgSendType" BO_ 508 1;
BA_ "NetworkInitialization" BO_ 507 0;
BA_ "GenMsgSendType" BO_ 507 1;
BA_ "NetworkInitialization" BO_ 506 0;
BA_ "GenMsgSendType" BO_ 506 1;
BA_ "NetworkInitialization" BO_ 505 0;
BA_ "GenMsgSendType" BO_ 505 1;
BA_ "NetworkInitialization" BO_ 504 0;
BA_ "GenMsgSendType" BO_ 504 1;
BA_ "GenMsgCycleTime" BO_ 140 1000;
BA_ "GenMsgSendType" BO_ 140 5;
BA_ "GenMsgCycleTime" BO_ 813 1000;
BA_ "GenMsgSendType" BO_ 813 5;
BA_ "NetworkInitialization" BO_ 712 0;
BA_ "TpTxIndex" BO_ 712 31;
BA_ "NetworkInitialization" BO_ 711 0;
BA_ "TpTxIndex" BO_ 711 24;
BA_ "NetworkInitialization" BO_ 703 0;
BA_ "TpTxIndex" BO_ 703 18;
BA_ "NetworkInitialization" BO_ 702 0;
BA_ "TpTxIndex" BO_ 702 17;
BA_ "NetworkInitialization" BO_ 676 0;
BA_ "TpTxIndex" BO_ 676 29;
BA_ "GenMsgCycleTime" BO_ 647 200;
BA_ "GenMsgSendType" BO_ 647 5;
BA_ "GenMsgCycleTime" BO_ 497 1000;
BA_ "GenMsgSendType" BO_ 497 5;
BA_ "NetworkInitialization" BO_ 400 0;
BA_ "GenMsgSendType" BO_ 400 1;
BA_ "TpTxIndex" BO_ 598 47;
BA_ "NetworkInitialization" BO_ 867 0;
BA_ "GenMsgSendType" BO_ 867 1;
BA_ "FrameGatewayId" BO_ 831 831;
BA_ "FrameGatewayNetwork" BO_ 831 "MS1_CAN";
BA_ "FrameGatewayId" BO_ 862 862;
BA_ "FrameGatewayNetwork" BO_ 862 "MS1_CAN";
BA_ "FrameGatewayId" BO_ 828 828;
BA_ "FrameGatewayNetwork" BO_ 828 "MS1_CAN";
BA_ "GenMsgSendType" BO_ 645 0;
BA_ "GenMsgCycleTime" BO_ 645 100;
BA_ "FrameGatewayId" BO_ 528 528;
BA_ "FrameGatewayNetwork" BO_ 528 "HS1_CAN";
BA_ "FrameRouting" BO_ 528 "HS1_CAN,0x210;";
BA_ "FrameGatewayId" BO_ 1221 1189;
BA_ "FrameGatewayNetwork" BO_ 1221 "HS5_CAN";
BA_ "FrameRouting" BO_ 1221 "HS5_CAN,0x4A5;";
BA_ "GenMsgSendType" BO_ 595 5;
BA_ "GenMsgCycleTime" BO_ 595 500;
BA_ "FrameGatewayId" BO_ 772 772;
BA_ "FrameGatewayNetwork" BO_ 772 "MS1_CAN";
BA_ "FrameRouting" BO_ 772 "MS1_CAN,0x304;";
BA_ "FrameGatewayId" BO_ 826 826;
BA_ "FrameGatewayNetwork" BO_ 826 "MS1_CAN";
BA_ "FrameRouting" BO_ 826 "MS1_CAN,0x33A;";
BA_ "FrameGatewayId" BO_ 966 966;
BA_ "FrameGatewayNetwork" BO_ 966 "HS1_CAN";
BA_ "FrameRouting" BO_ 966 "HS1_CAN,0x3C6;";
BA_ "FrameGatewayId" BO_ 773 773;
BA_ "FrameGatewayNetwork" BO_ 773 "MS1_CAN";
BA_ "FrameRouting" BO_ 773 "MS1_CAN,0x305;";
BA_ "FrameGatewayId" BO_ 303 303;
BA_ "FrameGatewayNetwork" BO_ 303 "HS1_CAN";
BA_ "FrameRouting" BO_ 303 "HS1_CAN,0x12F";
BA_ "TpTxIndex" BO_ 2612009176 464525528;
BA_ "OvtpPushApplication" BO_ 2612009176 1;
BA_ "GenMsgSendType" BO_ 2612009176 1;
BA_ "GenMsgDelayTime" BO_ 2612009176 0;
BA_ "GenMsgSendType" BO_ 746 5;
BA_ "GenMsgCycleTime" BO_ 746 1000;
BA_ "GenMsgSendType" BO_ 479 1;
BA_ "GenMsgSendType" BO_ 474 1;
BA_ "GenMsgSendType" BO_ 477 1;
BA_ "GenMsgSendType" BO_ 260 1;
BA_ "GenMsgSendType" BO_ 476 1;
BA_ "GenMsgSendType" BO_ 490 1;
BA_ "GenMsgILSupport" BO_ 1923 0;
BA_ "DiagRequest" BO_ 1923 1;
BA_ "GenMsgSendType" BO_ 1923 1;
BA_ "GenMsgDelayTime" BO_ 1923 0;
BA_ "NetworkInitialization" BO_ 1923 0;
BA_ "GenMsgILSupport" BO_ 1931 0;
BA_ "DiagResponse" BO_ 1931 1;
BA_ "GenMsgSendType" BO_ 1931 1;
BA_ "GenMsgDelayTime" BO_ 1931 0;
BA_ "NetworkInitialization" BO_ 1931 0;
BA_ "GenMsgILSupport" BO_ 1478 0;
BA_ "NmAsrMessage" BO_ 1478 1;
BA_ "GenMsgSendType" BO_ 1478 0;
BA_ "GenMsgCycleTime" BO_ 1478 1000;
BA_ "NetworkInitialization" BO_ 1478 0;
BA_ "GenMsgSendType" BO_ 1245 5;
BA_ "GenMsgCycleTime" BO_ 1245 1000;
BA_ "GenMsgSendType" BO_ 1242 5;
BA_ "GenMsgCycleTime" BO_ 1242 1000;
BA_ "GenMsgSendType" BO_ 502 1;
BA_ "FrameGatewayId" BO_ 955 955;
BA_ "FrameGatewayNetwork" BO_ 955 "HS1_CAN";
BA_ "FrameRouting" BO_ 955 "HS1_CAN,0x3BB;";
BA_ "GenMsgSendType" BO_ 1116 5;
BA_ "GenMsgCycleTime" BO_ 1116 1000;
BA_ "GenMsgSendType" BO_ 1113 0;
BA_ "GenMsgCycleTime" BO_ 1113 50;
BA_ "FrameRouting" BO_ 1255 "FD1_CAN,0x4E7;";
BA_ "FrameRouting" BO_ 1254 "FD1_CAN,0x4E6;";
BA_ "FrameRouting" BO_ 1253 "FD1_CAN,0x4E5;";
BA_ "FrameRouting" BO_ 1252 "FD1_CAN,0x4E4;";
BA_ "FrameRouting" BO_ 1251 "FD1_CAN,0x4E3;";
BA_ "FrameRouting" BO_ 1250 "FD1_CAN,0x4E2;";
BA_ "FrameRouting" BO_ 1249 "FD1_CAN,0x4E1;";
BA_ "FrameRouting" BO_ 1248 "FD1_CAN,0x4E0;";
BA_ "GenMsgSendType" BO_ 1256 5;
BA_ "GenMsgCycleTime" BO_ 1256 1000;
BA_ "GenMsgSendType" BO_ 529 5;
BA_ "GenMsgCycleTime" BO_ 529 1000;
BA_ "GenMsgSendType" BO_ 642 5;
BA_ "GenMsgCycleTime" BO_ 642 1000;
BA_ "GenMsgSendType" BO_ 893 0;
BA_ "GenMsgCycleTime" BO_ 893 1000;
BA_ "GenMsgSendType" BO_ 500 1;
BA_ "GenMsgSendType" BO_ 503 1;
BA_ "GenMsgSendType" BO_ 412 1;
BA_ "GenMsgSendType" BO_ 493 1;
BA_ "U_U55X_MY2022_Tx" SG_ 508 Mc_DB1GetInfStartInd_Rq 1;
BA_ "U_T6_MCA_MY2020_Tx" SG_ 508 Mc_DB1GetInfStartInd_Rq 1;
BA_ "U_CD764_MY2022_Rx" SG_ 508 Mc_DB1GetInfStartInd_Rq 1;
BA_ "U_U55X_MY2022_Rx" SG_ 508 Mc_DB1GetInfStartInd_Rq 1;
BA_ "U_T6_MCA_MY2020_Rx" SG_ 508 Mc_DB1GetInfStartInd_Rq 1;
BA_ "GenSigSendType" SG_ 508 Mc_DB1GetInfStartInd_Rq 1;
BA_ "U_U55X_MY2022_Tx" SG_ 508 Mc_DB1GtInfNbrOfItms_Rq 1;
BA_ "U_T6_MCA_MY2020_Tx" SG_ 508 Mc_DB1GtInfNbrOfItms_Rq 1;
BA_ "U_CD764_MY2022_Rx" SG_ 508 Mc_DB1GtInfNbrOfItms_Rq 1;
BA_ "U_U55X_MY2022_Rx" SG_ 508 Mc_DB1GtInfNbrOfItms_Rq 1;
BA_ "U_T6_MCA_MY2020_Rx" SG_ 508 Mc_DB1GtInfNbrOfItms_Rq 1;
BA_ "U_U55X_MY2022_Tx" SG_ 508 Mc_DB1GetInfSetConf_Rq 1;
BA_ "U_T6_MCA_MY2020_Tx" SG_ 508 Mc_DB1GetInfSetConf_Rq 1;
BA_ "U_CD764_MY2022_Rx" SG_ 508 Mc_DB1GetInfSetConf_Rq 1;
BA_ "U_U55X_MY2022_Rx" SG_ 508 Mc_DB1GetInfSetConf_Rq 1;
BA_ "U_T6_MCA_MY2020_Rx" SG_ 508 Mc_DB1GetInfSetConf_Rq 1;
BA_ "U_U55X_MY2022_Tx" SG_ 508 Mc_DB1GetInfSetFilt3_Rq 1;
BA_ "U_T6_MCA_MY2020_Tx" SG_ 508 Mc_DB1GetInfSetFilt3_Rq 1;
BA_ "U_CD764_MY2022_Rx" SG_ 508 Mc_DB1GetInfSetFilt3_Rq 1;
BA_ "U_U55X_MY2022_Rx" SG_ 508 Mc_DB1GetInfSetFilt3_Rq 1;
BA_ "U_T6_MCA_MY2020_Rx" SG_ 508 Mc_DB1GetInfSetFilt3_Rq 1;
BA_ "U_U55X_MY2022_Tx" SG_ 508 Mc_DB1GetInfSetFilt2_Rq 1;
BA_ "U_T6_MCA_MY2020_Tx" SG_ 508 Mc_DB1GetInfSetFilt2_Rq 1;
BA_ "U_CD764_MY2022_Rx" SG_ 508 Mc_DB1GetInfSetFilt2_Rq 1;
BA_ "U_U55X_MY2022_Rx" SG_ 508 Mc_DB1GetInfSetFilt2_Rq 1;
BA_ "U_T6_MCA_MY2020_Rx" SG_ 508 Mc_DB1GetInfSetFilt2_Rq 1;
BA_ "U_U55X_MY2022_Tx" SG_ 508 Mc_DB1GetInfSetFilt1_Rq 1;
BA_ "U_T6_MCA_MY2020_Tx" SG_ 508 Mc_DB1GetInfSetFilt1_Rq 1;
BA_ "U_CD764_MY2022_Rx" SG_ 508 Mc_DB1GetInfSetFilt1_Rq 1;
BA_ "U_U55X_MY2022_Rx" SG_ 508 Mc_DB1GetInfSetFilt1_Rq 1;
BA_ "U_T6_MCA_MY2020_Rx" SG_ 508 Mc_DB1GetInfSetFilt1_Rq 1;
BA_ "U_U55X_MY2022_Tx" SG_ 507 Mc_DB1SetTrkItmIndex_Rq 1;
BA_ "U_T6_MCA_MY2020_Tx" SG_ 507 Mc_DB1SetTrkItmIndex_Rq 1;
BA_ "U_CD764_MY2022_Rx" SG_ 507 Mc_DB1SetTrkItmIndex_Rq 1;
BA_ "U_U55X_MY2022_Rx" SG_ 507 Mc_DB1SetTrkItmIndex_Rq 1;
BA_ "U_T6_MCA_MY2020_Rx" SG_ 507 Mc_DB1SetTrkItmIndex_Rq 1;
BA_ "GenSigSendType" SG_ 507 Mc_DB1SetTrkItmIndex_Rq 1;
BA_ "U_U55X_MY2022_Tx" SG_ 507 Mc_DB1SetTrkSetConf_Rq 1;
BA_ "U_T6_MCA_MY2020_Tx" SG_ 507 Mc_DB1SetTrkSetConf_Rq 1;
BA_ "U_CD764_MY2022_Rx" SG_ 507 Mc_DB1SetTrkSetConf_Rq 1;
BA_ "U_U55X_MY2022_Rx" SG_ 507 Mc_DB1SetTrkSetConf_Rq 1;
BA_ "U_T6_MCA_MY2020_Rx" SG_ 507 Mc_DB1SetTrkSetConf_Rq 1;
BA_ "U_U55X_MY2022_Tx" SG_ 507 Mc_DB1SetTrkSetFilt3_Rq 1;
BA_ "U_T6_MCA_MY2020_Tx" SG_ 507 Mc_DB1SetTrkSetFilt3_Rq 1;
BA_ "U_CD764_MY2022_Rx" SG_ 507 Mc_DB1SetTrkSetFilt3_Rq 1;
BA_ "U_U55X_MY2022_Rx" SG_ 507 Mc_DB1SetTrkSetFilt3_Rq 1;
BA_ "U_T6_MCA_MY2020_Rx" SG_ 507 Mc_DB1SetTrkSetFilt3_Rq 1;
BA_ "U_U55X_MY2022_Tx" SG_ 507 Mc_DB1SetTrkSetFilt2_Rq 1;
BA_ "U_T6_MCA_MY2020_Tx" SG_ 507 Mc_DB1SetTrkSetFilt2_Rq 1;
BA_ "U_CD764_MY2022_Rx" SG_ 507 Mc_DB1SetTrkSetFilt2_Rq 1;
BA_ "U_U55X_MY2022_Rx" SG_ 507 Mc_DB1SetTrkSetFilt2_Rq 1;
BA_ "U_T6_MCA_MY2020_Rx" SG_ 507 Mc_DB1SetTrkSetFilt2_Rq 1;
BA_ "U_U55X_MY2022_Tx" SG_ 507 Mc_DB1SetTrkSetFilt1_Rq 1;
BA_ "U_T6_MCA_MY2020_Tx" SG_ 507 Mc_DB1SetTrkSetFilt1_Rq 1;
BA_ "U_CD764_MY2022_Rx" SG_ 507 Mc_DB1SetTrkSetFilt1_Rq 1;
BA_ "U_U55X_MY2022_Rx" SG_ 507 Mc_DB1SetTrkSetFilt1_Rq 1;
BA_ "U_T6_MCA_MY2020_Rx" SG_ 507 Mc_DB1SetTrkSetFilt1_Rq 1;
BA_ "U_U55X_MY2022_Tx" SG_ 506 Mc_AudioSourceSel3_Rq 1;
BA_ "U_T6_MCA_MY2020_Tx" SG_ 506 Mc_AudioSourceSel3_Rq 1;
BA_ "U_CD764_MY2022_Rx" SG_ 506 Mc_AudioSourceSel3_Rq 1;
BA_ "U_U55X_MY2022_Rx" SG_ 506 Mc_AudioSourceSel3_Rq 1;
BA_ "U_T6_MCA_MY2020_Rx" SG_ 506 Mc_AudioSourceSel3_Rq 1;
BA_ "GenSigSendType" SG_ 506 Mc_AudioSourceSel3_Rq 3;
BA_ "U_U55X_MY2022_Tx" SG_ 506 Mc_PlayFrstTrInFldr_Rq 1;
BA_ "U_T6_MCA_MY2020_Tx" SG_ 506 Mc_PlayFrstTrInFldr_Rq 1;
BA_ "U_CD764_MY2022_Rx" SG_ 506 Mc_PlayFrstTrInFldr_Rq 1;
BA_ "U_U55X_MY2022_Rx" SG_ 506 Mc_PlayFrstTrInFldr_Rq 1;
BA_ "U_T6_MCA_MY2020_Rx" SG_ 506 Mc_PlayFrstTrInFldr_Rq 1;
BA_ "U_U55X_MY2022_Tx" SG_ 506 Mc_ItemIndex_Rq 1;
BA_ "U_T6_MCA_MY2020_Tx" SG_ 506 Mc_ItemIndex_Rq 1;
BA_ "U_CD764_MY2022_Rx" SG_ 506 Mc_ItemIndex_Rq 1;
BA_ "U_U55X_MY2022_Rx" SG_ 506 Mc_ItemIndex_Rq 1;
BA_ "U_T6_MCA_MY2020_Rx" SG_ 506 Mc_ItemIndex_Rq 1;
BA_ "U_U55X_MY2022_Tx" SG_ 506 Mc_FolderNumber3_Rq 1;
BA_ "U_T6_MCA_MY2020_Tx" SG_ 506 Mc_FolderNumber3_Rq 1;
BA_ "U_CD764_MY2022_Rx" SG_ 506 Mc_FolderNumber3_Rq 1;
BA_ "U_U55X_MY2022_Rx" SG_ 506 Mc_FolderNumber3_Rq 1;
BA_ "U_T6_MCA_MY2020_Rx" SG_ 506 Mc_FolderNumber3_Rq 1;
BA_ "U_CD764_MY2022_Tx" SG_ 505 Mc_AudioSourceSel2_Rq 1;
BA_ "U_U55X_MY2022_Tx" SG_ 505 Mc_AudioSourceSel2_Rq 1;
BA_ "U_T6_MCA_MY2020_Tx" SG_ 505 Mc_AudioSourceSel2_Rq 1;
BA_ "U_CD764_MY2022_Rx" SG_ 505 Mc_AudioSourceSel2_Rq 1;
BA_ "U_U55X_MY2022_Rx" SG_ 505 Mc_AudioSourceSel2_Rq 1;
BA_ "U_T6_MCA_MY2020_Rx" SG_ 505 Mc_AudioSourceSel2_Rq 1;
BA_ "GenSigSendType" SG_ 505 Mc_AudioSourceSel2_Rq 3;
BA_ "U_CD764_MY2022_Tx" SG_ 505 Mc_StartItemIndexRq 1;
BA_ "U_U55X_MY2022_Tx" SG_ 505 Mc_StartItemIndexRq 1;
BA_ "U_T6_MCA_MY2020_Tx" SG_ 505 Mc_StartItemIndexRq 1;
BA_ "U_CD764_MY2022_Rx" SG_ 505 Mc_StartItemIndexRq 1;
BA_ "U_U55X_MY2022_Rx" SG_ 505 Mc_StartItemIndexRq 1;
BA_ "U_T6_MCA_MY2020_Rx" SG_ 505 Mc_StartItemIndexRq 1;
BA_ "U_CD764_MY2022_Tx" SG_ 505 Mc_NbrOfItems2_Rq 1;
BA_ "U_U55X_MY2022_Tx" SG_ 505 Mc_NbrOfItems2_Rq 1;
BA_ "U_T6_MCA_MY2020_Tx" SG_ 505 Mc_NbrOfItems2_Rq 1;
BA_ "U_CD764_MY2022_Rx" SG_ 505 Mc_NbrOfItems2_Rq 1;
BA_ "U_U55X_MY2022_Rx" SG_ 505 Mc_NbrOfItems2_Rq 1;
BA_ "U_T6_MCA_MY2020_Rx" SG_ 505 Mc_NbrOfItems2_Rq 1;
BA_ "U_CD764_MY2022_Tx" SG_ 505 Mc_ItemNameLength2_Rq 1;
BA_ "U_U55X_MY2022_Tx" SG_ 505 Mc_ItemNameLength2_Rq 1;
BA_ "U_T6_MCA_MY2020_Tx" SG_ 505 Mc_ItemNameLength2_Rq 1;
BA_ "U_CD764_MY2022_Rx" SG_ 505 Mc_ItemNameLength2_Rq 1;
BA_ "U_U55X_MY2022_Rx" SG_ 505 Mc_ItemNameLength2_Rq 1;
BA_ "U_T6_MCA_MY2020_Rx" SG_ 505 Mc_ItemNameLength2_Rq 1;
BA_ "U_CD764_MY2022_Tx" SG_ 505 Mc_CutItem2_Rq 1;
BA_ "U_U55X_MY2022_Tx" SG_ 505 Mc_CutItem2_Rq 1;
BA_ "U_T6_MCA_MY2020_Tx" SG_ 505 Mc_CutItem2_Rq 1;
BA_ "U_CD764_MY2022_Rx" SG_ 505 Mc_CutItem2_Rq 1;
BA_ "U_U55X_MY2022_Rx" SG_ 505 Mc_CutItem2_Rq 1;
BA_ "U_T6_MCA_MY2020_Rx" SG_ 505 Mc_CutItem2_Rq 1;
BA_ "U_CD764_MY2022_Tx" SG_ 505 Mc_FolderNumber2_Rq 1;
BA_ "U_U55X_MY2022_Tx" SG_ 505 Mc_FolderNumber2_Rq 1;
BA_ "U_T6_MCA_MY2020_Tx" SG_ 505 Mc_FolderNumber2_Rq 1;
BA_ "U_CD764_MY2022_Rx" SG_ 505 Mc_FolderNumber2_Rq 1;
BA_ "U_U55X_MY2022_Rx" SG_ 505 Mc_FolderNumber2_Rq 1;
BA_ "U_T6_MCA_MY2020_Rx" SG_ 505 Mc_FolderNumber2_Rq 1;
BA_ "U_CD764_MY2022_Tx" SG_ 505 Mc_FolderContent_Rq 1;
BA_ "U_U55X_MY2022_Tx" SG_ 505 Mc_FolderContent_Rq 1;
BA_ "U_T6_MCA_MY2020_Tx" SG_ 505 Mc_FolderContent_Rq 1;
BA_ "U_CD764_MY2022_Rx" SG_ 505 Mc_FolderContent_Rq 1;
BA_ "U_U55X_MY2022_Rx" SG_ 505 Mc_FolderContent_Rq 1;
BA_ "U_T6_MCA_MY2020_Rx" SG_ 505 Mc_FolderContent_Rq 1;
BA_ "U_U55X_MY2022_Tx" SG_ 504 Mc_AudioSourceSel_Rq 1;
BA_ "U_T6_MCA_MY2020_Tx" SG_ 504 Mc_AudioSourceSel_Rq 1;
BA_ "U_CD764_MY2022_Rx" SG_ 504 Mc_AudioSourceSel_Rq 1;
BA_ "U_U55X_MY2022_Rx" SG_ 504 Mc_AudioSourceSel_Rq 1;
BA_ "U_T6_MCA_MY2020_Rx" SG_ 504 Mc_AudioSourceSel_Rq 1;
BA_ "GenSigSendType" SG_ 504 Mc_AudioSourceSel_Rq 3;
BA_ "U_U55X_MY2022_Tx" SG_ 504 Mc_FolderNumber_Rq 1;
BA_ "U_T6_MCA_MY2020_Tx" SG_ 504 Mc_FolderNumber_Rq 1;
BA_ "U_CD764_MY2022_Rx" SG_ 504 Mc_FolderNumber_Rq 1;
BA_ "U_U55X_MY2022_Rx" SG_ 504 Mc_FolderNumber_Rq 1;
BA_ "U_T6_MCA_MY2020_Rx" SG_ 504 Mc_FolderNumber_Rq 1;
BA_ "U_U55X_MY2022_Tx" SG_ 504 Mc_CutItem_Rq 1;
BA_ "U_T6_MCA_MY2020_Tx" SG_ 504 Mc_CutItem_Rq 1;
BA_ "U_CD764_MY2022_Rx" SG_ 504 Mc_CutItem_Rq 1;
BA_ "U_U55X_MY2022_Rx" SG_ 504 Mc_CutItem_Rq 1;
BA_ "U_T6_MCA_MY2020_Rx" SG_ 504 Mc_CutItem_Rq 1;
BA_ "U_U55X_MY2022_Tx" SG_ 504 Mc_ItemNameLength_Rq 1;
BA_ "U_T6_MCA_MY2020_Tx" SG_ 504 Mc_ItemNameLength_Rq 1;
BA_ "U_CD764_MY2022_Rx" SG_ 504 Mc_ItemNameLength_Rq 1;
BA_ "U_U55X_MY2022_Rx" SG_ 504 Mc_ItemNameLength_Rq 1;
BA_ "U_T6_MCA_MY2020_Rx" SG_ 504 Mc_ItemNameLength_Rq 1;
BA_ "U_U55X_MY2022_Tx" SG_ 504 Mc_SourceSetTrack_Rq 1;
BA_ "U_T6_MCA_MY2020_Tx" SG_ 504 Mc_SourceSetTrack_Rq 1;
BA_ "U_U55X_MY2022_Rx" SG_ 504 Mc_SourceSetTrack_Rq 1;
BA_ "U_T6_MCA_MY2020_Rx" SG_ 504 Mc_SourceSetTrack_Rq 1;
BA_ "GenSigSendType" SG_ 140 DcacPwResetBttn_D_Stat 3;
BA_ "U_U55X_MY2022_Tx" SG_ 140 CcAslButtnIndxIncPress2 1;
BA_ "U_T6_MCA_MY2020_Tx" SG_ 140 CcAslButtnIndxIncPress2 1;
BA_ "GenSigSendType" SG_ 140 CcAslButtnIndxIncPress2 3;
BA_ "U_U55X_MY2022_Tx" SG_ 140 SteWhlSwtchMde_D_Stat 1;
BA_ "U_CD542_MY2021_Tx" SG_ 140 SteWhlSwtchMde_D_Stat 1;
BA_ "U_T6_MCA_MY2020_Tx" SG_ 140 SteWhlSwtchMde_D_Stat 1;
BA_ "GenSigSendType" SG_ 140 SteWhlSwtchMde_D_Stat 3;
BA_ "U_U55X_MY2022_Tx" SG_ 140 CcAslButtnOffCnclPress2 1;
BA_ "U_T6_MCA_MY2020_Tx" SG_ 140 CcAslButtnOffCnclPress2 1;
BA_ "GenSigSendType" SG_ 140 CcAslButtnOffCnclPress2 3;
BA_ "U_U55X_MY2022_Tx" SG_ 140 CcAslButtnIndxDecPress2 1;
BA_ "U_T6_MCA_MY2020_Tx" SG_ 140 CcAslButtnIndxDecPress2 1;
BA_ "GenSigSendType" SG_ 140 CcAslButtnIndxDecPress2 3;
BA_ "U_U55X_MY2022_Tx" SG_ 140 CcAslButtnCnclResPress2 1;
BA_ "U_T6_MCA_MY2020_Tx" SG_ 140 CcAslButtnCnclResPress2 1;
BA_ "GenSigSendType" SG_ 140 CcAslButtnCnclResPress2 3;
BA_ "U_U55X_MY2022_Tx" SG_ 140 CcAslButtnResIncPress3 1;
BA_ "U_T6_MCA_MY2020_Tx" SG_ 140 CcAslButtnResIncPress3 1;
BA_ "GenSigSendType" SG_ 140 CcAslButtnResIncPress3 3;
BA_ "U_U55X_MY2022_Tx" SG_ 140 CcButtnOnPress3 1;
BA_ "U_T6_MCA_MY2020_Tx" SG_ 140 CcButtnOnPress3 1;
BA_ "GenSigSendType" SG_ 140 CcButtnOnPress3 3;
BA_ "U_U55X_MY2022_Tx" SG_ 140 CcButtnOnOffPress3 1;
BA_ "U_T6_MCA_MY2020_Tx" SG_ 140 CcButtnOnOffPress3 1;
BA_ "GenSigSendType" SG_ 140 CcButtnOnOffPress3 3;
BA_ "U_U55X_MY2022_Tx" SG_ 140 CcButtnOnOffCnclPress3 1;
BA_ "U_T6_MCA_MY2020_Tx" SG_ 140 CcButtnOnOffCnclPress3 1;
BA_ "GenSigSendType" SG_ 140 CcButtnOnOffCnclPress3 3;
BA_ "U_U55X_MY2022_Tx" SG_ 140 CcButtnOffPress3 1;
BA_ "U_T6_MCA_MY2020_Tx" SG_ 140 CcButtnOffPress3 1;
BA_ "GenSigSendType" SG_ 140 CcButtnOffPress3 3;
BA_ "U_U55X_MY2022_Tx" SG_ 140 CcAsllButtnResPress3 1;
BA_ "U_T6_MCA_MY2020_Tx" SG_ 140 CcAsllButtnResPress3 1;
BA_ "GenSigSendType" SG_ 140 CcAsllButtnResPress3 3;
BA_ "U_U55X_MY2022_Tx" SG_ 140 CcAslButtnSetPress3 1;
BA_ "U_T6_MCA_MY2020_Tx" SG_ 140 CcAslButtnSetPress3 1;
BA_ "GenSigSendType" SG_ 140 CcAslButtnSetPress3 3;
BA_ "U_U55X_MY2022_Tx" SG_ 140 CcAslButtnSetIncPress3 1;
BA_ "U_T6_MCA_MY2020_Tx" SG_ 140 CcAslButtnSetIncPress3 1;
BA_ "GenSigSendType" SG_ 140 CcAslButtnSetIncPress3 3;
BA_ "U_U55X_MY2022_Tx" SG_ 140 CcAslButtnSetDecPress3 1;
BA_ "U_T6_MCA_MY2020_Tx" SG_ 140 CcAslButtnSetDecPress3 1;
BA_ "GenSigSendType" SG_ 140 CcAslButtnSetDecPress3 3;
BA_ "U_U55X_MY2022_Tx" SG_ 140 CcAslButtnResDecPress3 1;
BA_ "U_T6_MCA_MY2020_Tx" SG_ 140 CcAslButtnResDecPress3 1;
BA_ "GenSigSendType" SG_ 140 CcAslButtnResDecPress3 3;
BA_ "U_U55X_MY2022_Tx" SG_ 140 CcAslButtnOnPress3 1;
BA_ "U_T6_MCA_MY2020_Tx" SG_ 140 CcAslButtnOnPress3 1;
BA_ "GenSigSendType" SG_ 140 CcAslButtnOnPress3 3;
BA_ "U_U55X_MY2022_Tx" SG_ 140 CcAslButtnOnOffCncl3 1;
BA_ "U_T6_MCA_MY2020_Tx" SG_ 140 CcAslButtnOnOffCncl3 1;
BA_ "GenSigSendType" SG_ 140 CcAslButtnOnOffCncl3 3;
BA_ "U_U55X_MY2022_Tx" SG_ 140 CcAslButtnDeny_B_Actl3 1;
BA_ "U_T6_MCA_MY2020_Tx" SG_ 140 CcAslButtnDeny_B_Actl3 1;
BA_ "GenSigSendType" SG_ 140 CcAslButtnDeny_B_Actl3 3;
BA_ "U_U55X_MY2022_Tx" SG_ 140 CcAslButtnCnclPress3 1;
BA_ "U_T6_MCA_MY2020_Tx" SG_ 140 CcAslButtnCnclPress3 1;
BA_ "GenSigSendType" SG_ 140 CcAslButtnCnclPress3 3;
BA_ "U_U55X_MY2022_Tx" SG_ 140 AslButtnOnOffPress3 1;
BA_ "U_T6_MCA_MY2020_Tx" SG_ 140 AslButtnOnOffPress3 1;
BA_ "GenSigSendType" SG_ 140 AslButtnOnOffPress3 3;
BA_ "U_U55X_MY2022_Tx" SG_ 140 AslButtnOnOffCnclPress2 1;
BA_ "U_T6_MCA_MY2020_Tx" SG_ 140 AslButtnOnOffCnclPress2 1;
BA_ "GenSigSendType" SG_ 140 AslButtnOnOffCnclPress2 3;
BA_ "U_CD542_MY2021_Tx" SG_ 813 TimerTripCurnt_T_Dsply 1;
BA_ "U_U55X_MY2022_Rx" SG_ 813 TimerTripCurnt_T_Dsply 1;
BA_ "U_CD542_MY2021_Rx" SG_ 813 TimerTripCurnt_T_Dsply 1;
BA_ "GenSigSendType" SG_ 813 TimerTripCurnt_T_Dsply 3;
BA_ "U_CD764_MY2022_Tx" SG_ 712 NAV_MC_WORD_Rx 1;
BA_ "U_U55X_MY2022_Tx" SG_ 712 NAV_MC_WORD_Rx 1;
BA_ "U_CD764_MY2022_Rx" SG_ 712 NAV_MC_WORD_Rx 1;
BA_ "U_U55X_MY2022_Rx" SG_ 712 NAV_MC_WORD_Rx 1;
BA_ "U_CD542_MY2021_Rx" SG_ 712 NAV_MC_WORD_Rx 1;
BA_ "U_T6_MCA_MY2020_Rx" SG_ 712 NAV_MC_WORD_Rx 1;
BA_ "U_U55X_MY2022_Tx" SG_ 711 MyKeySrvr_Clnt_Word_Tx 1;
BA_ "U_T6_MCA_MY2020_Tx" SG_ 711 MyKeySrvr_Clnt_Word_Tx 1;
BA_ "U_U55X_MY2022_Rx" SG_ 711 MyKeySrvr_Clnt_Word_Tx 1;
BA_ "U_CD542_MY2021_Rx" SG_ 711 MyKeySrvr_Clnt_Word_Tx 1;
BA_ "U_T6_MCA_MY2020_Rx" SG_ 711 MyKeySrvr_Clnt_Word_Tx 1;
BA_ "U_P702_MY2021_Rx" SG_ 711 MyKeySrvr_Clnt_Word_Tx 1;
BA_ "U_CD764_MY2022_Tx" SG_ 703 CONMP_MC_WORD_Rx 1;
BA_ "U_CD542_MY2021_Tx" SG_ 703 CONMP_MC_WORD_Rx 1;
BA_ "U_CD764_MY2022_Rx" SG_ 703 CONMP_MC_WORD_Rx 1;
BA_ "U_U55X_MY2022_Rx" SG_ 703 CONMP_MC_WORD_Rx 1;
BA_ "U_CD542_MY2021_Rx" SG_ 703 CONMP_MC_WORD_Rx 1;
BA_ "U_T6_MCA_MY2020_Rx" SG_ 703 CONMP_MC_WORD_Rx 1;
BA_ "U_CD764_MY2022_Tx" SG_ 702 PHONE_MC_WORD_Rx 1;
BA_ "U_U55X_MY2022_Tx" SG_ 702 PHONE_MC_WORD_Rx 1;
BA_ "U_CD542_MY2021_Tx" SG_ 702 PHONE_MC_WORD_Rx 1;
BA_ "U_T6_MCA_MY2020_Tx" SG_ 702 PHONE_MC_WORD_Rx 1;
BA_ "U_CD764_MY2022_Rx" SG_ 702 PHONE_MC_WORD_Rx 1;
BA_ "U_U55X_MY2022_Rx" SG_ 702 PHONE_MC_WORD_Rx 1;
BA_ "U_CD542_MY2021_Rx" SG_ 702 PHONE_MC_WORD_Rx 1;
BA_ "U_T6_MCA_MY2020_Rx" SG_ 702 PHONE_MC_WORD_Rx 1;
BA_ "U_P702_MY2021_Rx" SG_ 702 PHONE_MC_WORD_Rx 1;
BA_ "U_CD764_MY2022_Tx" SG_ 676 MC_RDISP_WORD_Tx 1;
BA_ "U_U55X_MY2022_Tx" SG_ 676 MC_RDISP_WORD_Tx 1;
BA_ "U_CD542_MY2021_Tx" SG_ 676 MC_RDISP_WORD_Tx 1;
BA_ "U_T6_MCA_MY2020_Tx" SG_ 676 MC_RDISP_WORD_Tx 1;
BA_ "U_CD764_MY2022_Rx" SG_ 676 MC_RDISP_WORD_Tx 1;
BA_ "U_U55X_MY2022_Rx" SG_ 676 MC_RDISP_WORD_Tx 1;
BA_ "U_CD542_MY2021_Rx" SG_ 676 MC_RDISP_WORD_Tx 1;
BA_ "U_T6_MCA_MY2020_Rx" SG_ 676 MC_RDISP_WORD_Tx 1;
BA_ "U_P702_MY2021_Rx" SG_ 676 MC_RDISP_WORD_Tx 1;
BA_ "U_CD764_MY2022_Tx" SG_ 647 HEC_BTIncomingCall_Rq 1;
BA_ "U_T6_MCA_MY2020_Tx" SG_ 647 HEC_BTIncomingCall_Rq 1;
BA_ "U_CD764_MY2022_Rx" SG_ 647 HEC_BTIncomingCall_Rq 1;
BA_ "U_U55X_MY2022_Rx" SG_ 647 HEC_BTIncomingCall_Rq 1;
BA_ "U_T6_MCA_MY2020_Rx" SG_ 647 HEC_BTIncomingCall_Rq 1;
BA_ "GenSigSendType" SG_ 647 HEC_BTIncomingCall_Rq 3;
BA_ "U_CD764_MY2022_Tx" SG_ 647 HEC_BTEndTelService_Rq 1;
BA_ "U_T6_MCA_MY2020_Tx" SG_ 647 HEC_BTEndTelService_Rq 1;
BA_ "U_CD764_MY2022_Rx" SG_ 647 HEC_BTEndTelService_Rq 1;
BA_ "U_U55X_MY2022_Rx" SG_ 647 HEC_BTEndTelService_Rq 1;
BA_ "U_T6_MCA_MY2020_Rx" SG_ 647 HEC_BTEndTelService_Rq 1;
BA_ "GenSigSendType" SG_ 647 HEC_BTEndTelService_Rq 3;
BA_ "U_CD764_MY2022_Tx" SG_ 497 McEvntNotfnMsgId_No_Rq 1;
BA_ "U_CD764_MY2022_Rx" SG_ 497 McEvntNotfnMsgId_No_Rq 1;
BA_ "U_U55X_MY2022_Rx" SG_ 497 McEvntNotfnMsgId_No_Rq 1;
BA_ "U_CD764_MY2022_Tx" SG_ 497 McEvntNotfnMsgId_D_Rq 1;
BA_ "U_CD764_MY2022_Rx" SG_ 497 McEvntNotfnMsgId_D_Rq 1;
BA_ "U_U55X_MY2022_Rx" SG_ 497 McEvntNotfnMsgId_D_Rq 1;
BA_ "GenSigSendType" SG_ 497 McEvntNotfnMsgId_D_Rq 3;
BA_ "U_CD764_MY2022_Tx" SG_ 497 McEvntNotfnData3_D_Rq 1;
BA_ "U_CD764_MY2022_Rx" SG_ 497 McEvntNotfnData3_D_Rq 1;
BA_ "U_U55X_MY2022_Rx" SG_ 497 McEvntNotfnData3_D_Rq 1;
BA_ "GenSigSendType" SG_ 497 McEvntNotfnData3_D_Rq 3;
BA_ "U_CD764_MY2022_Tx" SG_ 497 McEvntNotfnData2_D_Rq 1;
BA_ "U_CD764_MY2022_Rx" SG_ 497 McEvntNotfnData2_D_Rq 1;
BA_ "U_U55X_MY2022_Rx" SG_ 497 McEvntNotfnData2_D_Rq 1;
BA_ "GenSigSendType" SG_ 497 McEvntNotfnData2_D_Rq 3;
BA_ "U_CD764_MY2022_Tx" SG_ 497 McEvntNotfnData1_D_Rq 1;
BA_ "U_CD764_MY2022_Rx" SG_ 497 McEvntNotfnData1_D_Rq 1;
BA_ "U_U55X_MY2022_Rx" SG_ 497 McEvntNotfnData1_D_Rq 1;
BA_ "GenSigSendType" SG_ 497 McEvntNotfnData1_D_Rq 3;
BA_ "U_CD764_MY2022_Tx" SG_ 497 McEvntNotfnChoice_D_Rq 1;
BA_ "U_CD764_MY2022_Rx" SG_ 497 McEvntNotfnChoice_D_Rq 1;
BA_ "U_U55X_MY2022_Rx" SG_ 497 McEvntNotfnChoice_D_Rq 1;
BA_ "GenSigSendType" SG_ 497 McEvntNotfnChoice_D_Rq 3;
BA_ "U_CD764_MY2022_Rx" SG_ 400 Mc_SetCurrStatMCCh_Rq 1;
BA_ "U_U55X_MY2022_Rx" SG_ 400 Mc_SetCurrStatMCCh_Rq 1;
BA_ "U_T6_MCA_MY2020_Rx" SG_ 400 Mc_SetCurrStatMCCh_Rq 1;
BA_ "U_CD764_MY2022_Rx" SG_ 400 Mc_SetCurrntStatFreq_Rq 1;
BA_ "U_U55X_MY2022_Rx" SG_ 400 Mc_SetCurrntStatFreq_Rq 1;
BA_ "U_T6_MCA_MY2020_Rx" SG_ 400 Mc_SetCurrntStatFreq_Rq 1;
BA_ "U_CD764_MY2022_Rx" SG_ 400 Mc_SetCurrentStatOp_Rq 1;
BA_ "U_U55X_MY2022_Rx" SG_ 400 Mc_SetCurrentStatOp_Rq 1;
BA_ "U_T6_MCA_MY2020_Rx" SG_ 400 Mc_SetCurrentStatOp_Rq 1;
BA_ "GenSigSendType" SG_ 400 Mc_SetCurrentStatOp_Rq 3;
BA_ "U_T6_MCA_MY2020_Tx" SG_ 400 Mc_PerTUStartIndex2_Rq 1;
BA_ "U_U55X_MY2022_Rx" SG_ 400 Mc_PerTUStartIndex2_Rq 1;
BA_ "U_CD542_MY2021_Rx" SG_ 400 Mc_PerTUStartIndex2_Rq 1;
BA_ "U_T6_MCA_MY2020_Rx" SG_ 400 Mc_PerTUStartIndex2_Rq 1;
BA_ "U_T6_MCA_MY2020_Tx" SG_ 400 Mc_PerTUPresetArea_Rq 1;
BA_ "U_U55X_MY2022_Rx" SG_ 400 Mc_PerTUPresetArea_Rq 1;
BA_ "U_CD542_MY2021_Rx" SG_ 400 Mc_PerTUPresetArea_Rq 1;
BA_ "U_T6_MCA_MY2020_Rx" SG_ 400 Mc_PerTUPresetArea_Rq 1;
BA_ "GenSigSendType" SG_ 400 Mc_PerTUPresetArea_Rq 3;
BA_ "U_T6_MCA_MY2020_Tx" SG_ 400 Mc_PerTUNbrOfPresets_Rq 1;
BA_ "U_U55X_MY2022_Rx" SG_ 400 Mc_PerTUNbrOfPresets_Rq 1;
BA_ "U_CD542_MY2021_Rx" SG_ 400 Mc_PerTUNbrOfPresets_Rq 1;
BA_ "U_T6_MCA_MY2020_Rx" SG_ 400 Mc_PerTUNbrOfPresets_Rq 1;
BA_ "U_CD764_MY2022_Tx" SG_ 598 CONMP_RSE_WORD_Tx 1;
BA_ "U_U55X_MY2022_Tx" SG_ 598 CONMP_RSE_WORD_Tx 1;
BA_ "U_CD542_MY2021_Tx" SG_ 598 CONMP_RSE_WORD_Tx 1;
BA_ "U_T6_MCA_MY2020_Tx" SG_ 598 CONMP_RSE_WORD_Tx 1;
BA_ "U_U55X_MY2022_Rx" SG_ 598 CONMP_RSE_WORD_Tx 1;
BA_ "U_U55X_MY2022_Tx" SG_ 867 Front_Blower_Ind 1;
BA_ "U_CD542_MY2021_Tx" SG_ 867 Front_Blower_Ind 1;
BA_ "U_T6_MCA_MY2020_Tx" SG_ 867 Front_Blower_Ind 1;
BA_ "U_CD764_MY2022_Rx" SG_ 867 Front_Blower_Ind 1;
BA_ "U_CD542_MY2021_Rx" SG_ 867 Front_Blower_Ind 1;
BA_ "GenSigStartValue" SG_ 867 Front_Blower_Ind 15;
BA_ "GenSigStartValueInteger" SG_ 867 Front_Blower_Ind 15;
BA_ "GenSigSendType" SG_ 867 Front_Blower_Ind 1;
BA_ "U_U55X_MY2022_Tx" SG_ 867 LHS_Temp_Disp_Digit3 1;
BA_ "U_CD542_MY2021_Tx" SG_ 867 LHS_Temp_Disp_Digit3 1;
BA_ "U_T6_MCA_MY2020_Tx" SG_ 867 LHS_Temp_Disp_Digit3 1;
BA_ "U_CD764_MY2022_Rx" SG_ 867 LHS_Temp_Disp_Digit3 1;
BA_ "U_U55X_MY2022_Rx" SG_ 867 LHS_Temp_Disp_Digit3 1;
BA_ "U_T6_MCA_MY2020_Rx" SG_ 867 LHS_Temp_Disp_Digit3 1;
BA_ "GenSigSendType" SG_ 867 LHS_Temp_Disp_Digit3 1;
BA_ "U_U55X_MY2022_Tx" SG_ 867 LHS_Temp_Disp_Digit2 1;
BA_ "U_CD542_MY2021_Tx" SG_ 867 LHS_Temp_Disp_Digit2 1;
BA_ "U_T6_MCA_MY2020_Tx" SG_ 867 LHS_Temp_Disp_Digit2 1;
BA_ "U_CD764_MY2022_Rx" SG_ 867 LHS_Temp_Disp_Digit2 1;
BA_ "U_U55X_MY2022_Rx" SG_ 867 LHS_Temp_Disp_Digit2 1;
BA_ "U_T6_MCA_MY2020_Rx" SG_ 867 LHS_Temp_Disp_Digit2 1;
BA_ "GenSigSendType" SG_ 867 LHS_Temp_Disp_Digit2 1;
BA_ "U_U55X_MY2022_Tx" SG_ 867 LHS_Temp_Disp_Digit1 1;
BA_ "U_CD542_MY2021_Tx" SG_ 867 LHS_Temp_Disp_Digit1 1;
BA_ "U_T6_MCA_MY2020_Tx" SG_ 867 LHS_Temp_Disp_Digit1 1;
BA_ "U_CD764_MY2022_Rx" SG_ 867 LHS_Temp_Disp_Digit1 1;
BA_ "U_U55X_MY2022_Rx" SG_ 867 LHS_Temp_Disp_Digit1 1;
BA_ "U_T6_MCA_MY2020_Rx" SG_ 867 LHS_Temp_Disp_Digit1 1;
BA_ "GenSigSendType" SG_ 867 LHS_Temp_Disp_Digit1 1;
BA_ "U_U55X_MY2022_Tx" SG_ 867 EATC_LHS_Unit 1;
BA_ "U_CD542_MY2021_Tx" SG_ 867 EATC_LHS_Unit 1;
BA_ "U_T6_MCA_MY2020_Tx" SG_ 867 EATC_LHS_Unit 1;
BA_ "U_CD764_MY2022_Rx" SG_ 867 EATC_LHS_Unit 1;
BA_ "U_U55X_MY2022_Rx" SG_ 867 EATC_LHS_Unit 1;
BA_ "U_T6_MCA_MY2020_Rx" SG_ 867 EATC_LHS_Unit 1;
BA_ "GenSigSendType" SG_ 867 EATC_LHS_Unit 1;
BA_ "WakeupSignal" SG_ 831 RearDriverWindowPos 1;
BA_ "GenSigSendType" SG_ 831 RearDriverWindowPos 3;
BA_ "U_P702_MY2021_Rx" SG_ 831 RearDriverWindowPos 1;
BA_ "U_T6_MCA_MY2020_Rx" SG_ 831 RearDriverWindowPos 1;
BA_ "U_CD542_MY2021_Rx" SG_ 831 RearDriverWindowPos 1;
BA_ "U_U55X_MY2022_Rx" SG_ 831 RearDriverWindowPos 1;
BA_ "U_CD764_MY2022_Rx" SG_ 831 RearDriverWindowPos 1;
BA_ "WakeupSignal" SG_ 831 DriverWindowPosition 1;
BA_ "GenSigSendType" SG_ 831 DriverWindowPosition 3;
BA_ "U_P702_MY2021_Rx" SG_ 831 DriverWindowPosition 1;
BA_ "U_T6_MCA_MY2020_Rx" SG_ 831 DriverWindowPosition 1;
BA_ "U_CD542_MY2021_Rx" SG_ 831 DriverWindowPosition 1;
BA_ "U_U55X_MY2022_Rx" SG_ 831 DriverWindowPosition 1;
BA_ "U_CD764_MY2022_Rx" SG_ 831 DriverWindowPosition 1;
BA_ "GenSigSendType" SG_ 862 HvacBlwrFront_D_Stat 3;
BA_ "U_T6_MCA_MY2020_Rx" SG_ 862 HvacBlwrFront_D_Stat 1;
BA_ "U_U55X_MY2022_Rx" SG_ 862 HvacBlwrFront_D_Stat 1;
BA_ "U_CD764_MY2022_Rx" SG_ 862 HvacBlwrFront_D_Stat 1;
BA_ "GenSigStartValueInteger" SG_ 862 CabnAmb_Te_Actl 114;
BA_ "U_T6_MCA_MY2020_Rx" SG_ 862 CabnAmb_Te_Actl 1;
BA_ "U_CD542_MY2021_Rx" SG_ 862 CabnAmb_Te_Actl 1;
BA_ "U_U55X_MY2022_Rx" SG_ 862 CabnAmb_Te_Actl 1;
BA_ "U_CD764_MY2022_Rx" SG_ 862 CabnAmb_Te_Actl 1;
BA_ "WakeupSignal" SG_ 828 RearPassWindowPos 1;
BA_ "GenSigSendType" SG_ 828 RearPassWindowPos 3;
BA_ "U_P702_MY2021_Rx" SG_ 828 RearPassWindowPos 1;
BA_ "U_T6_MCA_MY2020_Rx" SG_ 828 RearPassWindowPos 1;
BA_ "U_CD542_MY2021_Rx" SG_ 828 RearPassWindowPos 1;
BA_ "U_U55X_MY2022_Rx" SG_ 828 RearPassWindowPos 1;
BA_ "U_CD764_MY2022_Rx" SG_ 828 RearPassWindowPos 1;
BA_ "WakeupSignal" SG_ 828 PassWindowPosition 1;
BA_ "GenSigSendType" SG_ 828 PassWindowPosition 3;
BA_ "U_T6_MCA_MY2020_Rx" SG_ 828 PassWindowPosition 1;
BA_ "U_U55X_MY2022_Rx" SG_ 828 PassWindowPosition 1;
BA_ "U_CD764_MY2022_Rx" SG_ 828 PassWindowPosition 1;
BA_ "U_CD542_MY2021_Rx" SG_ 828 PassWindowPosition 1;
BA_ "ECGUsedTxSignal" SG_ 645 VehImpactCode_No2_Actl 1;
BA_ "GenSigStartValue" SG_ 1040 VehSimSnd_Pc_Rq 511;
BA_ "GenSigStartValueInteger" SG_ 1040 BattTrac_I2_EstVsc 15000;
BA_ "GenSigStartValue" SG_ 1040 BattTrac_I2_EstVsc 262142;
BA_ "GenSigStartValue" SG_ 528 TireRear_P_OffRoad2 255;
BA_ "GenSigStartValue" SG_ 528 TireRear_P_OffRoad1 255;
BA_ "GenSigStartValue" SG_ 528 TireFront_P_OffRoad2 255;
BA_ "GenSigStartValue" SG_ 528 TireFront_P_OffRoad1 255;
BA_ "GenSigStartValueInteger" SG_ 1221 BattTracUMxArry_No_Actl 31;
BA_ "GenSigStartValue" SG_ 1221 BattTracUMxArry_No_Actl 31;
BA_ "GenSigStartValueInteger" SG_ 1221 BattTracCellUMx_No_Actl 254;
BA_ "GenSigStartValue" SG_ 1221 BattTracCellUMx_No_Actl 254;
BA_ "GenSigStartValueInteger" SG_ 1221 BattTracCellUMn_No_Actl 254;
BA_ "GenSigStartValue" SG_ 1221 BattTracCellUMn_No_Actl 254;
BA_ "GenSigStartValueInteger" SG_ 1221 BattTracCellCnt_No_Actl 254;
BA_ "GenSigStartValue" SG_ 1221 BattTracCellCnt_No_Actl 254;
BA_ "GenSigStartValueInteger" SG_ 1221 BattTracTeMx_No_Actl 254;
BA_ "GenSigStartValue" SG_ 1221 BattTracTeMx_No_Actl 254;
BA_ "GenSigStartValueInteger" SG_ 1221 BattTracTeMn_No_Actl 254;
BA_ "GenSigStartValue" SG_ 1221 BattTracTeMn_No_Actl 254;
BA_ "GenSigStartValueInteger" SG_ 1221 BattTracTeCnt_No_Actl 254;
BA_ "GenSigStartValue" SG_ 1221 BattTracTeCnt_No_Actl 254;
BA_ "GenSigStartValue" SG_ 595 DrvIdMde_D_Rq 1;
BA_ "GenSigSendType" SG_ 595 DrvIdMde_D_Rq 3;
BA_ "U_CD764_MY2022_Tx" SG_ 595 DrvIdMde_D_Rq 1;
BA_ "GenSigSendType" SG_ 595 DrvIdDelete_No_Rq 3;
BA_ "U_CD764_MY2022_Tx" SG_ 595 DrvIdDelete_No_Rq 1;
BA_ "WakeupSignal" SG_ 772 SeatScrnDrvOn_B_Rq 1;
BA_ "U_P702_MY2021_Rx" SG_ 772 SeatScrnDrvOn_B_Rq 1;
BA_ "U_T6_MCA_MY2020_Rx" SG_ 772 SeatScrnDrvOn_B_Rq 1;
BA_ "U_U55X_MY2022_Rx" SG_ 772 SeatScrnDrvOn_B_Rq 1;
BA_ "U_CD542_MY2021_Rx" SG_ 772 SeatScrnDrvOn_B_Rq 1;
BA_ "U_CD764_MY2022_Rx" SG_ 772 SeatScrnDrvOn_B_Rq 1;
BA_ "U_T6_MCA_MY2020_Rx" SG_ 772 PwRnngBoardT_D_Stat 1;
BA_ "U_U55X_MY2022_Rx" SG_ 772 PwRnngBoardT_D_Stat 1;
BA_ "U_CD764_MY2022_Rx" SG_ 772 PwRnngBoardT_D_Stat 1;
BA_ "U_CD542_MY2021_Rx" SG_ 772 PwRnngBoardT_D_Stat 1;
BA_ "U_T6_MCA_MY2020_Rx" SG_ 772 PwRnngBoardSwtch_D_Stat 1;
BA_ "U_CD542_MY2021_Rx" SG_ 772 PwRnngBoardSwtch_D_Stat 1;
BA_ "U_U55X_MY2022_Rx" SG_ 772 PwRnngBoardSwtch_D_Stat 1;
BA_ "U_CD764_MY2022_Rx" SG_ 772 PwRnngBoardSwtch_D_Stat 1;
BA_ "U_CD764_MY2022_Rx" SG_ 772 SeatSlprPosMsgTxt_B_Rq 1;
BA_ "U_P702_MY2021_Rx" SG_ 772 MemDrvDeny_B_Stat 1;
BA_ "U_T6_MCA_MY2020_Rx" SG_ 772 MemDrvDeny_B_Stat 1;
BA_ "U_CD542_MY2021_Rx" SG_ 772 MemDrvDeny_B_Stat 1;
BA_ "U_U55X_MY2022_Rx" SG_ 772 MemDrvDeny_B_Stat 1;
BA_ "U_CD764_MY2022_Rx" SG_ 772 MemDrvDeny_B_Stat 1;
BA_ "WakeupSignal" SG_ 772 Memory_Feedback_Rqst 1;
BA_ "U_P702_MY2021_Rx" SG_ 772 Memory_Feedback_Rqst 1;
BA_ "U_T6_MCA_MY2020_Rx" SG_ 772 Memory_Feedback_Rqst 1;
BA_ "U_CD542_MY2021_Rx" SG_ 772 Memory_Feedback_Rqst 1;
BA_ "U_U55X_MY2022_Rx" SG_ 772 Memory_Feedback_Rqst 1;
BA_ "U_CD764_MY2022_Rx" SG_ 772 Memory_Feedback_Rqst 1;
BA_ "WakeupSignal" SG_ 772 Easy_Entry_Rqst 1;
BA_ "WakeupSignal" SG_ 772 Memory_Cmd 1;
BA_ "U_P702_MY2021_Rx" SG_ 772 Memory_Cmd 1;
BA_ "U_T6_MCA_MY2020_Rx" SG_ 772 Memory_Cmd 1;
BA_ "U_CD542_MY2021_Rx" SG_ 772 Memory_Cmd 1;
BA_ "U_U55X_MY2022_Rx" SG_ 772 Memory_Cmd 1;
BA_ "U_CD764_MY2022_Rx" SG_ 772 Memory_Cmd 1;
BA_ "WakeupSignal" SG_ 772 Cancel_Auto_Movement 1;
BA_ "U_CD764_MY2022_Rx" SG_ 772 Cancel_Auto_Movement 1;
BA_ "WakeupSignal" SG_ 826 Memory_3_Sw_Stat 1;
BA_ "WakeupSignal" SG_ 826 Memory_2_Sw_Stat 1;
BA_ "WakeupSignal" SG_ 826 Memory_1_Sw_Stat 1;
BA_ "WakeupSignal" SG_ 826 Mirror_Manual_Override 1;
BA_ "U_CD764_MY2022_Rx" SG_ 826 Mirror_Manual_Override 1;
BA_ "WakeupSignal" SG_ 966 PwTrnkFrontRleas_D_Src 1;
BA_ "WakeupSignal" SG_ 966 TrunkFrontOpen_No_Actl 1;
BA_ "WakeupSignal" SG_ 966 TrunkFrontRolCd_No_Actl 1;
BA_ "U_CD764_MY2022_Rx" SG_ 773 StmsScrnPsngrOn_B_Rq 1;
BA_ "U_P702_MY2021_Rx" SG_ 773 SeatScrnPsngrOn_B_Rq 1;
BA_ "U_T6_MCA_MY2020_Rx" SG_ 773 SeatScrnPsngrOn_B_Rq 1;
BA_ "U_CD542_MY2021_Rx" SG_ 773 SeatScrnPsngrOn_B_Rq 1;
BA_ "U_U55X_MY2022_Rx" SG_ 773 SeatScrnPsngrOn_B_Rq 1;
BA_ "U_CD764_MY2022_Rx" SG_ 773 SeatScrnPsngrOn_B_Rq 1;
BA_ "ContentDependant" SG_ 303 CanMsg12F_No_Crc 1;
BA_ "MetaData" SG_ 303 CanMsg12F_No_Crc 1;
BA_ "ContentDependant" SG_ 303 CanMsg12F_No_Cnt 1;
BA_ "MetaData" SG_ 303 CanMsg12F_No_Cnt 1;
BA_ "WakeupSignal" SG_ 303 DrStatHood_D2_Actl 1;
BA_ "U_CD764_MY2022_Rx" SG_ 303 DrStatHood_D2_Actl 1;
BA_ "GenSigSendType" SG_ 2612009176 PARSEDPushFcGWM_ECGtoHUD 3;
BA_ "U_CD764_MY2022_Rx" SG_ 2612009176 PARSEDPushFcGWM_ECGtoHUD 1;
BA_ "ECGUsedTxSignal" SG_ 2612009176 PARSEDPushFcGWM_ECGtoHUD 1;
BA_ "U_CD764_MY2022_Tx" SG_ 2612009176 PARSEDPushFcGWM_ECGtoHUD 1;
BA_ "GenSigSendType" SG_ 746 Con_BTAud_Shuffle_St 3;
BA_ "U_T6_MCA_MY2020_Rx" SG_ 746 Con_BTAud_Shuffle_St 1;
BA_ "U_CD542_MY2021_Rx" SG_ 746 Con_BTAud_Shuffle_St 1;
BA_ "U_T6_MCA_MY2020_Tx" SG_ 746 Con_BTAud_Shuffle_St 1;
BA_ "GenSigSendType" SG_ 746 Con_BTAud_Repeat_St 3;
BA_ "U_T6_MCA_MY2020_Rx" SG_ 746 Con_BTAud_Repeat_St 1;
BA_ "U_CD542_MY2021_Rx" SG_ 746 Con_BTAud_Repeat_St 1;
BA_ "U_T6_MCA_MY2020_Tx" SG_ 746 Con_BTAud_Repeat_St 1;
BA_ "GenSigSendType" SG_ 746 Con_BTAud_IntroScan_St 3;
BA_ "U_T6_MCA_MY2020_Rx" SG_ 746 Con_BTAud_IntroScan_St 1;
BA_ "U_CD542_MY2021_Rx" SG_ 746 Con_BTAud_IntroScan_St 1;
BA_ "U_T6_MCA_MY2020_Tx" SG_ 746 Con_BTAud_IntroScan_St 1;
BA_ "GenSigSendType" SG_ 746 Con_BTAud_ActTrNum1_St 3;
BA_ "U_T6_MCA_MY2020_Rx" SG_ 746 Con_BTAud_ActTrNum1_St 1;
BA_ "U_CD542_MY2021_Rx" SG_ 746 Con_BTAud_ActTrNum1_St 1;
BA_ "U_T6_MCA_MY2020_Tx" SG_ 746 Con_BTAud_ActTrNum1_St 1;
BA_ "GenSigSendType" SG_ 746 Con_ShowBTPINNumb_St 3;
BA_ "U_T6_MCA_MY2020_Rx" SG_ 746 Con_ShowBTPINNumb_St 1;
BA_ "U_CD542_MY2021_Rx" SG_ 746 Con_ShowBTPINNumb_St 1;
BA_ "U_T6_MCA_MY2020_Tx" SG_ 746 Con_ShowBTPINNumb_St 1;
BA_ "GenSigSendType" SG_ 746 Con_BTAud_Error_St 3;
BA_ "U_T6_MCA_MY2020_Rx" SG_ 746 Con_BTAud_Error_St 1;
BA_ "U_CD542_MY2021_Rx" SG_ 746 Con_BTAud_Error_St 1;
BA_ "U_T6_MCA_MY2020_Tx" SG_ 746 Con_BTAud_Error_St 1;
BA_ "GenSigSendType" SG_ 746 Con_BTAud_FunctStats_St 3;
BA_ "U_T6_MCA_MY2020_Rx" SG_ 746 Con_BTAud_FunctStats_St 1;
BA_ "U_CD542_MY2021_Rx" SG_ 746 Con_BTAud_FunctStats_St 1;
BA_ "U_T6_MCA_MY2020_Tx" SG_ 746 Con_BTAud_FunctStats_St 1;
BA_ "GenSigSendType" SG_ 746 Con_BTAud_OpMode_St 3;
BA_ "U_T6_MCA_MY2020_Rx" SG_ 746 Con_BTAud_OpMode_St 1;
BA_ "U_CD542_MY2021_Rx" SG_ 746 Con_BTAud_OpMode_St 1;
BA_ "U_T6_MCA_MY2020_Tx" SG_ 746 Con_BTAud_OpMode_St 1;
BA_ "GenSigStartValueInteger" SG_ 479 DISP_SetVolume_Rq 30;
BA_ "GenSigStartValue" SG_ 479 DISP_SetVolume_Rq 30;
BA_ "GenSigSendType" SG_ 479 DISP_SetVolume_Rq 3;
BA_ "U_P702_MY2021_Rx" SG_ 479 DISP_SetVolume_Rq 1;
BA_ "U_T6_MCA_MY2020_Rx" SG_ 479 DISP_SetVolume_Rq 1;
BA_ "U_CD542_MY2021_Rx" SG_ 479 DISP_SetVolume_Rq 1;
BA_ "U_U55X_MY2022_Rx" SG_ 479 DISP_SetVolume_Rq 1;
BA_ "U_CD764_MY2022_Rx" SG_ 479 DISP_SetVolume_Rq 1;
BA_ "U_P702_MY2021_Tx" SG_ 479 DISP_SetVolume_Rq 1;
BA_ "U_T6_MCA_MY2020_Tx" SG_ 479 DISP_SetVolume_Rq 1;
BA_ "U_CD542_MY2021_Tx" SG_ 479 DISP_SetVolume_Rq 1;
BA_ "U_U55X_MY2022_Tx" SG_ 479 DISP_SetVolume_Rq 1;
BA_ "U_CD764_MY2022_Tx" SG_ 479 DISP_SetVolume_Rq 1;
BA_ "GenSigSendType" SG_ 479 DISP_SetVol_Source_Rq 3;
BA_ "U_T6_MCA_MY2020_Rx" SG_ 479 DISP_SetVol_Source_Rq 1;
BA_ "U_CD542_MY2021_Rx" SG_ 479 DISP_SetVol_Source_Rq 1;
BA_ "U_U55X_MY2022_Rx" SG_ 479 DISP_SetVol_Source_Rq 1;
BA_ "U_CD764_MY2022_Rx" SG_ 479 DISP_SetVol_Source_Rq 1;
BA_ "U_P702_MY2021_Rx" SG_ 479 DISP_SetVol_Source_Rq 1;
BA_ "U_P702_MY2021_Tx" SG_ 479 DISP_SetVol_Source_Rq 1;
BA_ "U_T6_MCA_MY2020_Tx" SG_ 479 DISP_SetVol_Source_Rq 1;
BA_ "U_CD542_MY2021_Tx" SG_ 479 DISP_SetVol_Source_Rq 1;
BA_ "U_U55X_MY2022_Tx" SG_ 479 DISP_SetVol_Source_Rq 1;
BA_ "U_CD764_MY2022_Tx" SG_ 479 DISP_SetVol_Source_Rq 1;
BA_ "U_T6_MCA_MY2020_Rx" SG_ 479 DISP_SetVol_Level_Rq 1;
BA_ "U_CD542_MY2021_Rx" SG_ 479 DISP_SetVol_Level_Rq 1;
BA_ "U_U55X_MY2022_Rx" SG_ 479 DISP_SetVol_Level_Rq 1;
BA_ "U_CD764_MY2022_Rx" SG_ 479 DISP_SetVol_Level_Rq 1;
BA_ "U_P702_MY2021_Rx" SG_ 479 DISP_SetVol_Level_Rq 1;
BA_ "U_P702_MY2021_Tx" SG_ 479 DISP_SetVol_Level_Rq 1;
BA_ "U_T6_MCA_MY2020_Tx" SG_ 479 DISP_SetVol_Level_Rq 1;
BA_ "U_CD542_MY2021_Tx" SG_ 479 DISP_SetVol_Level_Rq 1;
BA_ "U_U55X_MY2022_Tx" SG_ 479 DISP_SetVol_Level_Rq 1;
BA_ "U_CD764_MY2022_Tx" SG_ 479 DISP_SetVol_Level_Rq 1;
BA_ "GenSigSendType" SG_ 479 DISP_Setshaker_Rq 3;
BA_ "U_T6_MCA_MY2020_Rx" SG_ 479 DISP_Setshaker_Rq 1;
BA_ "U_P702_MY2021_Rx" SG_ 479 DISP_Setshaker_Rq 1;
BA_ "U_P702_MY2021_Tx" SG_ 479 DISP_Setshaker_Rq 1;
BA_ "U_T6_MCA_MY2020_Tx" SG_ 479 DISP_Setshaker_Rq 1;
BA_ "U_CD542_MY2021_Tx" SG_ 479 DISP_Setshaker_Rq 1;
BA_ "U_U55X_MY2022_Tx" SG_ 479 DISP_Setshaker_Rq 1;
BA_ "U_P702_MY2021_Rx" SG_ 474 Nav_SetCurrStatMCCh_Rq 1;
BA_ "U_T6_MCA_MY2020_Rx" SG_ 474 Nav_SetCurrStatMCCh_Rq 1;
BA_ "U_CD542_MY2021_Rx" SG_ 474 Nav_SetCurrStatMCCh_Rq 1;
BA_ "U_U55X_MY2022_Rx" SG_ 474 Nav_SetCurrStatMCCh_Rq 1;
BA_ "U_P702_MY2021_Tx" SG_ 474 Nav_SetCurrStatMCCh_Rq 1;
BA_ "U_T6_MCA_MY2020_Tx" SG_ 474 Nav_SetCurrStatMCCh_Rq 1;
BA_ "U_CD542_MY2021_Tx" SG_ 474 Nav_SetCurrStatMCCh_Rq 1;
BA_ "U_U55X_MY2022_Tx" SG_ 474 Nav_SetCurrStatMCCh_Rq 1;
BA_ "GenSigSendType" SG_ 474 NAV_SetNEWSMode_Rq 3;
BA_ "U_P702_MY2021_Rx" SG_ 474 NAV_SetNEWSMode_Rq 1;
BA_ "U_T6_MCA_MY2020_Rx" SG_ 474 NAV_SetNEWSMode_Rq 1;
BA_ "U_CD542_MY2021_Rx" SG_ 474 NAV_SetNEWSMode_Rq 1;
BA_ "U_U55X_MY2022_Rx" SG_ 474 NAV_SetNEWSMode_Rq 1;
BA_ "U_P702_MY2021_Tx" SG_ 474 NAV_SetNEWSMode_Rq 1;
BA_ "U_T6_MCA_MY2020_Tx" SG_ 474 NAV_SetNEWSMode_Rq 1;
BA_ "U_CD542_MY2021_Tx" SG_ 474 NAV_SetNEWSMode_Rq 1;
BA_ "U_U55X_MY2022_Tx" SG_ 474 NAV_SetNEWSMode_Rq 1;
BA_ "GenSigStartValue" SG_ 474 NAV_SetMid_Rq 15;
BA_ "GenSigSendType" SG_ 474 NAV_SetMid_Rq 3;
BA_ "U_T6_MCA_MY2020_Rx" SG_ 474 NAV_SetMid_Rq 1;
BA_ "U_CD542_MY2021_Rx" SG_ 474 NAV_SetMid_Rq 1;
BA_ "U_U55X_MY2022_Rx" SG_ 474 NAV_SetMid_Rq 1;
BA_ "U_CD764_MY2022_Rx" SG_ 474 NAV_SetMid_Rq 1;
BA_ "U_P702_MY2021_Rx" SG_ 474 NAV_SetMid_Rq 1;
BA_ "U_P702_MY2021_Tx" SG_ 474 NAV_SetMid_Rq 1;
BA_ "U_T6_MCA_MY2020_Tx" SG_ 474 NAV_SetMid_Rq 1;
BA_ "U_CD542_MY2021_Tx" SG_ 474 NAV_SetMid_Rq 1;
BA_ "U_U55X_MY2022_Tx" SG_ 474 NAV_SetMid_Rq 1;
BA_ "U_CD764_MY2022_Tx" SG_ 474 NAV_SetMid_Rq 1;
BA_ "GenSigSendType" SG_ 474 NAV_SetDSP_Rq 3;
BA_ "U_P702_MY2021_Rx" SG_ 474 NAV_SetDSP_Rq 1;
BA_ "U_T6_MCA_MY2020_Rx" SG_ 474 NAV_SetDSP_Rq 1;
BA_ "U_CD542_MY2021_Rx" SG_ 474 NAV_SetDSP_Rq 1;
BA_ "U_U55X_MY2022_Rx" SG_ 474 NAV_SetDSP_Rq 1;
BA_ "U_P702_MY2021_Tx" SG_ 474 NAV_SetDSP_Rq 1;
BA_ "U_T6_MCA_MY2020_Tx" SG_ 474 NAV_SetDSP_Rq 1;
BA_ "U_CD542_MY2021_Tx" SG_ 474 NAV_SetDSP_Rq 1;
BA_ "U_U55X_MY2022_Tx" SG_ 474 NAV_SetDSP_Rq 1;
BA_ "U_CD764_MY2022_Tx" SG_ 474 NAV_SetDSP_Rq 1;
BA_ "U_P702_MY2021_Rx" SG_ 474 NAV_SetCurrStatFreq_Rq 1;
BA_ "U_T6_MCA_MY2020_Rx" SG_ 474 NAV_SetCurrStatFreq_Rq 1;
BA_ "U_U55X_MY2022_Rx" SG_ 474 NAV_SetCurrStatFreq_Rq 1;
BA_ "U_P702_MY2021_Tx" SG_ 474 NAV_SetCurrStatFreq_Rq 1;
BA_ "U_T6_MCA_MY2020_Tx" SG_ 474 NAV_SetCurrStatFreq_Rq 1;
BA_ "U_CD542_MY2021_Tx" SG_ 474 NAV_SetCurrStatFreq_Rq 1;
BA_ "U_U55X_MY2022_Tx" SG_ 474 NAV_SetCurrStatFreq_Rq 1;
BA_ "GenSigSendType" SG_ 474 NAV_SetCurrentStatOp_Rq 3;
BA_ "U_P702_MY2021_Rx" SG_ 474 NAV_SetCurrentStatOp_Rq 1;
BA_ "U_T6_MCA_MY2020_Rx" SG_ 474 NAV_SetCurrentStatOp_Rq 1;
BA_ "U_CD542_MY2021_Rx" SG_ 474 NAV_SetCurrentStatOp_Rq 1;
BA_ "U_U55X_MY2022_Rx" SG_ 474 NAV_SetCurrentStatOp_Rq 1;
BA_ "U_P702_MY2021_Tx" SG_ 474 NAV_SetCurrentStatOp_Rq 1;
BA_ "U_T6_MCA_MY2020_Tx" SG_ 474 NAV_SetCurrentStatOp_Rq 1;
BA_ "U_CD542_MY2021_Tx" SG_ 474 NAV_SetCurrentStatOp_Rq 1;
BA_ "U_U55X_MY2022_Tx" SG_ 474 NAV_SetCurrentStatOp_Rq 1;
BA_ "U_P702_MY2021_Rx" SG_ 474 NAV_SetCurrentPICode_Rq 1;
BA_ "U_T6_MCA_MY2020_Rx" SG_ 474 NAV_SetCurrentPICode_Rq 1;
BA_ "U_CD542_MY2021_Rx" SG_ 474 NAV_SetCurrentPICode_Rq 1;
BA_ "U_U55X_MY2022_Rx" SG_ 474 NAV_SetCurrentPICode_Rq 1;
BA_ "U_P702_MY2021_Tx" SG_ 474 NAV_SetCurrentPICode_Rq 1;
BA_ "U_T6_MCA_MY2020_Tx" SG_ 474 NAV_SetCurrentPICode_Rq 1;
BA_ "U_CD542_MY2021_Tx" SG_ 474 NAV_SetCurrentPICode_Rq 1;
BA_ "U_U55X_MY2022_Tx" SG_ 474 NAV_SetCurrentPICode_Rq 1;
BA_ "U_T6_MCA_MY2020_Rx" SG_ 474 NAV_ARReqstrSystem_Rq 1;
BA_ "U_CD542_MY2021_Rx" SG_ 474 NAV_ARReqstrSystem_Rq 1;
BA_ "U_CD764_MY2022_Rx" SG_ 474 NAV_ARReqstrSystem_Rq 1;
BA_ "U_P702_MY2021_Rx" SG_ 474 NAV_ARReqstrSystem_Rq 1;
BA_ "U_U55X_MY2022_Rx" SG_ 474 NAV_ARReqstrSystem_Rq 1;
BA_ "U_P702_MY2021_Tx" SG_ 474 NAV_ARReqstrSystem_Rq 1;
BA_ "U_T6_MCA_MY2020_Tx" SG_ 474 NAV_ARReqstrSystem_Rq 1;
BA_ "U_CD542_MY2021_Tx" SG_ 474 NAV_ARReqstrSystem_Rq 1;
BA_ "U_U55X_MY2022_Tx" SG_ 474 NAV_ARReqstrSystem_Rq 1;
BA_ "U_CD764_MY2022_Tx" SG_ 474 NAV_ARReqstrSystem_Rq 1;
BA_ "U_T6_MCA_MY2020_Rx" SG_ 474 NAV_ARReqstrPriority_Rq 1;
BA_ "U_CD542_MY2021_Rx" SG_ 474 NAV_ARReqstrPriority_Rq 1;
BA_ "U_CD764_MY2022_Rx" SG_ 474 NAV_ARReqstrPriority_Rq 1;
BA_ "U_P702_MY2021_Rx" SG_ 474 NAV_ARReqstrPriority_Rq 1;
BA_ "U_U55X_MY2022_Rx" SG_ 474 NAV_ARReqstrPriority_Rq 1;
BA_ "U_P702_MY2021_Tx" SG_ 474 NAV_ARReqstrPriority_Rq 1;
BA_ "U_T6_MCA_MY2020_Tx" SG_ 474 NAV_ARReqstrPriority_Rq 1;
BA_ "U_CD542_MY2021_Tx" SG_ 474 NAV_ARReqstrPriority_Rq 1;
BA_ "U_U55X_MY2022_Tx" SG_ 474 NAV_ARReqstrPriority_Rq 1;
BA_ "U_CD764_MY2022_Tx" SG_ 474 NAV_ARReqstrPriority_Rq 1;
BA_ "GenSigSendType" SG_ 474 NAV_AROperationType_Rq 3;
BA_ "U_T6_MCA_MY2020_Rx" SG_ 474 NAV_AROperationType_Rq 1;
BA_ "U_CD542_MY2021_Rx" SG_ 474 NAV_AROperationType_Rq 1;
BA_ "U_CD764_MY2022_Rx" SG_ 474 NAV_AROperationType_Rq 1;
BA_ "U_P702_MY2021_Rx" SG_ 474 NAV_AROperationType_Rq 1;
BA_ "U_U55X_MY2022_Rx" SG_ 474 NAV_AROperationType_Rq 1;
BA_ "U_P702_MY2021_Tx" SG_ 474 NAV_AROperationType_Rq 1;
BA_ "U_T6_MCA_MY2020_Tx" SG_ 474 NAV_AROperationType_Rq 1;
BA_ "U_CD542_MY2021_Tx" SG_ 474 NAV_AROperationType_Rq 1;
BA_ "U_U55X_MY2022_Tx" SG_ 474 NAV_AROperationType_Rq 1;
BA_ "U_CD764_MY2022_Tx" SG_ 474 NAV_AROperationType_Rq 1;
BA_ "U_T6_MCA_MY2020_Rx" SG_ 474 NAV_ARAudioSource_Rq 1;
BA_ "U_CD542_MY2021_Rx" SG_ 474 NAV_ARAudioSource_Rq 1;
BA_ "U_CD764_MY2022_Rx" SG_ 474 NAV_ARAudioSource_Rq 1;
BA_ "U_P702_MY2021_Rx" SG_ 474 NAV_ARAudioSource_Rq 1;
BA_ "U_U55X_MY2022_Rx" SG_ 474 NAV_ARAudioSource_Rq 1;
BA_ "U_P702_MY2021_Tx" SG_ 474 NAV_ARAudioSource_Rq 1;
BA_ "U_T6_MCA_MY2020_Tx" SG_ 474 NAV_ARAudioSource_Rq 1;
BA_ "U_CD542_MY2021_Tx" SG_ 474 NAV_ARAudioSource_Rq 1;
BA_ "U_U55X_MY2022_Tx" SG_ 474 NAV_ARAudioSource_Rq 1;
BA_ "U_CD764_MY2022_Tx" SG_ 474 NAV_ARAudioSource_Rq 1;
BA_ "GenSigStartValue" SG_ 477 NAV_SetTreble_Rq 15;
BA_ "GenSigSendType" SG_ 477 NAV_SetTreble_Rq 3;
BA_ "U_T6_MCA_MY2020_Rx" SG_ 477 NAV_SetTreble_Rq 1;
BA_ "U_CD542_MY2021_Rx" SG_ 477 NAV_SetTreble_Rq 1;
BA_ "U_U55X_MY2022_Rx" SG_ 477 NAV_SetTreble_Rq 1;
BA_ "U_CD764_MY2022_Rx" SG_ 477 NAV_SetTreble_Rq 1;
BA_ "U_T6_MCA_MY2020_Tx" SG_ 477 NAV_SetTreble_Rq 1;
BA_ "U_CD542_MY2021_Tx" SG_ 477 NAV_SetTreble_Rq 1;
BA_ "U_U55X_MY2022_Tx" SG_ 477 NAV_SetTreble_Rq 1;
BA_ "U_CD764_MY2022_Tx" SG_ 477 NAV_SetTreble_Rq 1;
BA_ "GenSigStartValue" SG_ 477 NAV_SetFader_Rq 15;
BA_ "GenSigSendType" SG_ 477 NAV_SetFader_Rq 3;
BA_ "U_T6_MCA_MY2020_Rx" SG_ 477 NAV_SetFader_Rq 1;
BA_ "U_CD542_MY2021_Rx" SG_ 477 NAV_SetFader_Rq 1;
BA_ "U_U55X_MY2022_Rx" SG_ 477 NAV_SetFader_Rq 1;
BA_ "U_CD764_MY2022_Rx" SG_ 477 NAV_SetFader_Rq 1;
BA_ "U_T6_MCA_MY2020_Tx" SG_ 477 NAV_SetFader_Rq 1;
BA_ "U_CD542_MY2021_Tx" SG_ 477 NAV_SetFader_Rq 1;
BA_ "U_U55X_MY2022_Tx" SG_ 477 NAV_SetFader_Rq 1;
BA_ "U_CD764_MY2022_Tx" SG_ 477 NAV_SetFader_Rq 1;
BA_ "GenSigStartValue" SG_ 477 NAV_SetBass_Rq 15;
BA_ "GenSigSendType" SG_ 477 NAV_SetBass_Rq 3;
BA_ "U_T6_MCA_MY2020_Rx" SG_ 477 NAV_SetBass_Rq 1;
BA_ "U_CD542_MY2021_Rx" SG_ 477 NAV_SetBass_Rq 1;
BA_ "U_U55X_MY2022_Rx" SG_ 477 NAV_SetBass_Rq 1;
BA_ "U_CD764_MY2022_Rx" SG_ 477 NAV_SetBass_Rq 1;
BA_ "U_T6_MCA_MY2020_Tx" SG_ 477 NAV_SetBass_Rq 1;
BA_ "U_CD542_MY2021_Tx" SG_ 477 NAV_SetBass_Rq 1;
BA_ "U_U55X_MY2022_Tx" SG_ 477 NAV_SetBass_Rq 1;
BA_ "U_CD764_MY2022_Tx" SG_ 477 NAV_SetBass_Rq 1;
BA_ "GenSigStartValue" SG_ 477 NAV_SetBalance_Rq 15;
BA_ "GenSigSendType" SG_ 477 NAV_SetBalance_Rq 3;
BA_ "U_T6_MCA_MY2020_Rx" SG_ 477 NAV_SetBalance_Rq 1;
BA_ "U_CD542_MY2021_Rx" SG_ 477 NAV_SetBalance_Rq 1;
BA_ "U_U55X_MY2022_Rx" SG_ 477 NAV_SetBalance_Rq 1;
BA_ "U_CD764_MY2022_Rx" SG_ 477 NAV_SetBalance_Rq 1;
BA_ "U_T6_MCA_MY2020_Tx" SG_ 477 NAV_SetBalance_Rq 1;
BA_ "U_CD542_MY2021_Tx" SG_ 477 NAV_SetBalance_Rq 1;
BA_ "U_U55X_MY2022_Tx" SG_ 477 NAV_SetBalance_Rq 1;
BA_ "U_CD764_MY2022_Tx" SG_ 477 NAV_SetBalance_Rq 1;
BA_ "GenSigStartValue" SG_ 477 NAV_SetAVC_Rq 15;
BA_ "GenSigSendType" SG_ 477 NAV_SetAVC_Rq 3;
BA_ "U_T6_MCA_MY2020_Rx" SG_ 477 NAV_SetAVC_Rq 1;
BA_ "U_CD542_MY2021_Rx" SG_ 477 NAV_SetAVC_Rq 1;
BA_ "U_U55X_MY2022_Rx" SG_ 477 NAV_SetAVC_Rq 1;
BA_ "U_CD764_MY2022_Rx" SG_ 477 NAV_SetAVC_Rq 1;
BA_ "U_T6_MCA_MY2020_Tx" SG_ 477 NAV_SetAVC_Rq 1;
BA_ "U_CD542_MY2021_Tx" SG_ 477 NAV_SetAVC_Rq 1;
BA_ "U_U55X_MY2022_Tx" SG_ 477 NAV_SetAVC_Rq 1;
BA_ "U_CD764_MY2022_Tx" SG_ 477 NAV_SetAVC_Rq 1;
BA_ "GenSigSendType" SG_ 477 NAV_SecurtyPINUnlock_Rq 3;
BA_ "U_T6_MCA_MY2020_Rx" SG_ 477 NAV_SecurtyPINUnlock_Rq 1;
BA_ "U_U55X_MY2022_Rx" SG_ 477 NAV_SecurtyPINUnlock_Rq 1;
BA_ "U_T6_MCA_MY2020_Tx" SG_ 477 NAV_SecurtyPINUnlock_Rq 1;
BA_ "U_CD542_MY2021_Tx" SG_ 477 NAV_SecurtyPINUnlock_Rq 1;
BA_ "U_U55X_MY2022_Tx" SG_ 477 NAV_SecurtyPINUnlock_Rq 1;
BA_ "GenSigSendType" SG_ 477 NAV_LoadEjectMode_Rq 3;
BA_ "U_T6_MCA_MY2020_Rx" SG_ 477 NAV_LoadEjectMode_Rq 1;
BA_ "U_CD542_MY2021_Rx" SG_ 477 NAV_LoadEjectMode_Rq 1;
BA_ "U_U55X_MY2022_Rx" SG_ 477 NAV_LoadEjectMode_Rq 1;
BA_ "U_T6_MCA_MY2020_Tx" SG_ 477 NAV_LoadEjectMode_Rq 1;
BA_ "U_CD542_MY2021_Tx" SG_ 477 NAV_LoadEjectMode_Rq 1;
BA_ "U_U55X_MY2022_Tx" SG_ 477 NAV_LoadEjectMode_Rq 1;
BA_ "U_T6_MCA_MY2020_Rx" SG_ 477 NAV_LoadEjectDisc_Rq 1;
BA_ "U_CD542_MY2021_Rx" SG_ 477 NAV_LoadEjectDisc_Rq 1;
BA_ "U_U55X_MY2022_Rx" SG_ 477 NAV_LoadEjectDisc_Rq 1;
BA_ "U_T6_MCA_MY2020_Tx" SG_ 477 NAV_LoadEjectDisc_Rq 1;
BA_ "U_CD542_MY2021_Tx" SG_ 477 NAV_LoadEjectDisc_Rq 1;
BA_ "U_U55X_MY2022_Tx" SG_ 477 NAV_LoadEjectDisc_Rq 1;
BA_ "GenSigSendType" SG_ 260 MFD_SDARS_SetOpMode_Rq 3;
BA_ "U_P702_MY2021_Rx" SG_ 260 MFD_SDARS_SetOpMode_Rq 1;
BA_ "U_T6_MCA_MY2020_Rx" SG_ 260 MFD_SDARS_SetOpMode_Rq 1;
BA_ "U_CD542_MY2021_Rx" SG_ 260 MFD_SDARS_SetOpMode_Rq 1;
BA_ "U_P702_MY2021_Tx" SG_ 260 MFD_SDARS_SetOpMode_Rq 1;
BA_ "U_T6_MCA_MY2020_Tx" SG_ 260 MFD_SDARS_SetOpMode_Rq 1;
BA_ "U_CD542_MY2021_Tx" SG_ 260 MFD_SDARS_SetOpMode_Rq 1;
BA_ "U_U55X_MY2022_Tx" SG_ 260 MFD_SDARS_SetOpMode_Rq 1;
BA_ "GenSigStartValueInteger" SG_ 260 MFD_SDARS_DirectTune_Rq 255;
BA_ "ContentDependant" SG_ 260 MFD_SDARS_DirectTune_Rq 1;
BA_ "GenSigStartValue" SG_ 260 MFD_SDARS_DirectTune_Rq 255;
BA_ "GenSigSendType" SG_ 260 MFD_SDARS_DirectTune_Rq 3;
BA_ "U_P702_MY2021_Rx" SG_ 260 MFD_SDARS_DirectTune_Rq 1;
BA_ "U_T6_MCA_MY2020_Rx" SG_ 260 MFD_SDARS_DirectTune_Rq 1;
BA_ "U_CD542_MY2021_Rx" SG_ 260 MFD_SDARS_DirectTune_Rq 1;
BA_ "U_P702_MY2021_Tx" SG_ 260 MFD_SDARS_DirectTune_Rq 1;
BA_ "U_T6_MCA_MY2020_Tx" SG_ 260 MFD_SDARS_DirectTune_Rq 1;
BA_ "U_CD542_MY2021_Tx" SG_ 260 MFD_SDARS_DirectTune_Rq 1;
BA_ "U_U55X_MY2022_Tx" SG_ 260 MFD_SDARS_DirectTune_Rq 1;
BA_ "GenSigSendType" SG_ 260 SDARS_GetESN_Rq 3;
BA_ "U_P702_MY2021_Rx" SG_ 260 SDARS_GetESN_Rq 1;
BA_ "U_T6_MCA_MY2020_Rx" SG_ 260 SDARS_GetESN_Rq 1;
BA_ "U_CD542_MY2021_Rx" SG_ 260 SDARS_GetESN_Rq 1;
BA_ "U_P702_MY2021_Tx" SG_ 260 SDARS_GetESN_Rq 1;
BA_ "U_T6_MCA_MY2020_Tx" SG_ 260 SDARS_GetESN_Rq 1;
BA_ "U_CD542_MY2021_Tx" SG_ 260 SDARS_GetESN_Rq 1;
BA_ "U_U55X_MY2022_Tx" SG_ 260 SDARS_GetESN_Rq 1;
BA_ "GenSigSendType" SG_ 260 SDARS_SRReplay_Rq 3;
BA_ "U_P702_MY2021_Rx" SG_ 260 SDARS_SRReplay_Rq 1;
BA_ "U_T6_MCA_MY2020_Rx" SG_ 260 SDARS_SRReplay_Rq 1;
BA_ "U_CD542_MY2021_Rx" SG_ 260 SDARS_SRReplay_Rq 1;
BA_ "U_P702_MY2021_Tx" SG_ 260 SDARS_SRReplay_Rq 1;
BA_ "U_T6_MCA_MY2020_Tx" SG_ 260 SDARS_SRReplay_Rq 1;
BA_ "U_CD542_MY2021_Tx" SG_ 260 SDARS_SRReplay_Rq 1;
BA_ "U_U55X_MY2022_Tx" SG_ 260 SDARS_SRReplay_Rq 1;
BA_ "GenSigSendType" SG_ 260 SDARS_SelectCategory_Rq 3;
BA_ "U_P702_MY2021_Rx" SG_ 260 SDARS_SelectCategory_Rq 1;
BA_ "U_T6_MCA_MY2020_Rx" SG_ 260 SDARS_SelectCategory_Rq 1;
BA_ "U_CD542_MY2021_Rx" SG_ 260 SDARS_SelectCategory_Rq 1;
BA_ "U_P702_MY2021_Tx" SG_ 260 SDARS_SelectCategory_Rq 1;
BA_ "U_T6_MCA_MY2020_Tx" SG_ 260 SDARS_SelectCategory_Rq 1;
BA_ "U_CD542_MY2021_Tx" SG_ 260 SDARS_SelectCategory_Rq 1;
BA_ "U_U55X_MY2022_Tx" SG_ 260 SDARS_SelectCategory_Rq 1;
BA_ "GenSigSendType" SG_ 260 SDARS_InfoRefChanNum_Rq 3;
BA_ "U_P702_MY2021_Rx" SG_ 260 SDARS_InfoRefChanNum_Rq 1;
BA_ "U_T6_MCA_MY2020_Rx" SG_ 260 SDARS_InfoRefChanNum_Rq 1;
BA_ "U_CD542_MY2021_Rx" SG_ 260 SDARS_InfoRefChanNum_Rq 1;
BA_ "U_P702_MY2021_Tx" SG_ 260 SDARS_InfoRefChanNum_Rq 1;
BA_ "U_T6_MCA_MY2020_Tx" SG_ 260 SDARS_InfoRefChanNum_Rq 1;
BA_ "U_CD542_MY2021_Tx" SG_ 260 SDARS_InfoRefChanNum_Rq 1;
BA_ "U_U55X_MY2022_Tx" SG_ 260 SDARS_InfoRefChanNum_Rq 1;
BA_ "GenSigSendType" SG_ 260 SDARS_FactoryReset_Rq 3;
BA_ "U_CD542_MY2021_Rx" SG_ 260 SDARS_FactoryReset_Rq 1;
BA_ "U_U55X_MY2022_Rx" SG_ 260 SDARS_FactoryReset_Rq 1;
BA_ "U_CD764_MY2022_Rx" SG_ 260 SDARS_FactoryReset_Rq 1;
BA_ "U_P702_MY2021_Rx" SG_ 260 SDARS_FactoryReset_Rq 1;
BA_ "U_T6_MCA_MY2020_Rx" SG_ 260 SDARS_FactoryReset_Rq 1;
BA_ "U_P702_MY2021_Tx" SG_ 260 SDARS_FactoryReset_Rq 1;
BA_ "U_T6_MCA_MY2020_Tx" SG_ 260 SDARS_FactoryReset_Rq 1;
BA_ "U_CD542_MY2021_Tx" SG_ 260 SDARS_FactoryReset_Rq 1;
BA_ "U_U55X_MY2022_Tx" SG_ 260 SDARS_FactoryReset_Rq 1;
BA_ "U_CD764_MY2022_Tx" SG_ 260 SDARS_FactoryReset_Rq 1;
BA_ "GenSigStartValueInteger" SG_ 476 Nav_SetAudioMixRatio_Rq 31;
BA_ "GenSigStartValue" SG_ 476 Nav_SetAudioMixRatio_Rq 31;
BA_ "GenSigSendType" SG_ 476 Nav_SetAudioMixRatio_Rq 3;
BA_ "U_P702_MY2021_Rx" SG_ 476 Nav_SetAudioMixRatio_Rq 1;
BA_ "U_T6_MCA_MY2020_Rx" SG_ 476 Nav_SetAudioMixRatio_Rq 1;
BA_ "U_CD542_MY2021_Rx" SG_ 476 Nav_SetAudioMixRatio_Rq 1;
BA_ "U_P702_MY2021_Tx" SG_ 476 Nav_SetAudioMixRatio_Rq 1;
BA_ "U_T6_MCA_MY2020_Tx" SG_ 476 Nav_SetAudioMixRatio_Rq 1;
BA_ "U_CD542_MY2021_Tx" SG_ 476 Nav_SetAudioMixRatio_Rq 1;
BA_ "U_U55X_MY2022_Tx" SG_ 476 Nav_SetAudioMixRatio_Rq 1;
BA_ "GenSigSendType" SG_ 476 NAV_SkipCatalouge_Rq 3;
BA_ "U_P702_MY2021_Rx" SG_ 476 NAV_SkipCatalouge_Rq 1;
BA_ "U_T6_MCA_MY2020_Rx" SG_ 476 NAV_SkipCatalouge_Rq 1;
BA_ "U_CD542_MY2021_Rx" SG_ 476 NAV_SkipCatalouge_Rq 1;
BA_ "U_P702_MY2021_Tx" SG_ 476 NAV_SkipCatalouge_Rq 1;
BA_ "U_T6_MCA_MY2020_Tx" SG_ 476 NAV_SkipCatalouge_Rq 1;
BA_ "U_CD542_MY2021_Tx" SG_ 476 NAV_SkipCatalouge_Rq 1;
BA_ "U_U55X_MY2022_Tx" SG_ 476 NAV_SkipCatalouge_Rq 1;
BA_ "GenSigSendType" SG_ 476 NAV_SetOperationMode_Rq 3;
BA_ "U_P702_MY2021_Rx" SG_ 476 NAV_SetOperationMode_Rq 1;
BA_ "U_T6_MCA_MY2020_Rx" SG_ 476 NAV_SetOperationMode_Rq 1;
BA_ "U_CD542_MY2021_Rx" SG_ 476 NAV_SetOperationMode_Rq 1;
BA_ "U_P702_MY2021_Tx" SG_ 476 NAV_SetOperationMode_Rq 1;
BA_ "U_T6_MCA_MY2020_Tx" SG_ 476 NAV_SetOperationMode_Rq 1;
BA_ "U_CD542_MY2021_Tx" SG_ 476 NAV_SetOperationMode_Rq 1;
BA_ "U_U55X_MY2022_Tx" SG_ 476 NAV_SetOperationMode_Rq 1;
BA_ "GenSigSendType" SG_ 476 NAV_SetDSPProgram_Rq 3;
BA_ "U_P702_MY2021_Rx" SG_ 476 NAV_SetDSPProgram_Rq 1;
BA_ "U_T6_MCA_MY2020_Rx" SG_ 476 NAV_SetDSPProgram_Rq 1;
BA_ "U_CD542_MY2021_Rx" SG_ 476 NAV_SetDSPProgram_Rq 1;
BA_ "U_P702_MY2021_Tx" SG_ 476 NAV_SetDSPProgram_Rq 1;
BA_ "U_T6_MCA_MY2020_Tx" SG_ 476 NAV_SetDSPProgram_Rq 1;
BA_ "U_CD542_MY2021_Tx" SG_ 476 NAV_SetDSPProgram_Rq 1;
BA_ "U_U55X_MY2022_Tx" SG_ 476 NAV_SetDSPProgram_Rq 1;
BA_ "GenSigSendType" SG_ 490 HMI_SetCompression_Rq 3;
BA_ "U_P702_MY2021_Rx" SG_ 490 HMI_SetCompression_Rq 1;
BA_ "U_T6_MCA_MY2020_Rx" SG_ 490 HMI_SetCompression_Rq 1;
BA_ "U_P702_MY2021_Tx" SG_ 490 HMI_SetCompression_Rq 1;
BA_ "U_T6_MCA_MY2020_Tx" SG_ 490 HMI_SetCompression_Rq 1;
BA_ "U_CD542_MY2021_Tx" SG_ 490 HMI_SetCompression_Rq 1;
BA_ "U_U55X_MY2022_Tx" SG_ 490 HMI_SetCompression_Rq 1;
BA_ "GenSigSendType" SG_ 490 HMI_SkipTrack_Rq 3;
BA_ "U_P702_MY2021_Rx" SG_ 490 HMI_SkipTrack_Rq 1;
BA_ "U_T6_MCA_MY2020_Rx" SG_ 490 HMI_SkipTrack_Rq 1;
BA_ "U_CD542_MY2021_Rx" SG_ 490 HMI_SkipTrack_Rq 1;
BA_ "U_P702_MY2021_Tx" SG_ 490 HMI_SkipTrack_Rq 1;
BA_ "U_T6_MCA_MY2020_Tx" SG_ 490 HMI_SkipTrack_Rq 1;
BA_ "U_CD542_MY2021_Tx" SG_ 490 HMI_SkipTrack_Rq 1;
BA_ "U_U55X_MY2022_Tx" SG_ 490 HMI_SkipTrack_Rq 1;
BA_ "GenSigSendType" SG_ 1923 TesterPhysicalReqDSP 3;
BA_ "U_P702_MY2021_Rx" SG_ 1923 TesterPhysicalReqDSP 1;
BA_ "U_T6_MCA_MY2020_Rx" SG_ 1923 TesterPhysicalReqDSP 1;
BA_ "U_CD542_MY2021_Rx" SG_ 1923 TesterPhysicalReqDSP 1;
BA_ "U_U55X_MY2022_Rx" SG_ 1923 TesterPhysicalReqDSP 1;
BA_ "U_CD764_MY2022_Rx" SG_ 1923 TesterPhysicalReqDSP 1;
BA_ "GenSigSendType" SG_ 1931 TesterPhysicalResDSP 3;
BA_ "U_T6_MCA_MY2020_Tx" SG_ 1931 TesterPhysicalResDSP 1;
BA_ "U_CD542_MY2021_Tx" SG_ 1931 TesterPhysicalResDSP 1;
BA_ "U_U55X_MY2022_Tx" SG_ 1931 TesterPhysicalResDSP 1;
BA_ "U_CD764_MY2022_Tx" SG_ 1931 TesterPhysicalResDSP 1;
BA_ "GenSigStartValueInteger" SG_ 1478 DSP_GWOnBoardTester 255;
BA_ "ContentDependant" SG_ 1478 DSP_GWOnBoardTester 1;
BA_ "GenSigStartValue" SG_ 1478 DSP_GWOnBoardTester 255;
BA_ "U_T6_MCA_MY2020_Rx" SG_ 1478 DSP_GWOnBoardTester 1;
BA_ "U_U55X_MY2022_Rx" SG_ 1478 DSP_GWOnBoardTester 1;
BA_ "U_CD764_MY2022_Rx" SG_ 1478 DSP_GWOnBoardTester 1;
BA_ "U_T6_MCA_MY2020_Tx" SG_ 1478 DSP_GWOnBoardTester 1;
BA_ "U_CD542_MY2021_Tx" SG_ 1478 DSP_GWOnBoardTester 1;
BA_ "U_U55X_MY2022_Tx" SG_ 1478 DSP_GWOnBoardTester 1;
BA_ "U_CD764_MY2022_Tx" SG_ 1478 DSP_GWOnBoardTester 1;
BA_ "GenSigStartValueInteger" SG_ 1478 DSP_GWNMProxy 255;
BA_ "ContentDependant" SG_ 1478 DSP_GWNMProxy 1;
BA_ "GenSigStartValue" SG_ 1478 DSP_GWNMProxy 255;
BA_ "U_T6_MCA_MY2020_Rx" SG_ 1478 DSP_GWNMProxy 1;
BA_ "U_U55X_MY2022_Rx" SG_ 1478 DSP_GWNMProxy 1;
BA_ "U_CD764_MY2022_Rx" SG_ 1478 DSP_GWNMProxy 1;
BA_ "U_T6_MCA_MY2020_Tx" SG_ 1478 DSP_GWNMProxy 1;
BA_ "U_CD542_MY2021_Tx" SG_ 1478 DSP_GWNMProxy 1;
BA_ "U_U55X_MY2022_Tx" SG_ 1478 DSP_GWNMProxy 1;
BA_ "U_CD764_MY2022_Tx" SG_ 1478 DSP_GWNMProxy 1;
BA_ "GenSigStartValueInteger" SG_ 1478 DSP_AutoSarNMReserved4 255;
BA_ "ContentDependant" SG_ 1478 DSP_AutoSarNMReserved4 1;
BA_ "GenSigStartValue" SG_ 1478 DSP_AutoSarNMReserved4 255;
BA_ "U_T6_MCA_MY2020_Rx" SG_ 1478 DSP_AutoSarNMReserved4 1;
BA_ "U_U55X_MY2022_Rx" SG_ 1478 DSP_AutoSarNMReserved4 1;
BA_ "U_CD764_MY2022_Rx" SG_ 1478 DSP_AutoSarNMReserved4 1;
BA_ "U_T6_MCA_MY2020_Tx" SG_ 1478 DSP_AutoSarNMReserved4 1;
BA_ "U_CD542_MY2021_Tx" SG_ 1478 DSP_AutoSarNMReserved4 1;
BA_ "U_U55X_MY2022_Tx" SG_ 1478 DSP_AutoSarNMReserved4 1;
BA_ "U_CD764_MY2022_Tx" SG_ 1478 DSP_AutoSarNMReserved4 1;
BA_ "GenSigStartValueInteger" SG_ 1478 DSP_AutoSarNMReserved3 255;
BA_ "ContentDependant" SG_ 1478 DSP_AutoSarNMReserved3 1;
BA_ "GenSigStartValue" SG_ 1478 DSP_AutoSarNMReserved3 255;
BA_ "U_T6_MCA_MY2020_Rx" SG_ 1478 DSP_AutoSarNMReserved3 1;
BA_ "U_U55X_MY2022_Rx" SG_ 1478 DSP_AutoSarNMReserved3 1;
BA_ "U_CD764_MY2022_Rx" SG_ 1478 DSP_AutoSarNMReserved3 1;
BA_ "U_T6_MCA_MY2020_Tx" SG_ 1478 DSP_AutoSarNMReserved3 1;
BA_ "U_CD542_MY2021_Tx" SG_ 1478 DSP_AutoSarNMReserved3 1;
BA_ "U_U55X_MY2022_Tx" SG_ 1478 DSP_AutoSarNMReserved3 1;
BA_ "U_CD764_MY2022_Tx" SG_ 1478 DSP_AutoSarNMReserved3 1;
BA_ "GenSigStartValueInteger" SG_ 1478 DSP_AutoSarNMReserved2 255;
BA_ "ContentDependant" SG_ 1478 DSP_AutoSarNMReserved2 1;
BA_ "GenSigStartValue" SG_ 1478 DSP_AutoSarNMReserved2 255;
BA_ "U_T6_MCA_MY2020_Rx" SG_ 1478 DSP_AutoSarNMReserved2 1;
BA_ "U_U55X_MY2022_Rx" SG_ 1478 DSP_AutoSarNMReserved2 1;
BA_ "U_CD764_MY2022_Rx" SG_ 1478 DSP_AutoSarNMReserved2 1;
BA_ "U_T6_MCA_MY2020_Tx" SG_ 1478 DSP_AutoSarNMReserved2 1;
BA_ "U_CD542_MY2021_Tx" SG_ 1478 DSP_AutoSarNMReserved2 1;
BA_ "U_U55X_MY2022_Tx" SG_ 1478 DSP_AutoSarNMReserved2 1;
BA_ "U_CD764_MY2022_Tx" SG_ 1478 DSP_AutoSarNMReserved2 1;
BA_ "GenSigStartValueInteger" SG_ 1478 DSP_AutoSarNMReserved1 255;
BA_ "ContentDependant" SG_ 1478 DSP_AutoSarNMReserved1 1;
BA_ "GenSigStartValue" SG_ 1478 DSP_AutoSarNMReserved1 255;
BA_ "U_T6_MCA_MY2020_Rx" SG_ 1478 DSP_AutoSarNMReserved1 1;
BA_ "U_U55X_MY2022_Rx" SG_ 1478 DSP_AutoSarNMReserved1 1;
BA_ "U_CD764_MY2022_Rx" SG_ 1478 DSP_AutoSarNMReserved1 1;
BA_ "U_T6_MCA_MY2020_Tx" SG_ 1478 DSP_AutoSarNMReserved1 1;
BA_ "U_CD542_MY2021_Tx" SG_ 1478 DSP_AutoSarNMReserved1 1;
BA_ "U_U55X_MY2022_Tx" SG_ 1478 DSP_AutoSarNMReserved1 1;
BA_ "U_CD764_MY2022_Tx" SG_ 1478 DSP_AutoSarNMReserved1 1;
BA_ "GenSigStartValueInteger" SG_ 1478 DSP_AutoSarNMNodeId 198;
BA_ "ContentDependant" SG_ 1478 DSP_AutoSarNMNodeId 1;
BA_ "GenSigStartValue" SG_ 1478 DSP_AutoSarNMNodeId 198;
BA_ "U_T6_MCA_MY2020_Rx" SG_ 1478 DSP_AutoSarNMNodeId 1;
BA_ "U_U55X_MY2022_Rx" SG_ 1478 DSP_AutoSarNMNodeId 1;
BA_ "U_CD764_MY2022_Rx" SG_ 1478 DSP_AutoSarNMNodeId 1;
BA_ "U_T6_MCA_MY2020_Tx" SG_ 1478 DSP_AutoSarNMNodeId 1;
BA_ "U_CD542_MY2021_Tx" SG_ 1478 DSP_AutoSarNMNodeId 1;
BA_ "U_U55X_MY2022_Tx" SG_ 1478 DSP_AutoSarNMNodeId 1;
BA_ "U_CD764_MY2022_Tx" SG_ 1478 DSP_AutoSarNMNodeId 1;
BA_ "ContentDependant" SG_ 1478 DSP_AutoSarNMControl 1;
BA_ "U_T6_MCA_MY2020_Rx" SG_ 1478 DSP_AutoSarNMControl 1;
BA_ "U_U55X_MY2022_Rx" SG_ 1478 DSP_AutoSarNMControl 1;
BA_ "U_CD764_MY2022_Rx" SG_ 1478 DSP_AutoSarNMControl 1;
BA_ "U_T6_MCA_MY2020_Tx" SG_ 1478 DSP_AutoSarNMControl 1;
BA_ "U_CD542_MY2021_Tx" SG_ 1478 DSP_AutoSarNMControl 1;
BA_ "U_U55X_MY2022_Tx" SG_ 1478 DSP_AutoSarNMControl 1;
BA_ "U_CD764_MY2022_Tx" SG_ 1478 DSP_AutoSarNMControl 1;
BA_ "GenSigSendType" SG_ 1245 RearDiffLckLamp_D_Cstm 3;
BA_ "ECGUsedTxSignal" SG_ 1245 RearDiffLckLamp_D_Cstm 1;
BA_ "U_CD764_MY2022_Tx" SG_ 1245 RearDiffLckLamp_D_Cstm 1;
BA_ "GenSigSendType" SG_ 1245 FrontDiffLckLamp_D_Cstm 3;
BA_ "ECGUsedTxSignal" SG_ 1245 FrontDiffLckLamp_D_Cstm 1;
BA_ "U_CD764_MY2022_Tx" SG_ 1245 FrontDiffLckLamp_D_Cstm 1;
BA_ "GenSigStartValueInteger" SG_ 1245 AwdMdeCstm_D_RqDrv 5;
BA_ "GenSigSendType" SG_ 1245 AwdMdeCstm_D_RqDrv 3;
BA_ "ECGUsedTxSignal" SG_ 1245 AwdMdeCstm_D_RqDrv 1;
BA_ "U_CD764_MY2022_Tx" SG_ 1245 AwdMdeCstm_D_RqDrv 1;
BA_ "GenSigStartValueInteger" SG_ 1245 SelDrvMdeAwd2_D_Cstm 31;
BA_ "GenSigStartValue" SG_ 1245 SelDrvMdeAwd2_D_Cstm 31;
BA_ "GenSigSendType" SG_ 1245 SelDrvMdeAwd2_D_Cstm 3;
BA_ "ECGUsedTxSignal" SG_ 1245 SelDrvMdeAwd2_D_Cstm 1;
BA_ "U_CD764_MY2022_Tx" SG_ 1245 SelDrvMdeAwd2_D_Cstm 1;
BA_ "GenSigSendType" SG_ 1242 EngExhMdeQuietCstm_D_Rq 3;
BA_ "ECGUsedTxSignal" SG_ 1242 EngExhMdeQuietCstm_D_Rq 1;
BA_ "U_CD764_MY2022_Tx" SG_ 1242 EngExhMdeQuietCstm_D_Rq 1;
BA_ "GenSigSendType" SG_ 1242 StopStrtCstm_D_Rq 3;
BA_ "ECGUsedTxSignal" SG_ 1242 StopStrtCstm_D_Rq 1;
BA_ "U_CD764_MY2022_Tx" SG_ 1242 StopStrtCstm_D_Rq 1;
BA_ "GenSigSendType" SG_ 1242 SelDrvMdeCstmPt_D_Rq 3;
BA_ "ECGUsedTxSignal" SG_ 1242 SelDrvMdeCstmPt_D_Rq 1;
BA_ "U_CD764_MY2022_Tx" SG_ 1242 SelDrvMdeCstmPt_D_Rq 1;
BA_ "U_P702_MY2021_Rx" SG_ 502 Dsp_StartItemIndexRq 1;
BA_ "U_T6_MCA_MY2020_Rx" SG_ 502 Dsp_StartItemIndexRq 1;
BA_ "U_CD542_MY2021_Rx" SG_ 502 Dsp_StartItemIndexRq 1;
BA_ "U_U55X_MY2022_Rx" SG_ 502 Dsp_StartItemIndexRq 1;
BA_ "U_P702_MY2021_Tx" SG_ 502 Dsp_StartItemIndexRq 1;
BA_ "U_T6_MCA_MY2020_Tx" SG_ 502 Dsp_StartItemIndexRq 1;
BA_ "U_CD542_MY2021_Tx" SG_ 502 Dsp_StartItemIndexRq 1;
BA_ "U_U55X_MY2022_Tx" SG_ 502 Dsp_StartItemIndexRq 1;
BA_ "U_P702_MY2021_Rx" SG_ 502 Dsp_NbrOfItems2_Rq 1;
BA_ "U_T6_MCA_MY2020_Rx" SG_ 502 Dsp_NbrOfItems2_Rq 1;
BA_ "U_CD542_MY2021_Rx" SG_ 502 Dsp_NbrOfItems2_Rq 1;
BA_ "U_U55X_MY2022_Rx" SG_ 502 Dsp_NbrOfItems2_Rq 1;
BA_ "U_P702_MY2021_Tx" SG_ 502 Dsp_NbrOfItems2_Rq 1;
BA_ "U_T6_MCA_MY2020_Tx" SG_ 502 Dsp_NbrOfItems2_Rq 1;
BA_ "U_CD542_MY2021_Tx" SG_ 502 Dsp_NbrOfItems2_Rq 1;
BA_ "U_U55X_MY2022_Tx" SG_ 502 Dsp_NbrOfItems2_Rq 1;
BA_ "U_P702_MY2021_Rx" SG_ 502 Dsp_ItemNameLength2_Rq 1;
BA_ "U_T6_MCA_MY2020_Rx" SG_ 502 Dsp_ItemNameLength2_Rq 1;
BA_ "U_CD542_MY2021_Rx" SG_ 502 Dsp_ItemNameLength2_Rq 1;
BA_ "U_U55X_MY2022_Rx" SG_ 502 Dsp_ItemNameLength2_Rq 1;
BA_ "U_P702_MY2021_Tx" SG_ 502 Dsp_ItemNameLength2_Rq 1;
BA_ "U_T6_MCA_MY2020_Tx" SG_ 502 Dsp_ItemNameLength2_Rq 1;
BA_ "U_CD542_MY2021_Tx" SG_ 502 Dsp_ItemNameLength2_Rq 1;
BA_ "U_U55X_MY2022_Tx" SG_ 502 Dsp_ItemNameLength2_Rq 1;
BA_ "U_P702_MY2021_Rx" SG_ 502 Dsp_FolderNumber2_Rq 1;
BA_ "U_T6_MCA_MY2020_Rx" SG_ 502 Dsp_FolderNumber2_Rq 1;
BA_ "U_CD542_MY2021_Rx" SG_ 502 Dsp_FolderNumber2_Rq 1;
BA_ "U_U55X_MY2022_Rx" SG_ 502 Dsp_FolderNumber2_Rq 1;
BA_ "U_P702_MY2021_Tx" SG_ 502 Dsp_FolderNumber2_Rq 1;
BA_ "U_T6_MCA_MY2020_Tx" SG_ 502 Dsp_FolderNumber2_Rq 1;
BA_ "U_CD542_MY2021_Tx" SG_ 502 Dsp_FolderNumber2_Rq 1;
BA_ "U_U55X_MY2022_Tx" SG_ 502 Dsp_FolderNumber2_Rq 1;
BA_ "U_P702_MY2021_Rx" SG_ 502 Dsp_FolderContent_Rq 1;
BA_ "U_T6_MCA_MY2020_Rx" SG_ 502 Dsp_FolderContent_Rq 1;
BA_ "U_CD542_MY2021_Rx" SG_ 502 Dsp_FolderContent_Rq 1;
BA_ "U_U55X_MY2022_Rx" SG_ 502 Dsp_FolderContent_Rq 1;
BA_ "U_P702_MY2021_Tx" SG_ 502 Dsp_FolderContent_Rq 1;
BA_ "U_T6_MCA_MY2020_Tx" SG_ 502 Dsp_FolderContent_Rq 1;
BA_ "U_CD542_MY2021_Tx" SG_ 502 Dsp_FolderContent_Rq 1;
BA_ "U_U55X_MY2022_Tx" SG_ 502 Dsp_FolderContent_Rq 1;
BA_ "U_P702_MY2021_Rx" SG_ 502 Dsp_CutItem2_Rq 1;
BA_ "U_T6_MCA_MY2020_Rx" SG_ 502 Dsp_CutItem2_Rq 1;
BA_ "U_CD542_MY2021_Rx" SG_ 502 Dsp_CutItem2_Rq 1;
BA_ "U_U55X_MY2022_Rx" SG_ 502 Dsp_CutItem2_Rq 1;
BA_ "U_P702_MY2021_Tx" SG_ 502 Dsp_CutItem2_Rq 1;
BA_ "U_T6_MCA_MY2020_Tx" SG_ 502 Dsp_CutItem2_Rq 1;
BA_ "U_CD542_MY2021_Tx" SG_ 502 Dsp_CutItem2_Rq 1;
BA_ "U_U55X_MY2022_Tx" SG_ 502 Dsp_CutItem2_Rq 1;
BA_ "GenSigSendType" SG_ 502 Dsp_AudioSourceSel2_Rq 3;
BA_ "U_P702_MY2021_Rx" SG_ 502 Dsp_AudioSourceSel2_Rq 1;
BA_ "U_T6_MCA_MY2020_Rx" SG_ 502 Dsp_AudioSourceSel2_Rq 1;
BA_ "U_CD542_MY2021_Rx" SG_ 502 Dsp_AudioSourceSel2_Rq 1;
BA_ "U_U55X_MY2022_Rx" SG_ 502 Dsp_AudioSourceSel2_Rq 1;
BA_ "U_P702_MY2021_Tx" SG_ 502 Dsp_AudioSourceSel2_Rq 1;
BA_ "U_T6_MCA_MY2020_Tx" SG_ 502 Dsp_AudioSourceSel2_Rq 1;
BA_ "U_CD542_MY2021_Tx" SG_ 502 Dsp_AudioSourceSel2_Rq 1;
BA_ "U_U55X_MY2022_Tx" SG_ 502 Dsp_AudioSourceSel2_Rq 1;
BA_ "GenSigStartValueInteger" SG_ 955 Tire_Temp_RF_Data 253;
BA_ "GenSigStartValue" SG_ 955 Tire_Temp_RF_Data 253;
BA_ "U_T6_MCA_MY2020_Rx" SG_ 955 Tire_Temp_RF_Data 1;
BA_ "U_U55X_MY2022_Rx" SG_ 955 Tire_Temp_RF_Data 1;
BA_ "U_CD542_MY2021_Rx" SG_ 955 Tire_Temp_RF_Data 1;
BA_ "GenSigStartValueInteger" SG_ 955 Tire_Temp_ORR_Data 253;
BA_ "GenSigStartValue" SG_ 955 Tire_Temp_ORR_Data 253;
BA_ "U_T6_MCA_MY2020_Rx" SG_ 955 Tire_Temp_ORR_Data 1;
BA_ "U_U55X_MY2022_Rx" SG_ 955 Tire_Temp_ORR_Data 1;
BA_ "U_CD542_MY2021_Rx" SG_ 955 Tire_Temp_ORR_Data 1;
BA_ "GenSigStartValueInteger" SG_ 955 Tire_Temp_OLR_Data 253;
BA_ "GenSigStartValue" SG_ 955 Tire_Temp_OLR_Data 253;
BA_ "U_T6_MCA_MY2020_Rx" SG_ 955 Tire_Temp_OLR_Data 1;
BA_ "U_U55X_MY2022_Rx" SG_ 955 Tire_Temp_OLR_Data 1;
BA_ "U_CD542_MY2021_Rx" SG_ 955 Tire_Temp_OLR_Data 1;
BA_ "GenSigStartValueInteger" SG_ 955 Tire_Temp_LF_Data 253;
BA_ "GenSigStartValue" SG_ 955 Tire_Temp_LF_Data 253;
BA_ "U_T6_MCA_MY2020_Rx" SG_ 955 Tire_Temp_LF_Data 1;
BA_ "U_U55X_MY2022_Rx" SG_ 955 Tire_Temp_LF_Data 1;
BA_ "U_CD542_MY2021_Rx" SG_ 955 Tire_Temp_LF_Data 1;
BA_ "GenSigStartValueInteger" SG_ 955 Tire_Temp_IRR_Data 253;
BA_ "GenSigStartValue" SG_ 955 Tire_Temp_IRR_Data 253;
BA_ "U_T6_MCA_MY2020_Rx" SG_ 955 Tire_Temp_IRR_Data 1;
BA_ "U_U55X_MY2022_Rx" SG_ 955 Tire_Temp_IRR_Data 1;
BA_ "U_CD542_MY2021_Rx" SG_ 955 Tire_Temp_IRR_Data 1;
BA_ "GenSigStartValueInteger" SG_ 955 Tire_Temp_ILR_Data 253;
BA_ "GenSigStartValue" SG_ 955 Tire_Temp_ILR_Data 253;
BA_ "U_T6_MCA_MY2020_Rx" SG_ 955 Tire_Temp_ILR_Data 1;
BA_ "U_U55X_MY2022_Rx" SG_ 955 Tire_Temp_ILR_Data 1;
BA_ "U_CD542_MY2021_Rx" SG_ 955 Tire_Temp_ILR_Data 1;
BA_ "GenSigSendType" SG_ 1116 TrlrAidSetup_D2_Rq 3;
BA_ "U_T6_MCA_MY2020_Tx" SG_ 1116 TrlrAidSetup_D2_Rq 1;
BA_ "U_CD542_MY2021_Tx" SG_ 1116 TrlrAidSetup_D2_Rq 1;
BA_ "U_U55X_MY2022_Tx" SG_ 1116 TrlrAidSetup_D2_Rq 1;
BA_ "GenSigSendType" SG_ 1116 TrlrAidEnbl_D2_Rq 3;
BA_ "U_T6_MCA_MY2020_Tx" SG_ 1116 TrlrAidEnbl_D2_Rq 1;
BA_ "U_CD542_MY2021_Tx" SG_ 1116 TrlrAidEnbl_D2_Rq 1;
BA_ "U_U55X_MY2022_Tx" SG_ 1116 TrlrAidEnbl_D2_Rq 1;
BA_ "GenSigSendType" SG_ 1116 TlightTest_D_Mnu 3;
BA_ "ECGUsedRxSignal" SG_ 1116 TlightTest_D_Mnu 1;
BA_ "U_CD542_MY2021_Rx" SG_ 1116 TlightTest_D_Mnu 1;
BA_ "U_U55X_MY2022_Rx" SG_ 1116 TlightTest_D_Mnu 1;
BA_ "U_CD764_MY2022_Rx" SG_ 1116 TlightTest_D_Mnu 1;
BA_ "U_T6_MCA_MY2020_Tx" SG_ 1116 TlightTest_D_Mnu 1;
BA_ "U_CD542_MY2021_Tx" SG_ 1116 TlightTest_D_Mnu 1;
BA_ "U_U55X_MY2022_Tx" SG_ 1116 TlightTest_D_Mnu 1;
BA_ "U_T6_MCA_MY2020_Tx" SG_ 1116 TrlrTrgtToBmpr_L_Actl 1;
BA_ "U_CD542_MY2021_Tx" SG_ 1116 TrlrTrgtToBmpr_L_Actl 1;
BA_ "U_U55X_MY2022_Tx" SG_ 1116 TrlrTrgtToBmpr_L_Actl 1;
BA_ "U_T6_MCA_MY2020_Tx" SG_ 1116 TrlrTrgtPtrnId_No_Mem 1;
BA_ "U_CD542_MY2021_Tx" SG_ 1116 TrlrTrgtPtrnId_No_Mem 1;
BA_ "U_U55X_MY2022_Tx" SG_ 1116 TrlrTrgtPtrnId_No_Mem 1;
BA_ "GenSigSendType" SG_ 1116 TrlrRvrseCancl_B_Rq 3;
BA_ "U_T6_MCA_MY2020_Tx" SG_ 1116 TrlrRvrseCancl_B_Rq 1;
BA_ "U_CD542_MY2021_Tx" SG_ 1116 TrlrRvrseCancl_B_Rq 1;
BA_ "U_U55X_MY2022_Tx" SG_ 1116 TrlrRvrseCancl_B_Rq 1;
BA_ "GenSigSendType" SG_ 1116 TrlrIdType_D_Stat 3;
BA_ "U_T6_MCA_MY2020_Tx" SG_ 1116 TrlrIdType_D_Stat 1;
BA_ "U_CD542_MY2021_Tx" SG_ 1116 TrlrIdType_D_Stat 1;
BA_ "U_U55X_MY2022_Tx" SG_ 1116 TrlrIdType_D_Stat 1;
BA_ "U_T6_MCA_MY2020_Tx" SG_ 1116 TrlrId_No_Actl 1;
BA_ "U_CD542_MY2021_Tx" SG_ 1116 TrlrId_No_Actl 1;
BA_ "U_U55X_MY2022_Tx" SG_ 1116 TrlrId_No_Actl 1;
BA_ "U_T6_MCA_MY2020_Tx" SG_ 1116 TrlrBallToBmpr_L_Actl 1;
BA_ "U_CD542_MY2021_Tx" SG_ 1116 TrlrBallToBmpr_L_Actl 1;
BA_ "U_U55X_MY2022_Tx" SG_ 1116 TrlrBallToBmpr_L_Actl 1;
BA_ "U_T6_MCA_MY2020_Tx" SG_ 1116 TrlrAxleToBmpr_L_Actl 1;
BA_ "U_CD542_MY2021_Tx" SG_ 1116 TrlrAxleToBmpr_L_Actl 1;
BA_ "U_U55X_MY2022_Tx" SG_ 1116 TrlrAxleToBmpr_L_Actl 1;
BA_ "GenSigSendType" SG_ 1116 TrlrAnOffstDir_D_Mem 3;
BA_ "U_T6_MCA_MY2020_Tx" SG_ 1116 TrlrAnOffstDir_D_Mem 1;
BA_ "U_CD542_MY2021_Tx" SG_ 1116 TrlrAnOffstDir_D_Mem 1;
BA_ "U_U55X_MY2022_Tx" SG_ 1116 TrlrAnOffstDir_D_Mem 1;
BA_ "U_T6_MCA_MY2020_Tx" SG_ 1116 TrlrAnOffst_An_Mem 1;
BA_ "U_CD542_MY2021_Tx" SG_ 1116 TrlrAnOffst_An_Mem 1;
BA_ "U_U55X_MY2022_Tx" SG_ 1116 TrlrAnOffst_An_Mem 1;
BA_ "U_T6_MCA_MY2020_Tx" SG_ 1116 TrlrTrgtOffst_L_Actl 1;
BA_ "U_CD542_MY2021_Tx" SG_ 1116 TrlrTrgtOffst_L_Actl 1;
BA_ "U_U55X_MY2022_Tx" SG_ 1116 TrlrTrgtOffst_L_Actl 1;
BA_ "U_T6_MCA_MY2020_Rx" SG_ 1113 TrlrAnOffstDir_D_Calc_UB 1;
BA_ "U_U55X_MY2022_Rx" SG_ 1113 TrlrAnOffstDir_D_Calc_UB 1;
BA_ "U_P702_MY2021_Rx" SG_ 1113 TrlrAnOffstDir_D_Calc_UB 1;
BA_ "U_CD764_MY2022_Rx" SG_ 1113 TrlrAnOffstDir_D_Calc_UB 1;
BA_ "U_CD542_MY2021_Rx" SG_ 1113 TrlrAnOffstDir_D_Calc_UB 1;
BA_ "U_T6_MCA_MY2020_Rx" SG_ 1113 TrlrAnOffst_An_Calc_UB 1;
BA_ "U_U55X_MY2022_Rx" SG_ 1113 TrlrAnOffst_An_Calc_UB 1;
BA_ "U_P702_MY2021_Rx" SG_ 1113 TrlrAnOffst_An_Calc_UB 1;
BA_ "U_CD764_MY2022_Rx" SG_ 1113 TrlrAnOffst_An_Calc_UB 1;
BA_ "U_CD542_MY2021_Rx" SG_ 1113 TrlrAnOffst_An_Calc_UB 1;
BA_ "U_T6_MCA_MY2020_Rx" SG_ 1113 TrlrAnCalib_B_Complt_UB 1;
BA_ "U_U55X_MY2022_Rx" SG_ 1113 TrlrAnCalib_B_Complt_UB 1;
BA_ "U_CD764_MY2022_Rx" SG_ 1113 TrlrAnCalib_B_Complt_UB 1;
BA_ "U_CD542_MY2021_Rx" SG_ 1113 TrlrAnCalib_B_Complt_UB 1;
BA_ "U_T6_MCA_MY2020_Rx" SG_ 1113 TrlrAidTrgtId_No_Actl_UB 1;
BA_ "U_U55X_MY2022_Rx" SG_ 1113 TrlrAidTrgtId_No_Actl_UB 1;
BA_ "U_CD764_MY2022_Rx" SG_ 1113 TrlrAidTrgtId_No_Actl_UB 1;
BA_ "U_CD542_MY2021_Rx" SG_ 1113 TrlrAidTrgtId_No_Actl_UB 1;
BA_ "U_T6_MCA_MY2020_Rx" SG_ 1113 TrlrAnOffst_An_Calc 1;
BA_ "U_U55X_MY2022_Rx" SG_ 1113 TrlrAnOffst_An_Calc 1;
BA_ "U_P702_MY2021_Rx" SG_ 1113 TrlrAnOffst_An_Calc 1;
BA_ "U_CD764_MY2022_Rx" SG_ 1113 TrlrAnOffst_An_Calc 1;
BA_ "U_CD542_MY2021_Rx" SG_ 1113 TrlrAnOffst_An_Calc 1;
BA_ "U_T6_MCA_MY2020_Rx" SG_ 1113 TrlrAnCalib_B_Complt 1;
BA_ "U_U55X_MY2022_Rx" SG_ 1113 TrlrAnCalib_B_Complt 1;
BA_ "U_CD764_MY2022_Rx" SG_ 1113 TrlrAnCalib_B_Complt 1;
BA_ "U_CD542_MY2021_Rx" SG_ 1113 TrlrAnCalib_B_Complt 1;
BA_ "U_T6_MCA_MY2020_Rx" SG_ 1113 TrlrAnOffstDir_D_Calc 1;
BA_ "U_U55X_MY2022_Rx" SG_ 1113 TrlrAnOffstDir_D_Calc 1;
BA_ "U_P702_MY2021_Rx" SG_ 1113 TrlrAnOffstDir_D_Calc 1;
BA_ "U_CD764_MY2022_Rx" SG_ 1113 TrlrAnOffstDir_D_Calc 1;
BA_ "U_CD542_MY2021_Rx" SG_ 1113 TrlrAnOffstDir_D_Calc 1;
BA_ "U_T6_MCA_MY2020_Rx" SG_ 1113 TrlrAidTrgtId_No_Actl 1;
BA_ "U_U55X_MY2022_Rx" SG_ 1113 TrlrAidTrgtId_No_Actl 1;
BA_ "U_CD764_MY2022_Rx" SG_ 1113 TrlrAidTrgtId_No_Actl 1;
BA_ "U_CD542_MY2021_Rx" SG_ 1113 TrlrAidTrgtId_No_Actl 1;
BA_ "U_T6_MCA_MY2020_Rx" SG_ 1113 immoSecureIdleMode_UB 1;
BA_ "U_CD542_MY2021_Rx" SG_ 1113 immoSecureIdleMode_UB 1;
BA_ "U_U55X_MY2022_Rx" SG_ 1113 immoSecureIdleMode_UB 1;
BA_ "U_CD764_MY2022_Rx" SG_ 1113 immoSecureIdleMode_UB 1;
BA_ "U_T6_MCA_MY2020_Rx" SG_ 1113 immoSecureIdleMode 1;
BA_ "U_CD542_MY2021_Rx" SG_ 1113 immoSecureIdleMode 1;
BA_ "U_U55X_MY2022_Rx" SG_ 1113 immoSecureIdleMode 1;
BA_ "U_CD764_MY2022_Rx" SG_ 1113 immoSecureIdleMode 1;
BA_ "U_T6_MCA_MY2020_Rx" SG_ 1255 BalrRight4Threat_D_Stat 1;
BA_ "U_CD542_MY2021_Rx" SG_ 1255 BalrRight4Threat_D_Stat 1;
BA_ "GenSigStartValueInteger" SG_ 1255 BalrRight4Prev3Y_L_Actl 64;
BA_ "U_T6_MCA_MY2020_Rx" SG_ 1255 BalrRight4Prev3Y_L_Actl 1;
BA_ "U_CD542_MY2021_Rx" SG_ 1255 BalrRight4Prev3Y_L_Actl 1;
BA_ "GenSigStartValueInteger" SG_ 1255 BalrRight4Prev3X_L_Actl 64;
BA_ "U_T6_MCA_MY2020_Rx" SG_ 1255 BalrRight4Prev3X_L_Actl 1;
BA_ "U_CD542_MY2021_Rx" SG_ 1255 BalrRight4Prev3X_L_Actl 1;
BA_ "GenSigStartValueInteger" SG_ 1255 BalrRight4Prev2Y_L_Actl 64;
BA_ "U_T6_MCA_MY2020_Rx" SG_ 1255 BalrRight4Prev2Y_L_Actl 1;
BA_ "U_CD542_MY2021_Rx" SG_ 1255 BalrRight4Prev2Y_L_Actl 1;
BA_ "GenSigStartValueInteger" SG_ 1255 BalrRight4Prev2X_L_Actl 64;
BA_ "U_T6_MCA_MY2020_Rx" SG_ 1255 BalrRight4Prev2X_L_Actl 1;
BA_ "U_CD542_MY2021_Rx" SG_ 1255 BalrRight4Prev2X_L_Actl 1;
BA_ "GenSigStartValueInteger" SG_ 1255 BalrRight4Prev1Y_L_Actl 64;
BA_ "U_T6_MCA_MY2020_Rx" SG_ 1255 BalrRight4Prev1Y_L_Actl 1;
BA_ "U_CD542_MY2021_Rx" SG_ 1255 BalrRight4Prev1Y_L_Actl 1;
BA_ "GenSigStartValueInteger" SG_ 1255 BalrRight4Prev1X_L_Actl 64;
BA_ "U_T6_MCA_MY2020_Rx" SG_ 1255 BalrRight4Prev1X_L_Actl 1;
BA_ "U_CD542_MY2021_Rx" SG_ 1255 BalrRight4Prev1X_L_Actl 1;
BA_ "U_T6_MCA_MY2020_Rx" SG_ 1255 BalrRight4Fast_B_Stat 1;
BA_ "U_CD542_MY2021_Rx" SG_ 1255 BalrRight4Fast_B_Stat 1;
BA_ "U_T6_MCA_MY2020_Rx" SG_ 1255 BalrRight4Dsply_B_Stat 1;
BA_ "U_CD542_MY2021_Rx" SG_ 1255 BalrRight4Dsply_B_Stat 1;
BA_ "GenSigStartValueInteger" SG_ 1255 BalrRight4CurntY_L_Actl 64;
BA_ "U_T6_MCA_MY2020_Rx" SG_ 1255 BalrRight4CurntY_L_Actl 1;
BA_ "U_CD542_MY2021_Rx" SG_ 1255 BalrRight4CurntY_L_Actl 1;
BA_ "GenSigStartValueInteger" SG_ 1255 BalrRight4CurntX_L_Actl 64;
BA_ "U_T6_MCA_MY2020_Rx" SG_ 1255 BalrRight4CurntX_L_Actl 1;
BA_ "U_CD542_MY2021_Rx" SG_ 1255 BalrRight4CurntX_L_Actl 1;
BA_ "U_T6_MCA_MY2020_Rx" SG_ 1254 BalrRight3Threat_D_Stat 1;
BA_ "U_CD542_MY2021_Rx" SG_ 1254 BalrRight3Threat_D_Stat 1;
BA_ "GenSigStartValueInteger" SG_ 1254 BalrRight3Prev3Y_L_Actl 64;
BA_ "U_T6_MCA_MY2020_Rx" SG_ 1254 BalrRight3Prev3Y_L_Actl 1;
BA_ "U_CD542_MY2021_Rx" SG_ 1254 BalrRight3Prev3Y_L_Actl 1;
BA_ "GenSigStartValueInteger" SG_ 1254 BalrRight3Prev3X_L_Actl 64;
BA_ "U_T6_MCA_MY2020_Rx" SG_ 1254 BalrRight3Prev3X_L_Actl 1;
BA_ "U_CD542_MY2021_Rx" SG_ 1254 BalrRight3Prev3X_L_Actl 1;
BA_ "GenSigStartValueInteger" SG_ 1254 BalrRight3Prev2Y_L_Actl 64;
BA_ "U_T6_MCA_MY2020_Rx" SG_ 1254 BalrRight3Prev2Y_L_Actl 1;
BA_ "U_CD542_MY2021_Rx" SG_ 1254 BalrRight3Prev2Y_L_Actl 1;
BA_ "GenSigStartValueInteger" SG_ 1254 BalrRight3Prev2X_L_Actl 64;
BA_ "U_T6_MCA_MY2020_Rx" SG_ 1254 BalrRight3Prev2X_L_Actl 1;
BA_ "U_CD542_MY2021_Rx" SG_ 1254 BalrRight3Prev2X_L_Actl 1;
BA_ "GenSigStartValueInteger" SG_ 1254 BalrRight3Prev1Y_L_Actl 64;
BA_ "U_T6_MCA_MY2020_Rx" SG_ 1254 BalrRight3Prev1Y_L_Actl 1;
BA_ "U_CD542_MY2021_Rx" SG_ 1254 BalrRight3Prev1Y_L_Actl 1;
BA_ "GenSigStartValueInteger" SG_ 1254 BalrRight3Prev1X_L_Actl 64;
BA_ "U_T6_MCA_MY2020_Rx" SG_ 1254 BalrRight3Prev1X_L_Actl 1;
BA_ "U_CD542_MY2021_Rx" SG_ 1254 BalrRight3Prev1X_L_Actl 1;
BA_ "U_T6_MCA_MY2020_Rx" SG_ 1254 BalrRight3Fast_B_Stat 1;
BA_ "U_CD542_MY2021_Rx" SG_ 1254 BalrRight3Fast_B_Stat 1;
BA_ "U_T6_MCA_MY2020_Rx" SG_ 1254 BalrRight3Dsply_B_Stat 1;
BA_ "U_CD542_MY2021_Rx" SG_ 1254 BalrRight3Dsply_B_Stat 1;
BA_ "GenSigStartValueInteger" SG_ 1254 BalrRight3CurntY_L_Actl 64;
BA_ "U_T6_MCA_MY2020_Rx" SG_ 1254 BalrRight3CurntY_L_Actl 1;
BA_ "U_CD542_MY2021_Rx" SG_ 1254 BalrRight3CurntY_L_Actl 1;
BA_ "GenSigStartValueInteger" SG_ 1254 BalrRight3CurntX_L_Actl 64;
BA_ "U_T6_MCA_MY2020_Rx" SG_ 1254 BalrRight3CurntX_L_Actl 1;
BA_ "U_CD542_MY2021_Rx" SG_ 1254 BalrRight3CurntX_L_Actl 1;
BA_ "GenSigStartValueInteger" SG_ 1253 BalrRight2Prev3Y_L_Actl 64;
BA_ "U_T6_MCA_MY2020_Rx" SG_ 1253 BalrRight2Prev3Y_L_Actl 1;
BA_ "U_CD542_MY2021_Rx" SG_ 1253 BalrRight2Prev3Y_L_Actl 1;
BA_ "GenSigStartValueInteger" SG_ 1253 BalrRight2Prev3X_L_Actl 64;
BA_ "U_T6_MCA_MY2020_Rx" SG_ 1253 BalrRight2Prev3X_L_Actl 1;
BA_ "U_CD542_MY2021_Rx" SG_ 1253 BalrRight2Prev3X_L_Actl 1;
BA_ "U_T6_MCA_MY2020_Rx" SG_ 1253 BalrRight2Threat_D_Stat 1;
BA_ "U_CD542_MY2021_Rx" SG_ 1253 BalrRight2Threat_D_Stat 1;
BA_ "GenSigStartValueInteger" SG_ 1253 BalrRight2Prev2Y_L_Actl 64;
BA_ "U_T6_MCA_MY2020_Rx" SG_ 1253 BalrRight2Prev2Y_L_Actl 1;
BA_ "U_CD542_MY2021_Rx" SG_ 1253 BalrRight2Prev2Y_L_Actl 1;
BA_ "GenSigStartValueInteger" SG_ 1253 BalrRight2Prev2X_L_Actl 64;
BA_ "U_T6_MCA_MY2020_Rx" SG_ 1253 BalrRight2Prev2X_L_Actl 1;
BA_ "U_CD542_MY2021_Rx" SG_ 1253 BalrRight2Prev2X_L_Actl 1;
BA_ "GenSigStartValueInteger" SG_ 1253 BalrRight2Prev1Y_L_Actl 64;
BA_ "U_T6_MCA_MY2020_Rx" SG_ 1253 BalrRight2Prev1Y_L_Actl 1;
BA_ "U_CD542_MY2021_Rx" SG_ 1253 BalrRight2Prev1Y_L_Actl 1;
BA_ "GenSigStartValueInteger" SG_ 1253 BalrRight2Prev1X_L_Actl 64;
BA_ "U_T6_MCA_MY2020_Rx" SG_ 1253 BalrRight2Prev1X_L_Actl 1;
BA_ "U_CD542_MY2021_Rx" SG_ 1253 BalrRight2Prev1X_L_Actl 1;
BA_ "U_T6_MCA_MY2020_Rx" SG_ 1253 BalrRight2Fast_B_Stat 1;
BA_ "U_CD542_MY2021_Rx" SG_ 1253 BalrRight2Fast_B_Stat 1;
BA_ "U_T6_MCA_MY2020_Rx" SG_ 1253 BalrRight2Dsply_B_Stat 1;
BA_ "U_CD542_MY2021_Rx" SG_ 1253 BalrRight2Dsply_B_Stat 1;
BA_ "GenSigStartValueInteger" SG_ 1253 BalrRight2CurntY_L_Actl 64;
BA_ "U_T6_MCA_MY2020_Rx" SG_ 1253 BalrRight2CurntY_L_Actl 1;
BA_ "U_CD542_MY2021_Rx" SG_ 1253 BalrRight2CurntY_L_Actl 1;
BA_ "GenSigStartValueInteger" SG_ 1253 BalrRight2CurntX_L_Actl 64;
BA_ "U_T6_MCA_MY2020_Rx" SG_ 1253 BalrRight2CurntX_L_Actl 1;
BA_ "U_CD542_MY2021_Rx" SG_ 1253 BalrRight2CurntX_L_Actl 1;
BA_ "GenSigStartValueInteger" SG_ 1252 BalrRight1Prev3Y_L_Actl 64;
BA_ "U_T6_MCA_MY2020_Rx" SG_ 1252 BalrRight1Prev3Y_L_Actl 1;
BA_ "U_CD542_MY2021_Rx" SG_ 1252 BalrRight1Prev3Y_L_Actl 1;
BA_ "GenSigStartValueInteger" SG_ 1252 BalrRight1Prev3X_L_Actl 64;
BA_ "U_T6_MCA_MY2020_Rx" SG_ 1252 BalrRight1Prev3X_L_Actl 1;
BA_ "U_CD542_MY2021_Rx" SG_ 1252 BalrRight1Prev3X_L_Actl 1;
BA_ "U_T6_MCA_MY2020_Rx" SG_ 1252 BalrRight1Threat_D_Stat 1;
BA_ "U_CD542_MY2021_Rx" SG_ 1252 BalrRight1Threat_D_Stat 1;
BA_ "GenSigStartValueInteger" SG_ 1252 BalrRight1Prev2Y_L_Actl 64;
BA_ "U_T6_MCA_MY2020_Rx" SG_ 1252 BalrRight1Prev2Y_L_Actl 1;
BA_ "U_CD542_MY2021_Rx" SG_ 1252 BalrRight1Prev2Y_L_Actl 1;
BA_ "GenSigStartValueInteger" SG_ 1252 BalrRight1Prev2X_L_Actl 64;
BA_ "U_T6_MCA_MY2020_Rx" SG_ 1252 BalrRight1Prev2X_L_Actl 1;
BA_ "U_CD542_MY2021_Rx" SG_ 1252 BalrRight1Prev2X_L_Actl 1;
BA_ "GenSigStartValueInteger" SG_ 1252 BalrRight1Prev1Y_L_Actl 64;
BA_ "U_T6_MCA_MY2020_Rx" SG_ 1252 BalrRight1Prev1Y_L_Actl 1;
BA_ "U_CD542_MY2021_Rx" SG_ 1252 BalrRight1Prev1Y_L_Actl 1;
BA_ "GenSigStartValueInteger" SG_ 1252 BalrRight1Prev1X_L_Actl 64;
BA_ "U_T6_MCA_MY2020_Rx" SG_ 1252 BalrRight1Prev1X_L_Actl 1;
BA_ "U_CD542_MY2021_Rx" SG_ 1252 BalrRight1Prev1X_L_Actl 1;
BA_ "U_T6_MCA_MY2020_Rx" SG_ 1252 BalrRight1Fast_B_Stat 1;
BA_ "U_CD542_MY2021_Rx" SG_ 1252 BalrRight1Fast_B_Stat 1;
BA_ "U_T6_MCA_MY2020_Rx" SG_ 1252 BalrRight1Dsply_B_Stat 1;
BA_ "U_CD542_MY2021_Rx" SG_ 1252 BalrRight1Dsply_B_Stat 1;
BA_ "GenSigStartValueInteger" SG_ 1252 BalrRight1CurntY_L_Actl 64;
BA_ "U_T6_MCA_MY2020_Rx" SG_ 1252 BalrRight1CurntY_L_Actl 1;
BA_ "U_CD542_MY2021_Rx" SG_ 1252 BalrRight1CurntY_L_Actl 1;
BA_ "GenSigStartValueInteger" SG_ 1252 BalrRight1CurntX_L_Actl 64;
BA_ "U_T6_MCA_MY2020_Rx" SG_ 1252 BalrRight1CurntX_L_Actl 1;
BA_ "U_CD542_MY2021_Rx" SG_ 1252 BalrRight1CurntX_L_Actl 1;
BA_ "U_T6_MCA_MY2020_Rx" SG_ 1251 BalrLeft4Threat_D_Stat 1;
BA_ "U_CD542_MY2021_Rx" SG_ 1251 BalrLeft4Threat_D_Stat 1;
BA_ "GenSigStartValueInteger" SG_ 1251 BalrLeft4Prev3Y_L_Actl 64;
BA_ "U_T6_MCA_MY2020_Rx" SG_ 1251 BalrLeft4Prev3Y_L_Actl 1;
BA_ "U_CD542_MY2021_Rx" SG_ 1251 BalrLeft4Prev3Y_L_Actl 1;
BA_ "GenSigStartValueInteger" SG_ 1251 BalrLeft4Prev3X_L_Actl 64;
BA_ "U_T6_MCA_MY2020_Rx" SG_ 1251 BalrLeft4Prev3X_L_Actl 1;
BA_ "U_CD542_MY2021_Rx" SG_ 1251 BalrLeft4Prev3X_L_Actl 1;
BA_ "GenSigStartValueInteger" SG_ 1251 BalrLeft4Prev2Y_L_Actl 64;
BA_ "U_T6_MCA_MY2020_Rx" SG_ 1251 BalrLeft4Prev2Y_L_Actl 1;
BA_ "U_CD542_MY2021_Rx" SG_ 1251 BalrLeft4Prev2Y_L_Actl 1;
BA_ "GenSigStartValueInteger" SG_ 1251 BalrLeft4Prev2X_L_Actl 64;
BA_ "U_T6_MCA_MY2020_Rx" SG_ 1251 BalrLeft4Prev2X_L_Actl 1;
BA_ "U_CD542_MY2021_Rx" SG_ 1251 BalrLeft4Prev2X_L_Actl 1;
BA_ "GenSigStartValueInteger" SG_ 1251 BalrLeft4Prev1Y_L_Actl 64;
BA_ "U_T6_MCA_MY2020_Rx" SG_ 1251 BalrLeft4Prev1Y_L_Actl 1;
BA_ "U_CD542_MY2021_Rx" SG_ 1251 BalrLeft4Prev1Y_L_Actl 1;
BA_ "GenSigStartValueInteger" SG_ 1251 BalrLeft4Prev1X_L_Actl 64;
BA_ "U_T6_MCA_MY2020_Rx" SG_ 1251 BalrLeft4Prev1X_L_Actl 1;
BA_ "U_CD542_MY2021_Rx" SG_ 1251 BalrLeft4Prev1X_L_Actl 1;
BA_ "U_T6_MCA_MY2020_Rx" SG_ 1251 BalrLeft4Fast_B_Stat 1;
BA_ "U_CD542_MY2021_Rx" SG_ 1251 BalrLeft4Fast_B_Stat 1;
BA_ "U_T6_MCA_MY2020_Rx" SG_ 1251 BalrLeft4Dsply_B_Stat 1;
BA_ "U_CD542_MY2021_Rx" SG_ 1251 BalrLeft4Dsply_B_Stat 1;
BA_ "GenSigStartValueInteger" SG_ 1251 BalrLeft4CurntY_L_Actl 64;
BA_ "U_T6_MCA_MY2020_Rx" SG_ 1251 BalrLeft4CurntY_L_Actl 1;
BA_ "U_CD542_MY2021_Rx" SG_ 1251 BalrLeft4CurntY_L_Actl 1;
BA_ "GenSigStartValueInteger" SG_ 1251 BalrLeft4CurntX_L_Actl 64;
BA_ "U_T6_MCA_MY2020_Rx" SG_ 1251 BalrLeft4CurntX_L_Actl 1;
BA_ "U_CD542_MY2021_Rx" SG_ 1251 BalrLeft4CurntX_L_Actl 1;
BA_ "U_T6_MCA_MY2020_Rx" SG_ 1250 BalrLeft3Threat_D_Stat 1;
BA_ "U_CD542_MY2021_Rx" SG_ 1250 BalrLeft3Threat_D_Stat 1;
BA_ "GenSigStartValueInteger" SG_ 1250 BalrLeft3Prev3Y_L_Actl 64;
BA_ "U_T6_MCA_MY2020_Rx" SG_ 1250 BalrLeft3Prev3Y_L_Actl 1;
BA_ "U_CD542_MY2021_Rx" SG_ 1250 BalrLeft3Prev3Y_L_Actl 1;
BA_ "GenSigStartValueInteger" SG_ 1250 BalrLeft3Prev3X_L_Actl 64;
BA_ "U_T6_MCA_MY2020_Rx" SG_ 1250 BalrLeft3Prev3X_L_Actl 1;
BA_ "U_CD542_MY2021_Rx" SG_ 1250 BalrLeft3Prev3X_L_Actl 1;
BA_ "GenSigStartValueInteger" SG_ 1250 BalrLeft3Prev2Y_L_Actl 64;
BA_ "U_T6_MCA_MY2020_Rx" SG_ 1250 BalrLeft3Prev2Y_L_Actl 1;
BA_ "U_CD542_MY2021_Rx" SG_ 1250 BalrLeft3Prev2Y_L_Actl 1;
BA_ "GenSigStartValueInteger" SG_ 1250 BalrLeft3Prev2X_L_Actl 64;
BA_ "U_T6_MCA_MY2020_Rx" SG_ 1250 BalrLeft3Prev2X_L_Actl 1;
BA_ "U_CD542_MY2021_Rx" SG_ 1250 BalrLeft3Prev2X_L_Actl 1;
BA_ "GenSigStartValueInteger" SG_ 1250 BalrLeft3Prev1Y_L_Actl 64;
BA_ "U_T6_MCA_MY2020_Rx" SG_ 1250 BalrLeft3Prev1Y_L_Actl 1;
BA_ "U_CD542_MY2021_Rx" SG_ 1250 BalrLeft3Prev1Y_L_Actl 1;
BA_ "GenSigStartValueInteger" SG_ 1250 BalrLeft3Prev1X_L_Actl 64;
BA_ "U_T6_MCA_MY2020_Rx" SG_ 1250 BalrLeft3Prev1X_L_Actl 1;
BA_ "U_CD542_MY2021_Rx" SG_ 1250 BalrLeft3Prev1X_L_Actl 1;
BA_ "U_T6_MCA_MY2020_Rx" SG_ 1250 BalrLeft3Fast_B_Stat 1;
BA_ "U_CD542_MY2021_Rx" SG_ 1250 BalrLeft3Fast_B_Stat 1;
BA_ "U_T6_MCA_MY2020_Rx" SG_ 1250 BalrLeft3Dsply_B_Stat 1;
BA_ "U_CD542_MY2021_Rx" SG_ 1250 BalrLeft3Dsply_B_Stat 1;
BA_ "GenSigStartValueInteger" SG_ 1250 BalrLeft3CurntY_L_Actl 64;
BA_ "U_T6_MCA_MY2020_Rx" SG_ 1250 BalrLeft3CurntY_L_Actl 1;
BA_ "U_CD542_MY2021_Rx" SG_ 1250 BalrLeft3CurntY_L_Actl 1;
BA_ "GenSigStartValueInteger" SG_ 1250 BalrLeft3CurntX_L_Actl 64;
BA_ "U_T6_MCA_MY2020_Rx" SG_ 1250 BalrLeft3CurntX_L_Actl 1;
BA_ "U_CD542_MY2021_Rx" SG_ 1250 BalrLeft3CurntX_L_Actl 1;
BA_ "GenSigStartValueInteger" SG_ 1249 BalrLeft2Prev3Y_L_Actl 64;
BA_ "U_T6_MCA_MY2020_Rx" SG_ 1249 BalrLeft2Prev3Y_L_Actl 1;
BA_ "U_CD542_MY2021_Rx" SG_ 1249 BalrLeft2Prev3Y_L_Actl 1;
BA_ "GenSigStartValueInteger" SG_ 1249 BalrLeft2Prev3X_L_Actl 64;
BA_ "U_T6_MCA_MY2020_Rx" SG_ 1249 BalrLeft2Prev3X_L_Actl 1;
BA_ "U_CD542_MY2021_Rx" SG_ 1249 BalrLeft2Prev3X_L_Actl 1;
BA_ "U_T6_MCA_MY2020_Rx" SG_ 1249 BalrLeft2Threat_D_Stat 1;
BA_ "U_CD542_MY2021_Rx" SG_ 1249 BalrLeft2Threat_D_Stat 1;
BA_ "GenSigStartValueInteger" SG_ 1249 BalrLeft2Prev2Y_L_Actl 64;
BA_ "U_T6_MCA_MY2020_Rx" SG_ 1249 BalrLeft2Prev2Y_L_Actl 1;
BA_ "U_CD542_MY2021_Rx" SG_ 1249 BalrLeft2Prev2Y_L_Actl 1;
BA_ "GenSigStartValueInteger" SG_ 1249 BalrLeft2Prev2X_L_Actl 64;
BA_ "U_T6_MCA_MY2020_Rx" SG_ 1249 BalrLeft2Prev2X_L_Actl 1;
BA_ "U_CD542_MY2021_Rx" SG_ 1249 BalrLeft2Prev2X_L_Actl 1;
BA_ "GenSigStartValueInteger" SG_ 1249 BalrLeft2Prev1Y_L_Actl 64;
BA_ "U_T6_MCA_MY2020_Rx" SG_ 1249 BalrLeft2Prev1Y_L_Actl 1;
BA_ "U_CD542_MY2021_Rx" SG_ 1249 BalrLeft2Prev1Y_L_Actl 1;
BA_ "GenSigStartValueInteger" SG_ 1249 BalrLeft2Prev1X_L_Actl 64;
BA_ "U_T6_MCA_MY2020_Rx" SG_ 1249 BalrLeft2Prev1X_L_Actl 1;
BA_ "U_CD542_MY2021_Rx" SG_ 1249 BalrLeft2Prev1X_L_Actl 1;
BA_ "U_T6_MCA_MY2020_Rx" SG_ 1249 BalrLeft2Fast_B_Stat 1;
BA_ "U_CD542_MY2021_Rx" SG_ 1249 BalrLeft2Fast_B_Stat 1;
BA_ "U_T6_MCA_MY2020_Rx" SG_ 1249 BalrLeft2Dsply_B_Stat 1;
BA_ "U_CD542_MY2021_Rx" SG_ 1249 BalrLeft2Dsply_B_Stat 1;
BA_ "GenSigStartValueInteger" SG_ 1249 BalrLeft2CurntY_L_Actl 64;
BA_ "U_T6_MCA_MY2020_Rx" SG_ 1249 BalrLeft2CurntY_L_Actl 1;
BA_ "U_CD542_MY2021_Rx" SG_ 1249 BalrLeft2CurntY_L_Actl 1;
BA_ "GenSigStartValueInteger" SG_ 1249 BalrLeft2CurntX_L_Actl 64;
BA_ "U_T6_MCA_MY2020_Rx" SG_ 1249 BalrLeft2CurntX_L_Actl 1;
BA_ "U_CD542_MY2021_Rx" SG_ 1249 BalrLeft2CurntX_L_Actl 1;
BA_ "U_T6_MCA_MY2020_Rx" SG_ 1248 BalrLeft1Threat_D_Stat 1;
BA_ "U_CD542_MY2021_Rx" SG_ 1248 BalrLeft1Threat_D_Stat 1;
BA_ "GenSigStartValueInteger" SG_ 1248 BalrLeft1Prev3Y_L_Actl 64;
BA_ "U_T6_MCA_MY2020_Rx" SG_ 1248 BalrLeft1Prev3Y_L_Actl 1;
BA_ "U_CD542_MY2021_Rx" SG_ 1248 BalrLeft1Prev3Y_L_Actl 1;
BA_ "GenSigStartValueInteger" SG_ 1248 BalrLeft1Prev3X_L_Actl 64;
BA_ "U_T6_MCA_MY2020_Rx" SG_ 1248 BalrLeft1Prev3X_L_Actl 1;
BA_ "U_CD542_MY2021_Rx" SG_ 1248 BalrLeft1Prev3X_L_Actl 1;
BA_ "GenSigStartValueInteger" SG_ 1248 BalrLeft1Prev2Y_L_Actl 64;
BA_ "U_T6_MCA_MY2020_Rx" SG_ 1248 BalrLeft1Prev2Y_L_Actl 1;
BA_ "U_CD542_MY2021_Rx" SG_ 1248 BalrLeft1Prev2Y_L_Actl 1;
BA_ "GenSigStartValueInteger" SG_ 1248 BalrLeft1Prev2X_L_Actl 64;
BA_ "U_T6_MCA_MY2020_Rx" SG_ 1248 BalrLeft1Prev2X_L_Actl 1;
BA_ "U_CD542_MY2021_Rx" SG_ 1248 BalrLeft1Prev2X_L_Actl 1;
BA_ "GenSigStartValueInteger" SG_ 1248 BalrLeft1Prev1Y_L_Actl 64;
BA_ "U_T6_MCA_MY2020_Rx" SG_ 1248 BalrLeft1Prev1Y_L_Actl 1;
BA_ "U_CD542_MY2021_Rx" SG_ 1248 BalrLeft1Prev1Y_L_Actl 1;
BA_ "GenSigStartValueInteger" SG_ 1248 BalrLeft1Prev1X_L_Actl 64;
BA_ "U_T6_MCA_MY2020_Rx" SG_ 1248 BalrLeft1Prev1X_L_Actl 1;
BA_ "U_CD542_MY2021_Rx" SG_ 1248 BalrLeft1Prev1X_L_Actl 1;
BA_ "U_T6_MCA_MY2020_Rx" SG_ 1248 BalrLeft1Fast_B_Stat 1;
BA_ "U_CD542_MY2021_Rx" SG_ 1248 BalrLeft1Fast_B_Stat 1;
BA_ "U_T6_MCA_MY2020_Rx" SG_ 1248 BalrLeft1Dsply_B_Stat 1;
BA_ "U_CD542_MY2021_Rx" SG_ 1248 BalrLeft1Dsply_B_Stat 1;
BA_ "GenSigStartValueInteger" SG_ 1248 BalrLeft1CurntY_L_Actl 64;
BA_ "U_T6_MCA_MY2020_Rx" SG_ 1248 BalrLeft1CurntY_L_Actl 1;
BA_ "U_CD542_MY2021_Rx" SG_ 1248 BalrLeft1CurntY_L_Actl 1;
BA_ "GenSigStartValueInteger" SG_ 1248 BalrLeft1CurntX_L_Actl 64;
BA_ "U_T6_MCA_MY2020_Rx" SG_ 1248 BalrLeft1CurntX_L_Actl 1;
BA_ "U_CD542_MY2021_Rx" SG_ 1248 BalrLeft1CurntX_L_Actl 1;
BA_ "U_T6_MCA_MY2020_Rx" SG_ 1256 BalrMdeRight_D_Stat_UB 1;
BA_ "U_CD542_MY2021_Rx" SG_ 1256 BalrMdeRight_D_Stat_UB 1;
BA_ "U_T6_MCA_MY2020_Rx" SG_ 1256 BalrMdeSelRight_B_Stat_UB 1;
BA_ "U_CD542_MY2021_Rx" SG_ 1256 BalrMdeSelRight_B_Stat_UB 1;
BA_ "U_T6_MCA_MY2020_Rx" SG_ 1256 BalrRight_D_Stat_UB 1;
BA_ "U_CD542_MY2021_Rx" SG_ 1256 BalrRight_D_Stat_UB 1;
BA_ "U_T6_MCA_MY2020_Rx" SG_ 1256 BalrLckRight_B_Stat_UB 1;
BA_ "U_CD542_MY2021_Rx" SG_ 1256 BalrLckRight_B_Stat_UB 1;
BA_ "U_T6_MCA_MY2020_Rx" SG_ 1256 BalrChimeRight_D_Rq_UB 1;
BA_ "U_CD542_MY2021_Rx" SG_ 1256 BalrChimeRight_D_Rq_UB 1;
BA_ "U_T6_MCA_MY2020_Rx" SG_ 1256 BalrSnsRight_D_Falt_UB 1;
BA_ "U_CD542_MY2021_Rx" SG_ 1256 BalrSnsRight_D_Falt_UB 1;
BA_ "U_T6_MCA_MY2020_Rx" SG_ 1256 BalrWndwRight_B_Stat_UB 1;
BA_ "U_CD542_MY2021_Rx" SG_ 1256 BalrWndwRight_B_Stat_UB 1;
BA_ "GenSigSendType" SG_ 1256 BalrLckRight_B_Stat 3;
BA_ "U_T6_MCA_MY2020_Rx" SG_ 1256 BalrLckRight_B_Stat 1;
BA_ "U_CD542_MY2021_Rx" SG_ 1256 BalrLckRight_B_Stat 1;
BA_ "GenSigSendType" SG_ 1256 BalrWndwRight_B_Stat 3;
BA_ "U_T6_MCA_MY2020_Rx" SG_ 1256 BalrWndwRight_B_Stat 1;
BA_ "U_CD542_MY2021_Rx" SG_ 1256 BalrWndwRight_B_Stat 1;
BA_ "GenSigSendType" SG_ 1256 BalrMdeSelRight_B_Stat 3;
BA_ "U_T6_MCA_MY2020_Rx" SG_ 1256 BalrMdeSelRight_B_Stat 1;
BA_ "U_CD542_MY2021_Rx" SG_ 1256 BalrMdeSelRight_B_Stat 1;
BA_ "GenSigSendType" SG_ 1256 BalrSnsRight_D_Falt 3;
BA_ "U_T6_MCA_MY2020_Rx" SG_ 1256 BalrSnsRight_D_Falt 1;
BA_ "U_CD542_MY2021_Rx" SG_ 1256 BalrSnsRight_D_Falt 1;
BA_ "GenSigSendType" SG_ 1256 BalrChimeRight_D_Rq 3;
BA_ "U_T6_MCA_MY2020_Rx" SG_ 1256 BalrChimeRight_D_Rq 1;
BA_ "U_CD542_MY2021_Rx" SG_ 1256 BalrChimeRight_D_Rq 1;
BA_ "GenSigStartValueInteger" SG_ 1256 BalrMdeRight_D_Stat 1;
BA_ "GenSigStartValue" SG_ 1256 BalrMdeRight_D_Stat 1;
BA_ "GenSigSendType" SG_ 1256 BalrMdeRight_D_Stat 3;
BA_ "U_T6_MCA_MY2020_Rx" SG_ 1256 BalrMdeRight_D_Stat 1;
BA_ "U_CD542_MY2021_Rx" SG_ 1256 BalrMdeRight_D_Stat 1;
BA_ "GenSigStartValueInteger" SG_ 1256 BalrRight_D_Stat 2;
BA_ "GenSigStartValue" SG_ 1256 BalrRight_D_Stat 2;
BA_ "GenSigSendType" SG_ 1256 BalrRight_D_Stat 3;
BA_ "U_T6_MCA_MY2020_Rx" SG_ 1256 BalrRight_D_Stat 1;
BA_ "U_CD542_MY2021_Rx" SG_ 1256 BalrRight_D_Stat 1;
BA_ "U_T6_MCA_MY2020_Rx" SG_ 1256 BalrWndwLeft_B_Stat_UB 1;
BA_ "U_CD542_MY2021_Rx" SG_ 1256 BalrWndwLeft_B_Stat_UB 1;
BA_ "U_T6_MCA_MY2020_Rx" SG_ 1256 BalrSnsLeft_D_Falt_UB 1;
BA_ "U_CD542_MY2021_Rx" SG_ 1256 BalrSnsLeft_D_Falt_UB 1;
BA_ "U_T6_MCA_MY2020_Rx" SG_ 1256 BalrMdeSelLeft_B_Stat_UB 1;
BA_ "U_CD542_MY2021_Rx" SG_ 1256 BalrMdeSelLeft_B_Stat_UB 1;
BA_ "U_T6_MCA_MY2020_Rx" SG_ 1256 BalrMdeLeft_D_Stat_UB 1;
BA_ "U_CD542_MY2021_Rx" SG_ 1256 BalrMdeLeft_D_Stat_UB 1;
BA_ "U_T6_MCA_MY2020_Rx" SG_ 1256 BalrLeft_D_Stat_UB 1;
BA_ "U_CD542_MY2021_Rx" SG_ 1256 BalrLeft_D_Stat_UB 1;
BA_ "U_T6_MCA_MY2020_Rx" SG_ 1256 BalrLckLeft_B_Stat_UB 1;
BA_ "U_CD542_MY2021_Rx" SG_ 1256 BalrLckLeft_B_Stat_UB 1;
BA_ "U_T6_MCA_MY2020_Rx" SG_ 1256 BalrChimeLeft_D_Rq_UB 1;
BA_ "U_CD542_MY2021_Rx" SG_ 1256 BalrChimeLeft_D_Rq_UB 1;
BA_ "GenSigStartValueInteger" SG_ 1256 BalrLeft_D_Stat 2;
BA_ "GenSigStartValue" SG_ 1256 BalrLeft_D_Stat 2;
BA_ "GenSigSendType" SG_ 1256 BalrLeft_D_Stat 3;
BA_ "U_T6_MCA_MY2020_Rx" SG_ 1256 BalrLeft_D_Stat 1;
BA_ "U_CD542_MY2021_Rx" SG_ 1256 BalrLeft_D_Stat 1;
BA_ "GenSigSendType" SG_ 1256 BalrMdeSelLeft_B_Stat 3;
BA_ "U_T6_MCA_MY2020_Rx" SG_ 1256 BalrMdeSelLeft_B_Stat 1;
BA_ "U_CD542_MY2021_Rx" SG_ 1256 BalrMdeSelLeft_B_Stat 1;
BA_ "GenSigSendType" SG_ 1256 BalrLckLeft_B_Stat 3;
BA_ "U_T6_MCA_MY2020_Rx" SG_ 1256 BalrLckLeft_B_Stat 1;
BA_ "U_CD542_MY2021_Rx" SG_ 1256 BalrLckLeft_B_Stat 1;
BA_ "GenSigSendType" SG_ 1256 BalrWndwLeft_B_Stat 3;
BA_ "U_T6_MCA_MY2020_Rx" SG_ 1256 BalrWndwLeft_B_Stat 1;
BA_ "U_CD542_MY2021_Rx" SG_ 1256 BalrWndwLeft_B_Stat 1;
BA_ "U_CD764_MY2022_Rx" SG_ 1256 BalrWndwLeft_B_Stat 1;
BA_ "GenSigStartValueInteger" SG_ 1256 BalrMdeLeft_D_Stat 1;
BA_ "GenSigStartValue" SG_ 1256 BalrMdeLeft_D_Stat 1;
BA_ "GenSigSendType" SG_ 1256 BalrMdeLeft_D_Stat 3;
BA_ "U_T6_MCA_MY2020_Rx" SG_ 1256 BalrMdeLeft_D_Stat 1;
BA_ "U_CD542_MY2021_Rx" SG_ 1256 BalrMdeLeft_D_Stat 1;
BA_ "GenSigSendType" SG_ 1256 BalrSnsLeft_D_Falt 3;
BA_ "U_T6_MCA_MY2020_Rx" SG_ 1256 BalrSnsLeft_D_Falt 1;
BA_ "U_CD542_MY2021_Rx" SG_ 1256 BalrSnsLeft_D_Falt 1;
BA_ "GenSigSendType" SG_ 1256 BalrChimeLeft_D_Rq 3;
BA_ "U_T6_MCA_MY2020_Rx" SG_ 1256 BalrChimeLeft_D_Rq 1;
BA_ "U_CD542_MY2021_Rx" SG_ 1256 BalrChimeLeft_D_Rq 1;
BA_ "U_T6_MCA_MY2020_Rx" SG_ 1256 WakeAlarm2_D_Stat_UB 1;
BA_ "U_U55X_MY2022_Rx" SG_ 1256 WakeAlarm2_D_Stat_UB 1;
BA_ "GenSigStartValueInteger" SG_ 1256 WakeAlarm2_D_Stat 3;
BA_ "GenSigStartValue" SG_ 1256 WakeAlarm2_D_Stat 3;
BA_ "GenSigSendType" SG_ 1256 WakeAlarm2_D_Stat 3;
BA_ "U_T6_MCA_MY2020_Rx" SG_ 1256 WakeAlarm2_D_Stat 1;
BA_ "U_U55X_MY2022_Rx" SG_ 1256 WakeAlarm2_D_Stat 1;
BA_ "U_CD542_MY2021_Tx" SG_ 529 OnbChrgToPcWknd_D_Actl 1;
BA_ "U_U55X_MY2022_Tx" SG_ 529 OnbChrgToPcWknd_D_Actl 1;
BA_ "U_P702_MY2021_Tx" SG_ 529 OnbChrgToPcWknd_D_Actl 1;
BA_ "U_T6_MCA_MY2020_Tx" SG_ 529 OnbChrgToPcWknd_D_Actl 1;
BA_ "U_CD542_MY2021_Tx" SG_ 529 OnbChrgToPcWkdy_D_Actl 1;
BA_ "U_U55X_MY2022_Tx" SG_ 529 OnbChrgToPcWkdy_D_Actl 1;
BA_ "U_P702_MY2021_Tx" SG_ 529 OnbChrgToPcWkdy_D_Actl 1;
BA_ "U_T6_MCA_MY2020_Tx" SG_ 529 OnbChrgToPcWkdy_D_Actl 1;
BA_ "U_CD542_MY2021_Tx" SG_ 529 OnbChrgSetNow_D_Rq 1;
BA_ "U_U55X_MY2022_Tx" SG_ 529 OnbChrgSetNow_D_Rq 1;
BA_ "U_P702_MY2021_Tx" SG_ 529 OnbChrgSetNow_D_Rq 1;
BA_ "U_T6_MCA_MY2020_Tx" SG_ 529 OnbChrgSetNow_D_Rq 1;
BA_ "U_CD542_MY2021_Tx" SG_ 529 OnbChrgSetDelete_B_Rq 1;
BA_ "U_U55X_MY2022_Tx" SG_ 529 OnbChrgSetDelete_B_Rq 1;
BA_ "U_P702_MY2021_Tx" SG_ 529 OnbChrgSetDelete_B_Rq 1;
BA_ "U_T6_MCA_MY2020_Tx" SG_ 529 OnbChrgSetDelete_B_Rq 1;
BA_ "U_CD542_MY2021_Tx" SG_ 529 OnbChrgPrflWknd_No_Rq 1;
BA_ "U_U55X_MY2022_Tx" SG_ 529 OnbChrgPrflWknd_No_Rq 1;
BA_ "U_P702_MY2021_Tx" SG_ 529 OnbChrgPrflWknd_No_Rq 1;
BA_ "U_T6_MCA_MY2020_Tx" SG_ 529 OnbChrgPrflWknd_No_Rq 1;
BA_ "U_CD542_MY2021_Tx" SG_ 529 OnbChrgPrflWkdy_No_Rq 1;
BA_ "U_U55X_MY2022_Tx" SG_ 529 OnbChrgPrflWkdy_No_Rq 1;
BA_ "U_P702_MY2021_Tx" SG_ 529 OnbChrgPrflWkdy_No_Rq 1;
BA_ "U_T6_MCA_MY2020_Tx" SG_ 529 OnbChrgPrflWkdy_No_Rq 1;
BA_ "GenSigSendType" SG_ 529 OnbChrgPrflUpdate_B_Rq 3;
BA_ "U_T6_MCA_MY2020_Rx" SG_ 529 OnbChrgPrflUpdate_B_Rq 1;
BA_ "ECGUsedRxSignal" SG_ 529 OnbChrgPrflUpdate_B_Rq 1;
BA_ "U_CD542_MY2021_Rx" SG_ 529 OnbChrgPrflUpdate_B_Rq 1;
BA_ "U_U55X_MY2022_Rx" SG_ 529 OnbChrgPrflUpdate_B_Rq 1;
BA_ "U_CD764_MY2022_Rx" SG_ 529 OnbChrgPrflUpdate_B_Rq 1;
BA_ "U_CD542_MY2021_Tx" SG_ 529 OnbChrgPrflUpdate_B_Rq 1;
BA_ "U_U55X_MY2022_Tx" SG_ 529 OnbChrgPrflUpdate_B_Rq 1;
BA_ "U_P702_MY2021_Tx" SG_ 529 OnbChrgPrflUpdate_B_Rq 1;
BA_ "U_T6_MCA_MY2020_Tx" SG_ 529 OnbChrgPrflUpdate_B_Rq 1;
BA_ "U_CD542_MY2021_Tx" SG_ 529 OnbChrgLocIdUns_B_Rq 1;
BA_ "U_U55X_MY2022_Tx" SG_ 529 OnbChrgLocIdUns_B_Rq 1;
BA_ "U_P702_MY2021_Tx" SG_ 529 OnbChrgLocIdUns_B_Rq 1;
BA_ "U_T6_MCA_MY2020_Tx" SG_ 529 OnbChrgLocIdUns_B_Rq 1;
BA_ "GenSigSendType" SG_ 529 OnbChrgLocIdTrgt_No_Rq 3;
BA_ "U_P702_MY2021_Tx" SG_ 529 OnbChrgLocIdTrgt_No_Rq 1;
BA_ "U_T6_MCA_MY2020_Tx" SG_ 529 OnbChrgLocIdTrgt_No_Rq 1;
BA_ "U_CD542_MY2021_Tx" SG_ 529 OnbChrgLocIdTrgt_No_Rq 1;
BA_ "U_U55X_MY2022_Tx" SG_ 529 OnbChrgLocIdTrgt_No_Rq 1;
BA_ "U_T6_MCA_MY2020_Rx" SG_ 642 SldrrMsgTxt_D2_Rq_UB 1;
BA_ "U_CD542_MY2021_Rx" SG_ 642 SldrrMsgTxt_D2_Rq_UB 1;
BA_ "U_CD764_MY2022_Rx" SG_ 642 SldrrMsgTxt_D2_Rq_UB 1;
BA_ "WakeupSignal" SG_ 642 SldrrMsgTxt_D2_Rq 1;
BA_ "GenSigSendType" SG_ 642 SldrrMsgTxt_D2_Rq 3;
BA_ "U_T6_MCA_MY2020_Rx" SG_ 642 SldrrMsgTxt_D2_Rq 1;
BA_ "U_CD542_MY2021_Rx" SG_ 642 SldrrMsgTxt_D2_Rq 1;
BA_ "U_CD764_MY2022_Rx" SG_ 642 SldrrMsgTxt_D2_Rq 1;
BA_ "U_T6_MCA_MY2020_Rx" SG_ 642 SldrrChime_D_Rq_UB 1;
BA_ "U_CD542_MY2021_Rx" SG_ 642 SldrrChime_D_Rq_UB 1;
BA_ "U_CD764_MY2022_Rx" SG_ 642 SldrrChime_D_Rq_UB 1;
BA_ "WakeupSignal" SG_ 642 SldrrChime_D_Rq 1;
BA_ "GenSigSendType" SG_ 642 SldrrChime_D_Rq 3;
BA_ "U_T6_MCA_MY2020_Rx" SG_ 642 SldrrChime_D_Rq 1;
BA_ "U_CD542_MY2021_Rx" SG_ 642 SldrrChime_D_Rq 1;
BA_ "U_CD764_MY2022_Rx" SG_ 642 SldrrChime_D_Rq 1;
BA_ "U_T6_MCA_MY2020_Rx" SG_ 642 SldrlMsgTxt_D2_Rq_UB 1;
BA_ "U_CD542_MY2021_Rx" SG_ 642 SldrlMsgTxt_D2_Rq_UB 1;
BA_ "U_CD764_MY2022_Rx" SG_ 642 SldrlMsgTxt_D2_Rq_UB 1;
BA_ "WakeupSignal" SG_ 642 SldrlMsgTxt_D2_Rq 1;
BA_ "GenSigSendType" SG_ 642 SldrlMsgTxt_D2_Rq 3;
BA_ "U_T6_MCA_MY2020_Rx" SG_ 642 SldrlMsgTxt_D2_Rq 1;
BA_ "U_CD542_MY2021_Rx" SG_ 642 SldrlMsgTxt_D2_Rq 1;
BA_ "U_CD764_MY2022_Rx" SG_ 642 SldrlMsgTxt_D2_Rq 1;
BA_ "U_T6_MCA_MY2020_Rx" SG_ 642 SldrlChime_D_Rq_UB 1;
BA_ "U_CD542_MY2021_Rx" SG_ 642 SldrlChime_D_Rq_UB 1;
BA_ "U_CD764_MY2022_Rx" SG_ 642 SldrlChime_D_Rq_UB 1;
BA_ "WakeupSignal" SG_ 642 SldrlChime_D_Rq 1;
BA_ "GenSigSendType" SG_ 642 SldrlChime_D_Rq 3;
BA_ "U_T6_MCA_MY2020_Rx" SG_ 642 SldrlChime_D_Rq 1;
BA_ "U_CD542_MY2021_Rx" SG_ 642 SldrlChime_D_Rq 1;
BA_ "U_CD764_MY2022_Rx" SG_ 642 SldrlChime_D_Rq 1;
BA_ "U_P702_MY2021_Rx" SG_ 642 PaakMyKeySearch_D_Stat_UB 1;
BA_ "U_T6_MCA_MY2020_Rx" SG_ 642 PaakMyKeySearch_D_Stat_UB 1;
BA_ "U_U55X_MY2022_Rx" SG_ 642 PaakMyKeySearch_D_Stat_UB 1;
BA_ "U_CD542_MY2021_Rx" SG_ 642 PaakMyKeySearch_D_Stat_UB 1;
BA_ "U_P702_MY2021_Rx" SG_ 642 UreaLvlQlty_D_RqDsply_UB 1;
BA_ "U_T6_MCA_MY2020_Rx" SG_ 642 UreaLvlQlty_D_RqDsply_UB 1;
BA_ "U_CD542_MY2021_Rx" SG_ 642 UreaLvlQlty_D_RqDsply_UB 1;
BA_ "U_CD764_MY2022_Rx" SG_ 642 UreaLvlQlty_D_RqDsply_UB 1;
BA_ "U_T6_MCA_MY2020_Rx" SG_ 642 DieslPrtcWarn_D_Rq_UB 1;
BA_ "U_CD542_MY2021_Rx" SG_ 642 DieslPrtcWarn_D_Rq_UB 1;
BA_ "U_CD764_MY2022_Rx" SG_ 642 DieslPrtcWarn_D_Rq_UB 1;
BA_ "U_P702_MY2021_Rx" SG_ 642 UreaQltySysWarn_D_Rq_UB 1;
BA_ "U_T6_MCA_MY2020_Rx" SG_ 642 UreaQltySysWarn_D_Rq_UB 1;
BA_ "U_CD542_MY2021_Rx" SG_ 642 UreaQltySysWarn_D_Rq_UB 1;
BA_ "U_CD764_MY2022_Rx" SG_ 642 UreaQltySysWarn_D_Rq_UB 1;
BA_ "U_P702_MY2021_Rx" SG_ 642 UreaLvlTxtWarn_D_Rq_UB 1;
BA_ "U_T6_MCA_MY2020_Rx" SG_ 642 UreaLvlTxtWarn_D_Rq_UB 1;
BA_ "U_CD542_MY2021_Rx" SG_ 642 UreaLvlTxtWarn_D_Rq_UB 1;
BA_ "U_CD764_MY2022_Rx" SG_ 642 UreaLvlTxtWarn_D_Rq_UB 1;
BA_ "GenSigSendType" SG_ 642 UreaLvlQlty_D_RqDsply 3;
BA_ "U_P702_MY2021_Rx" SG_ 642 UreaLvlQlty_D_RqDsply 1;
BA_ "U_T6_MCA_MY2020_Rx" SG_ 642 UreaLvlQlty_D_RqDsply 1;
BA_ "U_CD542_MY2021_Rx" SG_ 642 UreaLvlQlty_D_RqDsply 1;
BA_ "U_CD764_MY2022_Rx" SG_ 642 UreaLvlQlty_D_RqDsply 1;
BA_ "GenSigSendType" SG_ 642 UreaLvlTxtWarn_D_Rq 3;
BA_ "U_P702_MY2021_Rx" SG_ 642 UreaLvlTxtWarn_D_Rq 1;
BA_ "U_T6_MCA_MY2020_Rx" SG_ 642 UreaLvlTxtWarn_D_Rq 1;
BA_ "U_CD542_MY2021_Rx" SG_ 642 UreaLvlTxtWarn_D_Rq 1;
BA_ "U_CD764_MY2022_Rx" SG_ 642 UreaLvlTxtWarn_D_Rq 1;
BA_ "GenSigSendType" SG_ 642 UreaQltySysWarn_D_Rq 3;
BA_ "U_P702_MY2021_Rx" SG_ 642 UreaQltySysWarn_D_Rq 1;
BA_ "U_T6_MCA_MY2020_Rx" SG_ 642 UreaQltySysWarn_D_Rq 1;
BA_ "U_CD542_MY2021_Rx" SG_ 642 UreaQltySysWarn_D_Rq 1;
BA_ "U_CD764_MY2022_Rx" SG_ 642 UreaQltySysWarn_D_Rq 1;
BA_ "GenSigSendType" SG_ 642 DieslPrtcWarn_D_Rq 3;
BA_ "U_T6_MCA_MY2020_Rx" SG_ 642 DieslPrtcWarn_D_Rq 1;
BA_ "U_CD542_MY2021_Rx" SG_ 642 DieslPrtcWarn_D_Rq 1;
BA_ "U_CD764_MY2022_Rx" SG_ 642 DieslPrtcWarn_D_Rq 1;
BA_ "U_P702_MY2021_Rx" SG_ 642 KeyMyKeyTot_No2_Cnt_UB 1;
BA_ "U_T6_MCA_MY2020_Rx" SG_ 642 KeyMyKeyTot_No2_Cnt_UB 1;
BA_ "U_CD542_MY2021_Rx" SG_ 642 KeyMyKeyTot_No2_Cnt_UB 1;
BA_ "U_U55X_MY2022_Rx" SG_ 642 KeyMyKeyTot_No2_Cnt_UB 1;
BA_ "U_P702_MY2021_Rx" SG_ 642 KeyAdmnTot_No2_Cnt_UB 1;
BA_ "U_T6_MCA_MY2020_Rx" SG_ 642 KeyAdmnTot_No2_Cnt_UB 1;
BA_ "U_CD542_MY2021_Rx" SG_ 642 KeyAdmnTot_No2_Cnt_UB 1;
BA_ "U_U55X_MY2022_Rx" SG_ 642 KeyAdmnTot_No2_Cnt_UB 1;
BA_ "U_P702_MY2021_Rx" SG_ 642 KeyMyKeyTot_No2_Cnt 1;
BA_ "U_T6_MCA_MY2020_Rx" SG_ 642 KeyMyKeyTot_No2_Cnt 1;
BA_ "U_U55X_MY2022_Rx" SG_ 642 KeyMyKeyTot_No2_Cnt 1;
BA_ "U_CD542_MY2021_Rx" SG_ 642 KeyMyKeyTot_No2_Cnt 1;
BA_ "U_P702_MY2021_Rx" SG_ 642 KeyAdmnTot_No2_Cnt 1;
BA_ "U_T6_MCA_MY2020_Rx" SG_ 642 KeyAdmnTot_No2_Cnt 1;
BA_ "U_CD542_MY2021_Rx" SG_ 642 KeyAdmnTot_No2_Cnt 1;
BA_ "U_U55X_MY2022_Rx" SG_ 642 KeyAdmnTot_No2_Cnt 1;
BA_ "U_T6_MCA_MY2020_Rx" SG_ 642 DcChrgSrvcRqd_B_Rq_UB 1;
BA_ "U_CD542_MY2021_Rx" SG_ 642 DcChrgSrvcRqd_B_Rq_UB 1;
BA_ "U_CD764_MY2022_Rx" SG_ 642 DcChrgSrvcRqd_B_Rq_UB 1;
BA_ "GenSigSendType" SG_ 642 DcChrgSrvcRqd_B_Rq 3;
BA_ "U_T6_MCA_MY2020_Rx" SG_ 642 DcChrgSrvcRqd_B_Rq 1;
BA_ "U_CD542_MY2021_Rx" SG_ 642 DcChrgSrvcRqd_B_Rq 1;
BA_ "U_CD764_MY2022_Rx" SG_ 642 DcChrgSrvcRqd_B_Rq 1;
BA_ "GenSigSendType" SG_ 642 PaakMyKeySearch_D_Stat 3;
BA_ "U_P702_MY2021_Rx" SG_ 642 PaakMyKeySearch_D_Stat 1;
BA_ "U_T6_MCA_MY2020_Rx" SG_ 642 PaakMyKeySearch_D_Stat 1;
BA_ "U_CD542_MY2021_Rx" SG_ 642 PaakMyKeySearch_D_Stat 1;
BA_ "U_U55X_MY2022_Rx" SG_ 642 PaakMyKeySearch_D_Stat 1;
BA_ "U_CD542_MY2021_Rx" SG_ 642 GrdAsstActv_B_Stat_UB 1;
BA_ "U_CD764_MY2022_Rx" SG_ 642 GrdAsstActv_B_Stat_UB 1;
BA_ "GenSigSendType" SG_ 642 GrdAsstActv_B_Stat 3;
BA_ "U_CD542_MY2021_Rx" SG_ 642 GrdAsstActv_B_Stat 1;
BA_ "U_CD764_MY2022_Rx" SG_ 642 GrdAsstActv_B_Stat 1;
BA_ "U_T6_MCA_MY2020_Rx" SG_ 642 TrlrAidTrlrId_No_Rq_UB 1;
BA_ "U_U55X_MY2022_Rx" SG_ 642 TrlrAidTrlrId_No_Rq_UB 1;
BA_ "U_CD542_MY2021_Rx" SG_ 642 TrlrAidTrlrId_No_Rq_UB 1;
BA_ "U_CD764_MY2022_Rx" SG_ 642 TrlrAidTrlrId_No_Rq_UB 1;
BA_ "GenSigSendType" SG_ 642 TrlrAidTrlrId_No_Rq 3;
BA_ "U_T6_MCA_MY2020_Rx" SG_ 642 TrlrAidTrlrId_No_Rq 1;
BA_ "U_U55X_MY2022_Rx" SG_ 642 TrlrAidTrlrId_No_Rq 1;
BA_ "U_CD542_MY2021_Rx" SG_ 642 TrlrAidTrlrId_No_Rq 1;
BA_ "U_CD764_MY2022_Rx" SG_ 642 TrlrAidTrlrId_No_Rq 1;
BA_ "U_CD542_MY2021_Rx" SG_ 893 RngPerChrgAvg_L2_Dsply_UB 1;
BA_ "U_U55X_MY2022_Rx" SG_ 893 RngPerChrgAvg_L2_Dsply_UB 1;
BA_ "U_T6_MCA_MY2020_Rx" SG_ 893 RngImpctClim_L_Dsply_UB 1;
BA_ "U_CD542_MY2021_Rx" SG_ 893 RngImpctClim_L_Dsply_UB 1;
BA_ "U_T6_MCA_MY2020_Rx" SG_ 893 RngImpctDrv_L_Dsply_UB 1;
BA_ "U_CD542_MY2021_Rx" SG_ 893 RngImpctDrv_L_Dsply_UB 1;
BA_ "GenSigStartValueInteger" SG_ 893 RngImpctDrv_L_Dsply 255;
BA_ "U_T6_MCA_MY2020_Rx" SG_ 893 RngImpctDrv_L_Dsply 1;
BA_ "U_CD542_MY2021_Rx" SG_ 893 RngImpctDrv_L_Dsply 1;
BA_ "GenSigStartValueInteger" SG_ 893 RngImpctClim_L_Dsply 255;
BA_ "U_T6_MCA_MY2020_Rx" SG_ 893 RngImpctClim_L_Dsply 1;
BA_ "U_CD542_MY2021_Rx" SG_ 893 RngImpctClim_L_Dsply 1;
BA_ "U_T6_MCA_MY2020_Rx" SG_ 893 VehElEffAvg_No_Dsply_UB 1;
BA_ "U_U55X_MY2022_Rx" SG_ 893 VehElEffAvg_No_Dsply_UB 1;
BA_ "U_CD542_MY2021_Rx" SG_ 893 VehElEffAvg_No_Dsply_UB 1;
BA_ "U_CD764_MY2022_Rx" SG_ 893 VehElEffAvg_No_Dsply_UB 1;
BA_ "GenSigStartValueInteger" SG_ 893 VehElEffAvg_No_Dsply 126;
BA_ "GenSigStartValue" SG_ 893 VehElEffAvg_No_Dsply 126;
BA_ "U_T6_MCA_MY2020_Rx" SG_ 893 VehElEffAvg_No_Dsply 1;
BA_ "U_U55X_MY2022_Rx" SG_ 893 VehElEffAvg_No_Dsply 1;
BA_ "U_CD542_MY2021_Rx" SG_ 893 VehElEffAvg_No_Dsply 1;
BA_ "U_CD764_MY2022_Rx" SG_ 893 VehElEffAvg_No_Dsply 1;
BA_ "GenSigStartValueInteger" SG_ 893 RngPerChrgAvg_L2_Dsply 4094;
BA_ "GenSigStartValue" SG_ 893 RngPerChrgAvg_L2_Dsply 8190;
BA_ "U_CD542_MY2021_Rx" SG_ 893 RngPerChrgAvg_L2_Dsply 1;
BA_ "U_U55X_MY2022_Rx" SG_ 893 RngPerChrgAvg_L2_Dsply 1;
BA_ "U_CD764_MY2022_Rx" SG_ 893 TrnAout2_W_ActlUnfilt_UB 1;
BA_ "GenSigStartValueInteger" SG_ 893 TrnAout2_W_ActlUnfilt 65534;
BA_ "GenSigStartValue" SG_ 893 TrnAout2_W_ActlUnfilt 65534;
BA_ "U_CD764_MY2022_Rx" SG_ 893 TrnAout2_W_ActlUnfilt 1;
BA_ "U_P702_MY2021_Rx" SG_ 500 Dsp_SourceSetTrack_Rq 1;
BA_ "U_T6_MCA_MY2020_Rx" SG_ 500 Dsp_SourceSetTrack_Rq 1;
BA_ "U_CD542_MY2021_Rx" SG_ 500 Dsp_SourceSetTrack_Rq 1;
BA_ "U_U55X_MY2022_Rx" SG_ 500 Dsp_SourceSetTrack_Rq 1;
BA_ "U_P702_MY2021_Tx" SG_ 500 Dsp_SourceSetTrack_Rq 1;
BA_ "U_T6_MCA_MY2020_Tx" SG_ 500 Dsp_SourceSetTrack_Rq 1;
BA_ "U_CD542_MY2021_Tx" SG_ 500 Dsp_SourceSetTrack_Rq 1;
BA_ "U_U55X_MY2022_Tx" SG_ 500 Dsp_SourceSetTrack_Rq 1;
BA_ "U_P702_MY2021_Rx" SG_ 500 Dsp_ItemNameLength_Rq 1;
BA_ "U_T6_MCA_MY2020_Rx" SG_ 500 Dsp_ItemNameLength_Rq 1;
BA_ "U_CD542_MY2021_Rx" SG_ 500 Dsp_ItemNameLength_Rq 1;
BA_ "U_U55X_MY2022_Rx" SG_ 500 Dsp_ItemNameLength_Rq 1;
BA_ "U_P702_MY2021_Tx" SG_ 500 Dsp_ItemNameLength_Rq 1;
BA_ "U_T6_MCA_MY2020_Tx" SG_ 500 Dsp_ItemNameLength_Rq 1;
BA_ "U_CD542_MY2021_Tx" SG_ 500 Dsp_ItemNameLength_Rq 1;
BA_ "U_U55X_MY2022_Tx" SG_ 500 Dsp_ItemNameLength_Rq 1;
BA_ "GenSigSendType" SG_ 500 Dsp_GetCDTOCDData_Rq 3;
BA_ "U_P702_MY2021_Rx" SG_ 500 Dsp_GetCDTOCDData_Rq 1;
BA_ "U_T6_MCA_MY2020_Rx" SG_ 500 Dsp_GetCDTOCDData_Rq 1;
BA_ "U_CD542_MY2021_Rx" SG_ 500 Dsp_GetCDTOCDData_Rq 1;
BA_ "U_U55X_MY2022_Rx" SG_ 500 Dsp_GetCDTOCDData_Rq 1;
BA_ "U_P702_MY2021_Tx" SG_ 500 Dsp_GetCDTOCDData_Rq 1;
BA_ "U_T6_MCA_MY2020_Tx" SG_ 500 Dsp_GetCDTOCDData_Rq 1;
BA_ "U_CD542_MY2021_Tx" SG_ 500 Dsp_GetCDTOCDData_Rq 1;
BA_ "U_U55X_MY2022_Tx" SG_ 500 Dsp_GetCDTOCDData_Rq 1;
BA_ "U_P702_MY2021_Rx" SG_ 500 Dsp_FolderNumber_Rq 1;
BA_ "U_T6_MCA_MY2020_Rx" SG_ 500 Dsp_FolderNumber_Rq 1;
BA_ "U_CD542_MY2021_Rx" SG_ 500 Dsp_FolderNumber_Rq 1;
BA_ "U_U55X_MY2022_Rx" SG_ 500 Dsp_FolderNumber_Rq 1;
BA_ "U_P702_MY2021_Tx" SG_ 500 Dsp_FolderNumber_Rq 1;
BA_ "U_T6_MCA_MY2020_Tx" SG_ 500 Dsp_FolderNumber_Rq 1;
BA_ "U_CD542_MY2021_Tx" SG_ 500 Dsp_FolderNumber_Rq 1;
BA_ "U_U55X_MY2022_Tx" SG_ 500 Dsp_FolderNumber_Rq 1;
BA_ "U_P702_MY2021_Rx" SG_ 500 Dsp_CutItem_Rq 1;
BA_ "U_T6_MCA_MY2020_Rx" SG_ 500 Dsp_CutItem_Rq 1;
BA_ "U_CD542_MY2021_Rx" SG_ 500 Dsp_CutItem_Rq 1;
BA_ "U_U55X_MY2022_Rx" SG_ 500 Dsp_CutItem_Rq 1;
BA_ "U_P702_MY2021_Tx" SG_ 500 Dsp_CutItem_Rq 1;
BA_ "U_T6_MCA_MY2020_Tx" SG_ 500 Dsp_CutItem_Rq 1;
BA_ "U_CD542_MY2021_Tx" SG_ 500 Dsp_CutItem_Rq 1;
BA_ "U_U55X_MY2022_Tx" SG_ 500 Dsp_CutItem_Rq 1;
BA_ "GenSigSendType" SG_ 500 Dsp_AudioSourceSel_Rq 3;
BA_ "U_P702_MY2021_Rx" SG_ 500 Dsp_AudioSourceSel_Rq 1;
BA_ "U_T6_MCA_MY2020_Rx" SG_ 500 Dsp_AudioSourceSel_Rq 1;
BA_ "U_CD542_MY2021_Rx" SG_ 500 Dsp_AudioSourceSel_Rq 1;
BA_ "U_U55X_MY2022_Rx" SG_ 500 Dsp_AudioSourceSel_Rq 1;
BA_ "U_P702_MY2021_Tx" SG_ 500 Dsp_AudioSourceSel_Rq 1;
BA_ "U_T6_MCA_MY2020_Tx" SG_ 500 Dsp_AudioSourceSel_Rq 1;
BA_ "U_CD542_MY2021_Tx" SG_ 500 Dsp_AudioSourceSel_Rq 1;
BA_ "U_U55X_MY2022_Tx" SG_ 500 Dsp_AudioSourceSel_Rq 1;
BA_ "U_P702_MY2021_Rx" SG_ 503 Dsp_PlayFrstTrInFldr_Rq 1;
BA_ "U_T6_MCA_MY2020_Rx" SG_ 503 Dsp_PlayFrstTrInFldr_Rq 1;
BA_ "U_CD542_MY2021_Rx" SG_ 503 Dsp_PlayFrstTrInFldr_Rq 1;
BA_ "U_U55X_MY2022_Rx" SG_ 503 Dsp_PlayFrstTrInFldr_Rq 1;
BA_ "U_P702_MY2021_Tx" SG_ 503 Dsp_PlayFrstTrInFldr_Rq 1;
BA_ "U_T6_MCA_MY2020_Tx" SG_ 503 Dsp_PlayFrstTrInFldr_Rq 1;
BA_ "U_CD542_MY2021_Tx" SG_ 503 Dsp_PlayFrstTrInFldr_Rq 1;
BA_ "U_U55X_MY2022_Tx" SG_ 503 Dsp_PlayFrstTrInFldr_Rq 1;
BA_ "U_P702_MY2021_Rx" SG_ 503 Dsp_ItemIndex_Rq 1;
BA_ "U_T6_MCA_MY2020_Rx" SG_ 503 Dsp_ItemIndex_Rq 1;
BA_ "U_CD542_MY2021_Rx" SG_ 503 Dsp_ItemIndex_Rq 1;
BA_ "U_U55X_MY2022_Rx" SG_ 503 Dsp_ItemIndex_Rq 1;
BA_ "U_P702_MY2021_Tx" SG_ 503 Dsp_ItemIndex_Rq 1;
BA_ "U_T6_MCA_MY2020_Tx" SG_ 503 Dsp_ItemIndex_Rq 1;
BA_ "U_CD542_MY2021_Tx" SG_ 503 Dsp_ItemIndex_Rq 1;
BA_ "U_U55X_MY2022_Tx" SG_ 503 Dsp_ItemIndex_Rq 1;
BA_ "U_P702_MY2021_Rx" SG_ 503 Dsp_FolderNumber3_Rq 1;
BA_ "U_T6_MCA_MY2020_Rx" SG_ 503 Dsp_FolderNumber3_Rq 1;
BA_ "U_CD542_MY2021_Rx" SG_ 503 Dsp_FolderNumber3_Rq 1;
BA_ "U_U55X_MY2022_Rx" SG_ 503 Dsp_FolderNumber3_Rq 1;
BA_ "U_P702_MY2021_Tx" SG_ 503 Dsp_FolderNumber3_Rq 1;
BA_ "U_T6_MCA_MY2020_Tx" SG_ 503 Dsp_FolderNumber3_Rq 1;
BA_ "U_CD542_MY2021_Tx" SG_ 503 Dsp_FolderNumber3_Rq 1;
BA_ "U_U55X_MY2022_Tx" SG_ 503 Dsp_FolderNumber3_Rq 1;
BA_ "GenSigSendType" SG_ 503 Dsp_AudioSourceSel3_Rq 3;
BA_ "U_P702_MY2021_Rx" SG_ 503 Dsp_AudioSourceSel3_Rq 1;
BA_ "U_T6_MCA_MY2020_Rx" SG_ 503 Dsp_AudioSourceSel3_Rq 1;
BA_ "U_CD542_MY2021_Rx" SG_ 503 Dsp_AudioSourceSel3_Rq 1;
BA_ "U_U55X_MY2022_Rx" SG_ 503 Dsp_AudioSourceSel3_Rq 1;
BA_ "U_P702_MY2021_Tx" SG_ 503 Dsp_AudioSourceSel3_Rq 1;
BA_ "U_T6_MCA_MY2020_Tx" SG_ 503 Dsp_AudioSourceSel3_Rq 1;
BA_ "U_CD542_MY2021_Tx" SG_ 503 Dsp_AudioSourceSel3_Rq 1;
BA_ "U_U55X_MY2022_Tx" SG_ 503 Dsp_AudioSourceSel3_Rq 1;
BA_ "U_P702_MY2021_Rx" SG_ 412 LBC2_StartItemInd 1;
BA_ "U_T6_MCA_MY2020_Rx" SG_ 412 LBC2_StartItemInd 1;
BA_ "U_CD542_MY2021_Rx" SG_ 412 LBC2_StartItemInd 1;
BA_ "U_U55X_MY2022_Rx" SG_ 412 LBC2_StartItemInd 1;
BA_ "U_P702_MY2021_Tx" SG_ 412 LBC2_StartItemInd 1;
BA_ "U_T6_MCA_MY2020_Tx" SG_ 412 LBC2_StartItemInd 1;
BA_ "U_CD542_MY2021_Tx" SG_ 412 LBC2_StartItemInd 1;
BA_ "U_U55X_MY2022_Tx" SG_ 412 LBC2_StartItemInd 1;
BA_ "U_P702_MY2021_Rx" SG_ 412 LBC2_SetListServ 1;
BA_ "U_T6_MCA_MY2020_Rx" SG_ 412 LBC2_SetListServ 1;
BA_ "U_CD542_MY2021_Rx" SG_ 412 LBC2_SetListServ 1;
BA_ "U_U55X_MY2022_Rx" SG_ 412 LBC2_SetListServ 1;
BA_ "U_P702_MY2021_Tx" SG_ 412 LBC2_SetListServ 1;
BA_ "U_T6_MCA_MY2020_Tx" SG_ 412 LBC2_SetListServ 1;
BA_ "U_CD542_MY2021_Tx" SG_ 412 LBC2_SetListServ 1;
BA_ "U_U55X_MY2022_Tx" SG_ 412 LBC2_SetListServ 1;
BA_ "GenSigSendType" SG_ 412 LBC2_Opcode 3;
BA_ "U_P702_MY2021_Rx" SG_ 412 LBC2_Opcode 1;
BA_ "U_T6_MCA_MY2020_Rx" SG_ 412 LBC2_Opcode 1;
BA_ "U_CD542_MY2021_Rx" SG_ 412 LBC2_Opcode 1;
BA_ "U_U55X_MY2022_Rx" SG_ 412 LBC2_Opcode 1;
BA_ "U_P702_MY2021_Tx" SG_ 412 LBC2_Opcode 1;
BA_ "U_T6_MCA_MY2020_Tx" SG_ 412 LBC2_Opcode 1;
BA_ "U_CD542_MY2021_Tx" SG_ 412 LBC2_Opcode 1;
BA_ "U_U55X_MY2022_Tx" SG_ 412 LBC2_Opcode 1;
BA_ "U_P702_MY2021_Rx" SG_ 412 LBC2_NbrOfItems 1;
BA_ "U_T6_MCA_MY2020_Rx" SG_ 412 LBC2_NbrOfItems 1;
BA_ "U_CD542_MY2021_Rx" SG_ 412 LBC2_NbrOfItems 1;
BA_ "U_U55X_MY2022_Rx" SG_ 412 LBC2_NbrOfItems 1;
BA_ "U_P702_MY2021_Tx" SG_ 412 LBC2_NbrOfItems 1;
BA_ "U_T6_MCA_MY2020_Tx" SG_ 412 LBC2_NbrOfItems 1;
BA_ "U_CD542_MY2021_Tx" SG_ 412 LBC2_NbrOfItems 1;
BA_ "U_U55X_MY2022_Tx" SG_ 412 LBC2_NbrOfItems 1;
BA_ "U_T6_MCA_MY2020_Rx" SG_ 412 LBC2_ItemIndex 1;
BA_ "U_CD542_MY2021_Rx" SG_ 412 LBC2_ItemIndex 1;
BA_ "U_U55X_MY2022_Rx" SG_ 412 LBC2_ItemIndex 1;
BA_ "U_P702_MY2021_Tx" SG_ 412 LBC2_ItemIndex 1;
BA_ "U_T6_MCA_MY2020_Tx" SG_ 412 LBC2_ItemIndex 1;
BA_ "U_CD542_MY2021_Tx" SG_ 412 LBC2_ItemIndex 1;
BA_ "U_U55X_MY2022_Tx" SG_ 412 LBC2_ItemIndex 1;
BA_ "U_P702_MY2021_Rx" SG_ 412 LBC2_ActiveListID 1;
BA_ "U_T6_MCA_MY2020_Rx" SG_ 412 LBC2_ActiveListID 1;
BA_ "U_CD542_MY2021_Rx" SG_ 412 LBC2_ActiveListID 1;
BA_ "U_U55X_MY2022_Rx" SG_ 412 LBC2_ActiveListID 1;
BA_ "U_P702_MY2021_Tx" SG_ 412 LBC2_ActiveListID 1;
BA_ "U_T6_MCA_MY2020_Tx" SG_ 412 LBC2_ActiveListID 1;
BA_ "U_CD542_MY2021_Tx" SG_ 412 LBC2_ActiveListID 1;
BA_ "U_U55X_MY2022_Tx" SG_ 412 LBC2_ActiveListID 1;
BA_ "GenSigSendType" SG_ 493 Dsp_StatLiScanCancel_Rq 3;
BA_ "U_P702_MY2021_Rx" SG_ 493 Dsp_StatLiScanCancel_Rq 1;
BA_ "U_T6_MCA_MY2020_Rx" SG_ 493 Dsp_StatLiScanCancel_Rq 1;
BA_ "U_CD542_MY2021_Rx" SG_ 493 Dsp_StatLiScanCancel_Rq 1;
BA_ "U_U55X_MY2022_Rx" SG_ 493 Dsp_StatLiScanCancel_Rq 1;
BA_ "U_P702_MY2021_Tx" SG_ 493 Dsp_StatLiScanCancel_Rq 1;
BA_ "U_T6_MCA_MY2020_Tx" SG_ 493 Dsp_StatLiScanCancel_Rq 1;
BA_ "U_CD542_MY2021_Tx" SG_ 493 Dsp_StatLiScanCancel_Rq 1;
BA_ "U_U55X_MY2022_Tx" SG_ 493 Dsp_StatLiScanCancel_Rq 1;
BA_ "GenSigSendType" SG_ 493 Dsp_StationList_Rq 3;
BA_ "U_P702_MY2021_Rx" SG_ 493 Dsp_StationList_Rq 1;
BA_ "U_T6_MCA_MY2020_Rx" SG_ 493 Dsp_StationList_Rq 1;
BA_ "U_CD542_MY2021_Rx" SG_ 493 Dsp_StationList_Rq 1;
BA_ "U_U55X_MY2022_Rx" SG_ 493 Dsp_StationList_Rq 1;
BA_ "U_P702_MY2021_Tx" SG_ 493 Dsp_StationList_Rq 1;
BA_ "U_T6_MCA_MY2020_Tx" SG_ 493 Dsp_StationList_Rq 1;
BA_ "U_CD542_MY2021_Tx" SG_ 493 Dsp_StationList_Rq 1;
BA_ "U_U55X_MY2022_Tx" SG_ 493 Dsp_StationList_Rq 1;
BA_ "U_P702_MY2021_Rx" SG_ 493 Dsp_StartIndex3_Rq 1;
BA_ "U_T6_MCA_MY2020_Rx" SG_ 493 Dsp_StartIndex3_Rq 1;
BA_ "U_CD542_MY2021_Rx" SG_ 493 Dsp_StartIndex3_Rq 1;
BA_ "U_U55X_MY2022_Rx" SG_ 493 Dsp_StartIndex3_Rq 1;
BA_ "U_P702_MY2021_Tx" SG_ 493 Dsp_StartIndex3_Rq 1;
BA_ "U_T6_MCA_MY2020_Tx" SG_ 493 Dsp_StartIndex3_Rq 1;
BA_ "U_CD542_MY2021_Tx" SG_ 493 Dsp_StartIndex3_Rq 1;
BA_ "U_U55X_MY2022_Tx" SG_ 493 Dsp_StartIndex3_Rq 1;
BA_ "U_P702_MY2021_Rx" SG_ 493 Dsp_RefreshFlag 1;
BA_ "U_T6_MCA_MY2020_Rx" SG_ 493 Dsp_RefreshFlag 1;
BA_ "U_CD542_MY2021_Rx" SG_ 493 Dsp_RefreshFlag 1;
BA_ "U_U55X_MY2022_Rx" SG_ 493 Dsp_RefreshFlag 1;
BA_ "U_P702_MY2021_Tx" SG_ 493 Dsp_RefreshFlag 1;
BA_ "U_T6_MCA_MY2020_Tx" SG_ 493 Dsp_RefreshFlag 1;
BA_ "U_CD542_MY2021_Tx" SG_ 493 Dsp_RefreshFlag 1;
BA_ "U_U55X_MY2022_Tx" SG_ 493 Dsp_RefreshFlag 1;
BA_ "U_P702_MY2021_Rx" SG_ 493 Dsp_PTYCode_Rq 1;
BA_ "U_T6_MCA_MY2020_Rx" SG_ 493 Dsp_PTYCode_Rq 1;
BA_ "U_CD542_MY2021_Rx" SG_ 493 Dsp_PTYCode_Rq 1;
BA_ "U_U55X_MY2022_Rx" SG_ 493 Dsp_PTYCode_Rq 1;
BA_ "U_P702_MY2021_Tx" SG_ 493 Dsp_PTYCode_Rq 1;
BA_ "U_T6_MCA_MY2020_Tx" SG_ 493 Dsp_PTYCode_Rq 1;
BA_ "U_CD542_MY2021_Tx" SG_ 493 Dsp_PTYCode_Rq 1;
BA_ "U_U55X_MY2022_Tx" SG_ 493 Dsp_PTYCode_Rq 1;
BA_ "U_P702_MY2021_Rx" SG_ 493 Dsp_ListSize_Rq 1;
BA_ "U_T6_MCA_MY2020_Rx" SG_ 493 Dsp_ListSize_Rq 1;
BA_ "U_CD542_MY2021_Rx" SG_ 493 Dsp_ListSize_Rq 1;
BA_ "U_U55X_MY2022_Rx" SG_ 493 Dsp_ListSize_Rq 1;
BA_ "U_P702_MY2021_Tx" SG_ 493 Dsp_ListSize_Rq 1;
BA_ "U_T6_MCA_MY2020_Tx" SG_ 493 Dsp_ListSize_Rq 1;
BA_ "U_CD542_MY2021_Tx" SG_ 493 Dsp_ListSize_Rq 1;
BA_ "U_U55X_MY2022_Tx" SG_ 493 Dsp_ListSize_Rq 1;
BA_ "GenSigSendType" SG_ 493 Dsp_AFJump_Rq 3;
BA_ "U_P702_MY2021_Rx" SG_ 493 Dsp_AFJump_Rq 1;
BA_ "U_T6_MCA_MY2020_Rx" SG_ 493 Dsp_AFJump_Rq 1;
BA_ "U_CD542_MY2021_Rx" SG_ 493 Dsp_AFJump_Rq 1;
BA_ "U_U55X_MY2022_Rx" SG_ 493 Dsp_AFJump_Rq 1;
BA_ "U_P702_MY2021_Tx" SG_ 493 Dsp_AFJump_Rq 1;
BA_ "U_T6_MCA_MY2020_Tx" SG_ 493 Dsp_AFJump_Rq 1;
BA_ "U_CD542_MY2021_Tx" SG_ 493 Dsp_AFJump_Rq 1;
BA_ "U_U55X_MY2022_Tx" SG_ 493 Dsp_AFJump_Rq 1;
VAL_ 508 Mc_DB1GtInfNbrOfItms_Rq 1 "OneItem" 0 "Standard" ;
VAL_ 508 Mc_DB1GetInfSetConf_Rq 31 "UnknownActive" 30 "Reserved_last" 9 "Reserved" 8 "Podcast" 7 "Audiobook" 6 "Composer" 5 "Track" 4 "Genre" 3 "Album" 2 "Artist" 1 "Playlist" 0 "Root" ;
VAL_ 508 Mc_DB1GetInfSetFilt3_Rq 1023 "All" 1022 "SIIndex_1022" 1 "SIIndex_1" 0 "NotEngaged" ;
VAL_ 508 Mc_DB1GetInfSetFilt2_Rq 65535 "All" 65534 "SIIndex_65534" 1 "SIIndex_1" 0 "NotEngaged" ;
VAL_ 508 Mc_DB1GetInfSetFilt1_Rq 65535 "All" 65534 "SIIndex_65534" 1 "SIIndex_1" 0 "NotEngaged" ;
VAL_ 507 Mc_DB1SetTrkSetConf_Rq 9 "Reserved" 8 "Podcast" 7 "Audiobook" 6 "Composer" 5 "Track" 4 "Genre" 3 "Album" 2 "Artist" 1 "Playlist" 0 "Root" 31 "UnknownActive" 30 "Reserved_last" ;
VAL_ 507 Mc_DB1SetTrkSetFilt3_Rq 1023 "All" 1022 "SIIndex_1022" 1 "SIIndex_1" 0 "NotEngaged" ;
VAL_ 507 Mc_DB1SetTrkSetFilt2_Rq 65535 "All" 65534 "SIIndex_65534" 1 "SIIndex_1" 0 "NotEngaged" ;
VAL_ 507 Mc_DB1SetTrkSetFilt1_Rq 65535 "All" 65534 "SIIndex_65534" 1 "SIIndex_1" 0 "NotEngaged" ;
VAL_ 506 Mc_AudioSourceSel3_Rq 4 "Reserved" 5 "SDcard" 3 "USB" 2 "BTAudio" 1 "CD" 0 "Inactive" ;
VAL_ 505 Mc_AudioSourceSel2_Rq 4 "Reserved" 5 "SDcard" 3 "USB" 2 "BTAudio" 1 "CD" 0 "Inactive" ;
VAL_ 505 Mc_CutItem2_Rq 3 "Inactive" 2 "ThreeQuarterFromBeginOneQ" 1 "End" 0 "Beginning" ;
VAL_ 505 Mc_FolderContent_Rq 2 "Inactive" 1 "ReqContentParentFolderOf" 0 "ReqContentParameterFolder" ;
VAL_ 504 Mc_AudioSourceSel_Rq 4 "Reserved" 5 "SDcard" 3 "USB" 2 "BTAudio" 1 "CD" 0 "Inactive" ;
VAL_ 504 Mc_CutItem_Rq 3 "Inactive" 2 "ThreeQuarterFromBeginOneQ" 1 "End" 0 "Beginning" ;
VAL_ 140 DcacPwResetBttn_D_Stat 3 "NotUsed" 2 "Stuck" 1 "Pressed" 0 "Not_Pressed" ;
VAL_ 140 CcAslButtnIndxIncPress2 1 "Button_Pressed" 0 "Button_Not_Pressed" ;
VAL_ 140 SteWhlSwtchMde_D_Stat 3 "NotUsed_2" 2 "NotUsed_1" 1 "Dialog" 0 "Domain" ;
VAL_ 140 CcAslButtnOffCnclPress2 1 "Button_Pressed" 0 "Button_Not_Pressed" ;
VAL_ 140 CcAslButtnIndxDecPress2 1 "Button_Pressed" 0 "Button_Not_Pressed" ;
VAL_ 140 CcAslButtnCnclResPress2 1 "Button_Pressed" 0 "Button_Not_Pressed" ;
VAL_ 140 CcAslButtnResIncPress3 1 "Pressed" 0 "Not pressed" ;
VAL_ 140 CcButtnOnPress3 1 "Pressed" 0 "Not pressed" ;
VAL_ 140 CcButtnOnOffPress3 1 "Pressed" 0 "Not pressed" ;
VAL_ 140 CcButtnOnOffCnclPress3 1 "Pressed" 0 "Not pressed" ;
VAL_ 140 CcButtnOffPress3 1 "Pressed" 0 "Not pressed" ;
VAL_ 140 CcAsllButtnResPress3 1 "Pressed" 0 "Not pressed" ;
VAL_ 140 CcAslButtnSetPress3 1 "Pressed" 0 "Not pressed" ;
VAL_ 140 CcAslButtnSetIncPress3 1 "Pressed" 0 "Not pressed" ;
VAL_ 140 CcAslButtnSetDecPress3 1 "Pressed" 0 "Not pressed" ;
VAL_ 140 CcAslButtnResDecPress3 1 "Pressed" 0 "Not pressed" ;
VAL_ 140 CcAslButtnOnPress3 1 "Pressed" 0 "Not pressed" ;
VAL_ 140 CcAslButtnOnOffCncl3 1 "Pressed" 0 "Not pressed" ;
VAL_ 140 CcAslButtnDeny_B_Actl3 1 "Pressed" 0 "Not pressed" ;
VAL_ 140 CcAslButtnCnclPress3 1 "Pressed" 0 "Not pressed" ;
VAL_ 140 AslButtnOnOffPress3 1 "Pressed" 0 "Not pressed" ;
VAL_ 140 AslButtnOnOffCnclPress2 1 "Pressed" 0 "Not pressed" ;
VAL_ 813 TimerTripCurnt_T_Dsply 0 "0 second" ;
VAL_ 647 HEC_BTIncomingCall_Rq 0 "Inactive" 1 "AcceptIncomingCall" 2 "DeclineIncomingCall" ;
VAL_ 647 HEC_BTEndTelService_Rq 1 "EndOngoingTelephonyCall" 0 "Inactive" ;
VAL_ 497 McEvntNotfnMsgId_D_Rq 3 "Deactivate" 2 "Update" 1 "Activate" 0 "Invalid" ;
VAL_ 497 McEvntNotfnChoice_D_Rq 7 "Choice7" 6 "Choice6" 5 "Choice5" 4 "Choice4" 3 "Choice3" 2 "Choice2" 1 "Choice1" 0 "Ok" ;
VAL_ 400 Mc_SetCurrStatMCCh_Rq 7 "MCChannel7" 6 "MCChannel6" 5 "MCChannel5" 4 "MCChannel4" 3 "MCChannel3" 2 "MCChannel2" 1 "MCChannel1" 0 "Inactive" ;
VAL_ 400 Mc_SetCurrentStatOp_Rq 0 "Inactive" 1 "SetCurrentFrequency" 2 "SetCurrentPiCode" 3 "SetCurrentStation" ;
VAL_ 400 Mc_PerTUPresetArea_Rq 13 "reserved" 12 "GetSAT3PresetData" 11 "GetSAT2PresetData" 15 "reserved_last" 10 "GetSAT1PresetData" 9 "GetDAB2PresetData" 8 "GetDAB1PresetData" 7 "GetDAB3PresetData" 6 "GetAmPresetData" 5 "GetAmAstPresetData" 4 "GetFmAstPresetData" 3 "GetFm3PresetData" 2 "GetFm2PresetData" 1 "GetFm1PresetData" 0 "Inactive" ;
VAL_ 867 Front_Blower_Ind 15 "Display_Blank" 14 "14_Indicators_On" 13 "13_Indicators_On" 12 "12_Indicators_On" 11 "11_Indicators_On" 10 "10_Indicators_On" 9 "9_Indicators_On" 8 "8_Indicators_On" 7 "7_Indicators_On" 6 "6_Indicators_On" 5 "5_Indicators_On" 4 "4_Indicators_On" 3 "3_Indicators_On" 2 "2_Indicators_On" 1 "1_Indicator_On" 0 "Indicators_Off" ;
VAL_ 867 LHS_Temp_Disp_Digit3 2 "_5" 1 "_0" 0 "OFF" ;
VAL_ 867 EATC_LHS_Unit 2 "Fahrenheit" 1 "Celsius" 0 "Off" ;
VAL_ 831 RearDriverWindowPos 7 "Unused2" 6 "Unused1" 5 "Fully_Open" 4 "Bet60Percent_FullyOpen" 3 "Bet10Percent_60Percent" 2 "BetFully_10PercentOpen" 1 "Fully_Closed" 0 "Undefined" ;
VAL_ 831 DriverWindowPosition 7 "Unused2" 6 "Unused1" 5 "Fully_Open" 4 "Bet60Percent_FullyOpen" 3 "Bet10Percent_60Percent" 2 "BetFully_10PercentOpen" 1 "Fully_Closed" 0 "Undefined" ;
VAL_ 862 HvacBlwrFront_D_Stat 31 "Not_Used" 20 "Full_On" 19 "95_Percent" 18 "90_Percent" 17 "85_Percent" 16 "80_Percent" 15 "75_Percent" 14 "70_Percent" 13 "65_Percent" 12 "60_Percent" 11 "55_Percent" 10 "50_Percent" 9 "45_Percent" 8 "40_Percent" 7 "35_Percent" 6 "30_Percent" 5 "25_Percent" 4 "20_Percent" 3 "15_Percent" 2 "10_Percent" 1 "5_Percent" 0 "Off" ;
VAL_ 862 CabnAmb_Te_Actl 255 "Fault" ;
VAL_ 828 RearPassWindowPos 7 "Unused2" 6 "Unused1" 5 "Fully_Open" 4 "Bet60Percent_FullyOpen" 3 "Bet10Percent_60Percent" 2 "BetFully_10PercentOpen" 1 "Fully_Closed" 0 "Undefined" ;
VAL_ 828 PassWindowPosition 7 "Unused2" 6 "Unused1" 5 "Fully_Open" 4 "Bet60Percent_FullyOpen" 3 "Bet10Percent_60Percent" 2 "BetFully_10PercentOpen" 1 "Fully_Closed" 0 "Undefined" ;
VAL_ 1040 ElCmpr2Enbl_B_Rq 1 "Enable" 0 "Disable" ;
VAL_ 1040 ElCmprEnbl_B_Rq 1 "Enable" 0 "Disable" ;
VAL_ 1040 BattTrac_I2_EstVsc 262143 "Faulty" 262142 "NoDataExists" ;
VAL_ 528 TireInflateMsgTxt_B_Rq 1 "Yes" 0 "No" ;
VAL_ 528 OffRoadMde_D_Stat 7 "NotUsed_5" 6 "NotUsed_4" 5 "NotUsed_3" 4 "NotUsed_2" 3 "NotUsed_1" 2 "Off_Road2" 1 "Off_Road1" 0 "On_Road" ;
VAL_ 1221 BattTracUMxArry_No_Actl 31 "Faulty" ;
VAL_ 1221 BattTracCellUMx_No_Actl 255 "Faulty" 254 "NoDataExists" ;
VAL_ 1221 BattChrgUMx_B_Falt 1 "Yes" 0 "No" ;
VAL_ 1221 BattTracCellUMn_No_Actl 255 "Faulty" 254 "NoDataExists" ;
VAL_ 1221 BattTracCellCnt_No_Actl 255 "Faulty" 254 "NoDataExists" ;
VAL_ 1221 BattChrgIsltn_B_Falt 1 "Yes" 0 "No" ;
VAL_ 1221 BattTracCellDiff_B_Falt 1 "Yes" 0 "No" ;
VAL_ 1221 BattChrgSocMx_B_Falt 1 "Yes" 0 "No" ;
VAL_ 1221 BattChrgSocMn_B_Falt 1 "Yes" 0 "No" ;
VAL_ 1221 BattChrgSocErrtc_B_Falt 1 "Yes" 0 "No" ;
VAL_ 1221 BattTracUMx_B_Falt 1 "Yes" 0 "No" ;
VAL_ 1221 BattTracUMn_B_Falt 1 "Yes" 0 "No" ;
VAL_ 1221 BattTracTeMx_No_Actl 255 "Faulty" 254 "NoDataExists" ;
VAL_ 1221 BattTracTeMx_B_Falt 1 "Yes" 0 "No" ;
VAL_ 1221 BattTracTeMn_No_Actl 255 "Faulty" 254 "NoDataExists" ;
VAL_ 1221 BattTracTeDelta_B_Falt 1 "Yes" 0 "No" ;
VAL_ 1221 BattTracTeCnt_No_Actl 255 "Faulty" 254 "NoDataExists" ;
VAL_ 1221 BattTracSoftware_B_Falt 1 "Yes" 0 "No" ;
VAL_ 595 DrvIdMde_D_Rq 7 "Faulty" 6 "NotUsed_2" 5 "NotUsed_1" 4 "DeleteMid" 3 "ClearAll" 2 "Enroll" 1 "Recognize" 0 "Disable" ;
VAL_ 772 SeatRelxPosActv_B_Stat 1 "Success" 0 "Fail" ;
VAL_ 772 SeatRelxPosSet_B_Stat 1 "Success" 0 "Fail" ;
VAL_ 772 SeatRelxPosDact_B_Stat 1 "Success" 0 "Fail" ;
VAL_ 772 SeatScrnDrvOn_B_Rq 1 "On" 0 "Off" ;
VAL_ 772 PwRnngBoardT_D_Stat 3 "NotUsed" 2 "Timer2" 1 "Timer1" 0 "Inactive" ;
VAL_ 772 PwRnngBoardSwtch_D_Stat 3 "NotUsed" 2 "DeployUnlocked" 1 "AlwaysActive" 0 "Inactive" ;
VAL_ 772 SeatSlprPosMsgTxt_B_Rq 1 "On" 0 "Off" ;
VAL_ 772 SeatPos_D_Stat 7 "NotUsed3" 6 "NotUsed2" 5 "Error" 4 "Drive" 3 "Moving" 2 "Pending" 1 "EasyEntry" 0 "Null" ;
VAL_ 772 MemDrvDeny_B_Stat 1 "Yes" 0 "No" ;
VAL_ 772 SeatSlprPosPsngr_D_Stat 3 "Faulty" 2 "Sleeper" 1 "Upright" 0 "Null" ;
VAL_ 772 Memory_Feedback_Rqst 1 "Yes" 0 "No" ;
VAL_ 772 Easy_Entry_Rqst 2 "Easy_Entry" 1 "Drive" 0 "Null" ;
VAL_ 772 Memory_Cmd 7 "Recall_3" 4 "Store_4" 3 "Store_3" 6 "Recall_2" 5 "Recall_1" 2 "Store_2" 1 "Store_1" 0 "Null" 8 "Recall_4" ;
VAL_ 772 Cancel_Auto_Movement 1 "Cancel" 0 "Null" ;
VAL_ 826 Memory_3_Sw_Stat 1 "Pressed" 0 "Null" ;
VAL_ 826 Memory_2_Sw_Stat 1 "Pressed" 0 "Null" ;
VAL_ 826 Memory_1_Sw_Stat 1 "Pressed" 0 "Null" ;
VAL_ 826 Mirror_Manual_Override 1 "Override" 0 "Null" ;
VAL_ 966 PwTrnkFrontRleas_D_Src 15 "NotUsed_5" 14 "NotUsed_4" 13 "NotUsed_3" 12 "NotUsed_2" 11 "NotUsed_1" 10 "SelfTest" 9 "Diagnostics" 8 "EmergencyReleaseSwitch" 7 "ManualCinch" 6 "ExteriorSwitch" 5 "IpSwitch" 4 "Cpp" 3 "Sync" 2 "Keypad" 1 "Remote" 0 "PowerOff" ;
VAL_ 966 TrnkFrontScnd_B_Falt 1 "Fault" 0 "No_Fault" ;
VAL_ 966 TrnkFrontInhbt_B_Stat 1 "Inhibit" 0 "NoInhibit" ;
VAL_ 966 ExtLghtRear_D_RqBody 3 "NotUsed" 2 "On" 1 "Off" 0 "Null" ;
VAL_ 966 TrnkFrontRleas_D_Src 7 "NotUsed_3" 6 "NotUsed_2" 5 "NotUsed_1" 4 "Cpp" 3 "Sync" 2 "Keypad" 1 "Remote" 0 "Null" ;
VAL_ 773 StmsScrnPsngrOn_B_Rq 1 "On" 0 "Off" ;
VAL_ 773 SeatScrnPsngrOn_B_Rq 1 "On" 0 "Off" ;
VAL_ 773 SeatPsngrMem_D_Cmd 15 "NotUsed_7" 14 "NotUsed_6" 13 "NotUsed_5" 12 "NotUsed_4" 11 "NotUsed_3" 10 "NotUsed_2" 9 "NotUsed_1" 8 "RECALL_4" 7 "RECALL_3" 6 "RECALL_2" 5 "RECALL_1" 4 "STORE_4" 3 "STORE_3" 2 "STORE_2" 1 "STORE_1" 0 "Null" ;
VAL_ 773 MemSwtchPsngrFdbck_B_Rq 1 "Yes" 0 "No" ;
VAL_ 303 DrStatHood_D2_Actl 5 "NotUsed_2" 4 "NotUsed_1" 3 "Disabled" 2 "Ajar" 1 "Closed" 0 "NotDetermined" 7 "Faulty" 6 "NotUsed_3" ;
VAL_ 746 Con_BTAud_Shuffle_St 3 "OnTheFolderSelGroup" 2 "OnTheDevice" 1 "Off" 0 "Invalid" ;
VAL_ 746 Con_BTAud_Repeat_St 7 "Reserved3" 6 "Reserved2" 5 "Reserved1" 4 "RepeatOnDevice" 3 "RepeatOnFolder" 2 "RepeatOnTrack" 1 "Off" 0 "Invalid" ;
VAL_ 746 Con_BTAud_IntroScan_St 3 "OnTheFolderSelGroup" 2 "OnTheDevice" 1 "Off" 0 "Invalid" ;
VAL_ 746 Con_BTAud_Error_St 8 "NoDataInFolder" 7 "NoRespFromDevice" 6 "UnableToRead" 5 "NoDataOnDevice" 4 "FileSysNotSupported" 3 "DeviceNotSupported" 2 "InvalidFile" 1 "NoError" 0 "Invalid" ;
VAL_ 746 Con_BTAud_FunctStats_St 7 "Reserved2" 6 "Reserved1" 5 "Reserved" 4 "Reading" 3 "Ready" 2 "Initilization" 1 "Free" 0 "Invalid" ;
VAL_ 746 Con_BTAud_OpMode_St 7 "FastRewind20" 6 "FastRewind10" 5 "FastForward20" 4 "FastForward10" 3 "Pause" 2 "Play" 1 "Stop" 0 "Invalid" ;
VAL_ 479 DISP_SetVol_Source_Rq 5 "SetAudioVolume" 4 "SetVRvolume" 3 "SetPhoneVolume" 2 "SetPromptVolume" 1 "SetTAVolume" 0 "Inactive" ;
VAL_ 479 DISP_Setshaker_Rq 2 "On" 1 "Off" 0 "Inactive" ;
VAL_ 474 Nav_SetCurrStatMCCh_Rq 7 "MCChannel7" 6 "MCChannel6" 5 "MCChannel5" 4 "MCChannel4" 3 "MCChannel3" 2 "MCChannel2" 1 "MCChannel1" 0 "Inactive" ;
VAL_ 474 NAV_SetNEWSMode_Rq 0 "Inactive" 1 "NewsOn" 2 "NewsOff" ;
VAL_ 474 NAV_SetDSP_Rq 9 "Convertible" 8 "RearSeats" 7 "FrontSeats" 6 "Reserved3" 5 "Reserved2" 4 "Reserved1" 15 "Reserved" 0 "Inactive" 1 "All" 2 "Driver" 3 "Passenger" ;
VAL_ 474 NAV_SetCurrentStatOp_Rq 0 "Inactive" 1 "SetCurrentFrequency" 2 "SetCurrentPiCode" 3 "SetCurrentStation" ;
VAL_ 474 NAV_ARReqstrSystem_Rq 0 "FrontRequester" 1 "RearRequester" ;
VAL_ 474 NAV_ARReqstrPriority_Rq 0 "EmergencyServ" 1 "TelService" 2 "AutoAnswer" 3 "Ta" 4 "PttMutevoice" 5 "NavUserVoiceCmd" 6 "NavSysVoiceCmd" 7 "Radio" 8 "Disc" 9 "Alarm" 10 "Ptynews" 11 "Aux_ExtSource" 12 "BT_BTNavAndTelMute" 13 "ManualAudioMute" 14 "NotReq" ;
VAL_ 474 NAV_AROperationType_Rq 0 "Inactive" 1 "Requestaudioresource" 2 "Releaseaudioresource" 3 "Releaseallaudioresouces" 4 "Getresourceupdate" 5 "Getallresourceupdates" ;
VAL_ 474 NAV_ARAudioSource_Rq 15 "iPod" 14 "USB" 13 "BTAudio" 0 "AmfmRadio" 1 "FrontDisc" 2 "SDARS_DAB" 3 "InDashCdChanger" 4 "VoiceRecogniser" 5 "TelematicUnit" 6 "BluetoothPhone" 7 "RearDisc" 8 "APIM" 9 "FrontAuxInput" 10 "Navigation" 11 "RearAux" 12 "NotReq" ;
VAL_ 477 NAV_LoadEjectMode_Rq 0 "Inactive" 1 "Load" 2 "Eject" 3 "EndloadMode" ;
VAL_ 477 NAV_LoadEjectDisc_Rq 0 "Inactive" 1 "Disc1" 2 "Disc2" 3 "Disc3" 4 "Disc4" 5 "Disc5" 6 "Disc6" 7 "All" ;
VAL_ 260 MFD_SDARS_SetOpMode_Rq 7 "FastRewindSpeed2" 6 "FastRewindSpeed1" 5 "FastForwardSpeed2" 4 "FastForwardSpeed1" 3 "Pause" 2 "Play" 1 "Stop" 0 "Invalid" ;
VAL_ 260 SDARS_GetESN_Rq 1 "RequestESN" 0 "Invalid" ;
VAL_ 260 SDARS_SRReplay_Rq 2 "Disable" 1 "Enable" 0 "Inactive" ;
VAL_ 260 SDARS_FactoryReset_Rq 1 "ResetFactoryDefaults" 0 "Invalid" ;
VAL_ 476 Nav_SetAudioMixRatio_Rq 31 "Inactive" ;
VAL_ 476 NAV_SkipCatalouge_Rq 0 "Inactive" 1 "NextCatalouge" 2 "PerviousCatalouge" ;
VAL_ 476 NAV_SetOperationMode_Rq 7 "FastRewind20" 6 "FastRewind10" 5 "FastForward20" 4 "FastForward10" 3 "Pause" 2 "Play" 1 "Stop" 0 "Inactive" ;
VAL_ 476 NAV_SetDSPProgram_Rq 7 "Reserved2" 6 "Reserved1" 5 "Voice" 4 "Rock" 0 "Inactive" 1 "Normal" 2 "Pop" 3 "Classical" ;
VAL_ 490 HMI_SetCompression_Rq 0 "Inactive" 1 "On" 2 "Off" 3 "NotUsed" ;
VAL_ 490 HMI_SkipTrack_Rq 3 "NotUsed" 2 "Decrement" 1 "Increment" 0 "Inactive" ;
VAL_ 1245 RearDiffLckLamp_D_Cstm 3 "Not_Used" 2 "Flash" 1 "On" 0 "Off" ;
VAL_ 1245 FrontDiffLckLamp_D_Cstm 3 "Fast_Flash" 2 "Slow_Flash" 1 "On" 0 "Off" ;
VAL_ 1245 AwdMdeCstm_D_RqDrv 7 "Faulty" 6 "NotUsed_3" 5 "NotUsed_2" 4 "NotUsed_1" 3 "FourByFourLow" 2 "FourByFourHigh" 1 "FourByFourAuto" 0 "FourByTwo" ;
VAL_ 1245 SelDrvMdeAwd2_D_Cstm 31 "Faulty" 30 "NotUsed_17" 29 "NotUsed_16" 28 "NotUsed_15" 27 "NotUsed_14" 26 "NotUsed_13" 25 "NotUsed_12" 24 "NotUsed_11" 23 "NotUsed_10" 22 "NotUsed_9" 21 "NotUsed_8" 20 "CustomMode" 19 "OnePedalDrive" 18 "DragMode" 17 "EvLaterChargeMode" 16 "EvNowMode" 15 "TrackMode" 14 "RoughRoadMode" 13 "NotAvailable" 12 "HighSpeedDesertMode_Baja" 11 "SportAdaptiveMode" 10 "RockCrawlMode" 9 "MudRutsMode" 8 "SandMode" 7 "EconomyMode" 6 "GrassGravelSnow" 5 "TowHaulMode" 4 "SportMode" 3 "Normal_4L" 2 "Normal_4A" 1 "Normal_2H" 0 "NormalMode" ;
VAL_ 1242 EngExhMdeQuietCstm_D_Rq 7 "Faulty" 6 "NotUsed_2" 5 "NotUsed_1" 4 "Track" 3 "Sport" 2 "Normal" 1 "Stealth" 0 "Null" ;
VAL_ 1242 StopStrtCstm_D_Rq 3 "Faulty" 2 "On" 1 "Off" 0 "NotAvailable" ;
VAL_ 1242 SelDrvMdeCstmPt_D_Rq 31 "Faulty" 30 "NotUsed15" 29 "NotUsed14" 28 "NotUsed13" 27 "NotUsed12" 26 "NotUsed11" 25 "NotUsed10" 24 "NotUsed9" 23 "NotUsed8" 22 "NotUsed7" 21 "CustomMode" 20 "TrackMode" 19 "OnePedalDrive" 18 "EvLaterChargerMode" 17 "EvNowMode" 16 "DragMode" 15 "HighSpeedDesertMode_Baja" 14 "SportAdaptiveMode" 13 "NotAvailable_13" 12 "NotAvailable_12" 11 "NotAvailable_11" 10 "NotAvailable_10" 9 "RockCrawlMode" 8 "MudRutsMode" 7 "SandMode" 6 "EconomyMode" 5 "GrassGravelSnow" 4 "NotAvailable_04" 3 "TowHaulMode" 2 "NotAvailable_02" 1 "SportMode" 0 "NormalMode" ;
VAL_ 502 Dsp_FolderContent_Rq 2 "Inactive" 1 "RequestContentFromParentFolderOf" 0 "RequestContentFromParameterFolde" ;
VAL_ 502 Dsp_CutItem2_Rq 3 "Inactive" 2 "ThreeQuarterFromTheBeginningOneQ" 1 "End" 0 "Beginning" ;
VAL_ 502 Dsp_AudioSourceSel2_Rq 4 "Reserved" 3 "USB" 2 "BTAudio" 1 "CD" 0 "Inactive" ;
VAL_ 955 Tire_Temp_RF_Data 255 "NotSupported" 254 "Invalid" ;
VAL_ 955 Tire_Temp_ORR_Data 255 "NotSupported" 254 "Invalid" ;
VAL_ 955 Tire_Temp_OLR_Data 255 "NotSupported" 254 "Invalid" ;
VAL_ 955 Tire_Temp_LF_Data 255 "NotSupported" 254 "Invalid" ;
VAL_ 955 Tire_Temp_IRR_Data 255 "NotSupported" 254 "Invalid" ;
VAL_ 955 Tire_Temp_ILR_Data 255 "NotSupported" 254 "Invalid" ;
VAL_ 1116 TrlrAidSetup_D2_Rq 15 "NotUsed_9" 14 "NotUsed_8" 13 "NotUsed_7" 12 "NotUsed_6" 11 "NotUsed_5" 10 "NotUsed_4" 9 "NotUsed_3" 8 "NotUsed_2" 7 "NotUsed_1" 6 "CompleteSetup" 5 "ReturnToSetup" 4 "StickerNotCircled" 3 "ConfirmSetup" 2 "EndSetup" 1 "BeginSetup" 0 "Inactive" ;
VAL_ 1116 TrlrAidEnbl_D2_Rq 7 "NotUsed_4" 6 "NotUsed_3" 5 "NotUsed_2" 4 "NotUsed_1" 3 "Deactivate" 2 "ActivateTrg" 1 "ActivateTba" 0 "Inactive" ;
VAL_ 1116 TlightTest_D_Mnu 3 "TestEndAcknowledge" 2 "StartTest" 1 "StopTest" 0 "Null" ;
VAL_ 1116 TrlrRvrseCancl_B_Rq 1 "Cancel" 0 "Null" ;
VAL_ 1116 TrlrIdType_D_Stat 3 "Gooseneck" 2 "FifthWheel" 1 "Conventional" 0 "Null" ;
VAL_ 1116 TrlrAnOffstDir_D_Mem 3 "NotUSed" 2 "Right" 1 "Left_or_Center" 0 "Null" ;
VAL_ 1113 TrlrAnOffstDir_D_Calc_UB 1 "Fresh_data" 0 "Unchanged_data" ;
VAL_ 1113 TrlrAnOffst_An_Calc_UB 1 "Fresh_data" 0 "Unchanged_data" ;
VAL_ 1113 TrlrAnCalib_B_Complt_UB 1 "Fresh_data" 0 "Unchanged_data" ;
VAL_ 1113 TrlrAidTrgtId_No_Actl_UB 1 "Fresh_data" 0 "Unchanged_data" ;
VAL_ 1113 TrlrAnCalib_B_Complt 1 "Yes" 0 "No" ;
VAL_ 1113 TrlrAnOffstDir_D_Calc 3 "NotUSed" 2 "Right" 1 "Left_or_Center" 0 "Null" ;
VAL_ 1113 immoSecureIdleMode_UB 1 "Fresh_data" 0 "Unchanged_data" ;
VAL_ 1113 immoSecureIdleMode 3 "NotUsed2" 2 "NotUsed1" 1 "Active" 0 "Inactive" ;
VAL_ 1255 BalrRight4Threat_D_Stat 1 "Yes" 0 "No" ;
VAL_ 1255 BalrRight4Fast_B_Stat 1 "Yes" 0 "No" ;
VAL_ 1255 BalrRight4Dsply_B_Stat 1 "Yes" 0 "No" ;
VAL_ 1254 BalrRight3Threat_D_Stat 1 "Yes" 0 "No" ;
VAL_ 1254 BalrRight3Fast_B_Stat 1 "Yes" 0 "No" ;
VAL_ 1254 BalrRight3Dsply_B_Stat 1 "Yes" 0 "No" ;
VAL_ 1253 BalrRight2Threat_D_Stat 1 "Yes" 0 "No" ;
VAL_ 1253 BalrRight2Fast_B_Stat 1 "Yes" 0 "No" ;
VAL_ 1253 BalrRight2Dsply_B_Stat 1 "Yes" 0 "No" ;
VAL_ 1252 BalrRight1Threat_D_Stat 1 "Yes" 0 "No" ;
VAL_ 1252 BalrRight1Fast_B_Stat 1 "Yes" 0 "No" ;
VAL_ 1252 BalrRight1Dsply_B_Stat 1 "Yes" 0 "No" ;
VAL_ 1251 BalrLeft4Threat_D_Stat 1 "Yes" 0 "No" ;
VAL_ 1251 BalrLeft4Fast_B_Stat 1 "Yes" 0 "No" ;
VAL_ 1251 BalrLeft4Dsply_B_Stat 1 "Yes" 0 "No" ;
VAL_ 1250 BalrLeft3Threat_D_Stat 1 "Yes" 0 "No" ;
VAL_ 1250 BalrLeft3Fast_B_Stat 1 "Yes" 0 "No" ;
VAL_ 1250 BalrLeft3Dsply_B_Stat 1 "Yes" 0 "No" ;
VAL_ 1249 BalrLeft2Threat_D_Stat 1 "Yes" 0 "No" ;
VAL_ 1249 BalrLeft2Fast_B_Stat 1 "Yes" 0 "No" ;
VAL_ 1249 BalrLeft2Dsply_B_Stat 1 "Yes" 0 "No" ;
VAL_ 1248 BalrLeft1Threat_D_Stat 1 "Yes" 0 "No" ;
VAL_ 1248 BalrLeft1Fast_B_Stat 1 "Yes" 0 "No" ;
VAL_ 1248 BalrLeft1Dsply_B_Stat 1 "Yes" 0 "No" ;
VAL_ 1256 BalrMdeRight_D_Stat_UB 1 "Fresh_data" 0 "Unchanged_data" ;
VAL_ 1256 BalrMdeSelRight_B_Stat_UB 1 "Fresh_data" 0 "Unchanged_data" ;
VAL_ 1256 BalrRight_D_Stat_UB 1 "Fresh_data" 0 "Unchanged_data" ;
VAL_ 1256 BalrLckRight_B_Stat_UB 1 "Fresh_data" 0 "Unchanged_data" ;
VAL_ 1256 BalrChimeRight_D_Rq_UB 1 "Fresh_data" 0 "Unchanged_data" ;
VAL_ 1256 BalrSnsRight_D_Falt_UB 1 "Fresh_data" 0 "Unchanged_data" ;
VAL_ 1256 BalrWndwRight_B_Stat_UB 1 "Fresh_data" 0 "Unchanged_data" ;
VAL_ 1256 BalrLckRight_B_Stat 1 "Enable" 0 "Disable" ;
VAL_ 1256 BalrWndwRight_B_Stat 1 "Enable" 0 "Disable" ;
VAL_ 1256 BalrMdeSelRight_B_Stat 1 "Enable" 0 "Disable" ;
VAL_ 1256 BalrSnsRight_D_Falt 3 "Invalid" 2 "SystemFailure" 1 "Blocked" 0 "Clear" ;
VAL_ 1256 BalrChimeRight_D_Rq 3 "NotUsed" 2 "Soft" 1 "Normal" 0 "Off" ;
VAL_ 1256 BalrMdeRight_D_Stat 3 "NotUsed" 2 "High" 1 "Medium" 0 "Low" ;
VAL_ 1256 BalrRight_D_Stat 3 "Inhibited" 2 "Disabled" 1 "On" 0 "Off" ;
VAL_ 1256 BalrWndwLeft_B_Stat_UB 1 "Fresh_data" 0 "Unchanged_data" ;
VAL_ 1256 BalrSnsLeft_D_Falt_UB 1 "Fresh_data" 0 "Unchanged_data" ;
VAL_ 1256 BalrMdeSelLeft_B_Stat_UB 1 "Fresh_data" 0 "Unchanged_data" ;
VAL_ 1256 BalrMdeLeft_D_Stat_UB 1 "Fresh_data" 0 "Unchanged_data" ;
VAL_ 1256 BalrLeft_D_Stat_UB 1 "Fresh_data" 0 "Unchanged_data" ;
VAL_ 1256 BalrLckLeft_B_Stat_UB 1 "Fresh_data" 0 "Unchanged_data" ;
VAL_ 1256 BalrChimeLeft_D_Rq_UB 1 "Fresh_data" 0 "Unchanged_data" ;
VAL_ 1256 BalrLeft_D_Stat 3 "Inhibited" 2 "Disabled" 1 "On" 0 "Off" ;
VAL_ 1256 BalrMdeSelLeft_B_Stat 1 "Enable" 0 "Disable" ;
VAL_ 1256 BalrLckLeft_B_Stat 1 "Enable" 0 "Disable" ;
VAL_ 1256 BalrWndwLeft_B_Stat 1 "Enable" 0 "Disable" ;
VAL_ 1256 BalrMdeLeft_D_Stat 3 "NotUsed" 2 "High" 1 "Medium" 0 "Low" ;
VAL_ 1256 BalrSnsLeft_D_Falt 3 "Invalid" 2 "SystemFailure" 1 "Blocked" 0 "Clear" ;
VAL_ 1256 BalrChimeLeft_D_Rq 3 "NotUsed" 2 "Soft" 1 "Normal" 0 "Off" ;
VAL_ 1256 WakeAlarm2_D_Stat_UB 1 "Fresh_data" 0 "Unchanged_data" ;
VAL_ 1256 WakeAlarm2_D_Stat 3 "PublisherReset" 2 "Wake" 1 "AlarmRunning" 0 "AlarmOff" ;
VAL_ 529 OnbChrgToPcWknd_D_Actl 7 "Percent_50" 6 "Percent_60" 5 "Percent_70" 4 "Percent_80" 3 "Percent_85" 2 "Percent_90" 1 "Percent_95" 0 "Percent_100" ;
VAL_ 529 OnbChrgToPcWkdy_D_Actl 7 "Percent_50" 6 "Percent_60" 5 "Percent_70" 4 "Percent_80" 3 "Percent_85" 2 "Percent_90" 1 "Percent_95" 0 "Percent_100" ;
VAL_ 529 OnbChrgSetNow_D_Rq 3 "NotUsed" 2 "On" 1 "Off" 0 "Null" ;
VAL_ 529 OnbChrgSetDelete_B_Rq 1 "Request" 0 "NoRequest" ;
VAL_ 529 OnbChrgPrflUpdate_B_Rq 1 "Request" 0 "NoRequest" ;
VAL_ 529 OnbChrgLocIdUns_B_Rq 1 "Request" 0 "NoRequest" ;
VAL_ 642 SldrrMsgTxt_D2_Rq_UB 1 "Fresh_data" 0 "Unchanged_data" ;
VAL_ 642 SldrrMsgTxt_D2_Rq 7 "NotUsed_3" 6 "NotUsed_2" 5 "NotUsed_1" 4 "SlidingDrCalibNeeded2" 3 "SlidingDrOpenCltchReleased" 2 "SlidingDrCalibNeeded" 1 "SlidingDrClutchReleased" 0 "Null" ;
VAL_ 642 SldrrChime_D_Rq_UB 1 "Fresh_data" 0 "Unchanged_data" ;
VAL_ 642 SldrrChime_D_Rq 7 "NotUsed3" 6 "NotUsed2" 5 "NotUsed1" 4 "Warning" 3 "WarningRepeated" 2 "Programming" 1 "Operation" 0 "Off" ;
VAL_ 642 SldrlMsgTxt_D2_Rq_UB 1 "Fresh_data" 0 "Unchanged_data" ;
VAL_ 642 SldrlMsgTxt_D2_Rq 7 "NotUsed_3" 6 "NotUsed_2" 5 "NotUsed_1" 4 "SlidingDrCalibNeeded2" 3 "SlidingDrOpenCltchReleased" 2 "SlidingDrCalibNeeded" 1 "SlidingDrClutchReleased" 0 "Null" ;
VAL_ 642 SldrlChime_D_Rq_UB 1 "Fresh_data" 0 "Unchanged_data" ;
VAL_ 642 SldrlChime_D_Rq 7 "NotUsed3" 6 "NotUsed2" 5 "NotUsed1" 4 "Warning" 3 "WarningRepeated" 2 "Programming" 1 "Operation" 0 "Off" ;
VAL_ 642 PaakMyKeySearch_D_Stat_UB 1 "Fresh_data" 0 "Unchanged_data" ;
VAL_ 642 UreaLvlQlty_D_RqDsply_UB 1 "Fresh_data" 0 "Unchanged_data" ;
VAL_ 642 DieslPrtcWarn_D_Rq_UB 1 "Fresh_data" 0 "Unchanged_data" ;
VAL_ 642 UreaQltySysWarn_D_Rq_UB 1 "Fresh_data" 0 "Unchanged_data" ;
VAL_ 642 UreaLvlTxtWarn_D_Rq_UB 1 "Fresh_data" 0 "Unchanged_data" ;
VAL_ 642 UreaLvlQlty_D_RqDsply 7 "NotUsed_5" 6 "NotUsed_4" 5 "NotUsed_3" 4 "NotUsed_2" 3 "NotUsed_1" 2 "FlashChime" 1 "On" 0 "Off" ;
VAL_ 642 UreaLvlTxtWarn_D_Rq 15 "NotUsed_4" 14 "NotUsed_3" 13 "NotUsed_2" 12 "NotUsed_1" 11 "System_Error" 10 "Engine_Idled_See_Manual" 9 "Engine_Idled_Upon_Refuel" 8 "Speed_Limited_To_XX_mph" 7 "XXmph_Max_Upon_Restart" 6 "Speed_Limited_To_YY_mph" 5 "YYmph_Max_Upon_Restart" 4 "SpdLimtd_YYmph_In_XXmiles" 3 "ExFlRange_XXMiles_ScndWarn" 2 "Exh_Fluid_Range_XX_Miles" 1 "Exh_Fluid_Under_Half_Full" 0 "Exh_Fluid_Over_Half_Full" ;
VAL_ 642 UreaQltySysWarn_D_Rq 7 "Undefined" 6 "ZZ_Overrides" 5 "EngineIdled" 4 "Engine_Idle_Upon_Refuel" 3 "SPEED_LIMITED_to_YY_mph" 2 "YY_MPH_MAX_UPON_Restart" 1 "CONTAMINATED_ExhFluid" 0 "NoQualityProblem" ;
VAL_ 642 DieslPrtcWarn_D_Rq 15 "NotUsed_4" 14 "NotUsed_3" 13 "NotUsed_2" 12 "NotUsed_1" 11 "OCR_ExhFilterClean_Stopped" 10 "OCR_ExhFilterCleaned" 9 "RgnOff_AtLimit" 8 "RgnOff_OverLoaded" 7 "RgnOff_Loaded" 6 "Exhaust_Filter_Full" 5 "DPF_OverLimit" 4 "DPF_AtLimit" 3 "ExhFilter_Drive_Completed" 2 "Cleaning_Exhaust_Filter" 1 "DPF_OverLoaded" 0 "DPF_Normal_Operation" ;
VAL_ 642 KeyMyKeyTot_No2_Cnt_UB 1 "Fresh_data" 0 "Unchanged_data" ;
VAL_ 642 KeyAdmnTot_No2_Cnt_UB 1 "Fresh_data" 0 "Unchanged_data" ;
VAL_ 642 DcChrgSrvcRqd_B_Rq_UB 1 "Fresh_data" 0 "Unchanged_data" ;
VAL_ 642 DcChrgSrvcRqd_B_Rq 1 "On" 0 "Off" ;
VAL_ 642 PaakMyKeySearch_D_Stat 7 "PhoneErased" 6 "LockButtonTimeOut" 5 "PressLockButton" 4 "ConfirmHmi" 3 "MyKeyPaakFound" 2 "StandardPaakFound" 1 "NoValidPaakFound" 0 "Null" ;
VAL_ 642 GrdAsstActv_B_Stat_UB 1 "Fresh_data" 0 "Unchanged_data" ;
VAL_ 642 GrdAsstActv_B_Stat 1 "On" 0 "Off" ;
VAL_ 642 TrlrAidTrlrId_No_Rq_UB 1 "Fresh_data" 0 "Unchanged_data" ;
VAL_ 893 RngPerChrgAvg_L2_Dsply_UB 1 "Fresh_data" 0 "Unchanged_data" ;
VAL_ 893 RngImpctClim_L_Dsply_UB 1 "Fresh_data" 0 "Unchanged_data" ;
VAL_ 893 RngImpctDrv_L_Dsply_UB 1 "Fresh_data" 0 "Unchanged_data" ;
VAL_ 893 VehElEffAvg_No_Dsply_UB 1 "Fresh_data" 0 "Unchanged_data" ;
VAL_ 893 VehElEffAvg_No_Dsply 127 "Faulty" 126 "NoDataExists" ;
VAL_ 893 RngPerChrgAvg_L2_Dsply 8191 "Faulty" 8190 "NoDataExists" ;
VAL_ 893 TrnAout2_W_ActlUnfilt_UB 1 "Fresh_data" 0 "Unchanged_data" ;
VAL_ 893 TrnAout2_W_ActlUnfilt 65535 "Fault" 65534 "NoDataExists" ;
VAL_ 500 Dsp_GetCDTOCDData_Rq 0 "Inactive" 2 "Off" 1 "TOC" ;
VAL_ 500 Dsp_CutItem_Rq 3 "Inactive" 2 "ThreeQuarterFromTheBeginningOneQ" 1 "End" 0 "Beginning" ;
VAL_ 500 Dsp_AudioSourceSel_Rq 5 "SDCard" 4 "Reserved" 3 "USB" 2 "BTAudio" 1 "CD" 0 "Inactive" ;
VAL_ 503 Dsp_AudioSourceSel3_Rq 3 "USB" 2 "BTAudio" 1 "CD" 0 "Inactive" ;
VAL_ 493 Dsp_StatLiScanCancel_Rq 1 "Cancel" 0 "Inactive" ;
VAL_ 493 Dsp_StationList_Rq 15 "reserved_last" 8 "reserved" 7 "DAB_Service_List" 6 "DAB_Ensemble_Service_List" 5 "Analog_FM_PTY_List" 4 "Analog_and_HD_FM_List" 3 "HD_FM_List" 2 "Analog_FM_List" 1 "Analog_AM_List" 0 "Inactive" ;
VAL_ 493 Dsp_RefreshFlag 1 "True" 0 "False" ;
VAL_ 493 Dsp_AFJump_Rq 2 "Enable" 1 "Inhibit" 0 "Inactive" ;
